VERSION ""

NS_ :

BS_:

BU_: GWM SCMB_PSM HVAC_RCCM GENERIC_GWMWakeup SOBDMD_AHCM_FOH TRM _delete SODL RTM PDM SCMH SCMG RSM SODR DDM RGTM DSM SCME TSTR
VAL_TABLE_ HvacCmprLim_D_Stat 7 "NotUsed_2" 6 "NotUsed_1" 5 "CompressorHeadPressure" 4 "AvailableTorque" 3 "PedalPosition" 2 "RPM" 1 "ECT" 0 "NoLimit" ;
VAL_TABLE_ NoMessage_Msg1_63 31 "Message31" 30 "Message30" 29 "Message29" 28 "Message28" 27 "Message27" 26 "Message26" 25 "Message25" 24 "Message24" 23 "Message23" 22 "Message22" 21 "Message21" 20 "Message20" 19 "Message19" 18 "Message18" 17 "Message17" 16 "Message16" 15 "Message15" 14 "Message14" 13 "Message13" 12 "Message12" 11 "Message11" 10 "Message10" 9 "Message9" 8 "Message8" 7 "Message7" 6 "Message6" 5 "Message5" 4 "Message4" 3 "Message3" 2 "Message2" 1 "Message1" 0 "NoMessage" ;
VAL_TABLE_ TrlrRvrseEnbl_D2_Stat 7 "NotUsed" 6 "TbaActiveExpertActive" 5 "TbaActiveExpertAvail" 4 "TbaOffTrgActive" 3 "TbaOffTrgSetup" 2 "TbaSetup" 1 "TbaActive" 0 "Inactive" ;
VAL_TABLE_ SwitchNotActive_Active 1 "Switch_Active" 0 "Switch_Not_Active" ;
VAL_TABLE_ LcwaLeft_D_Stat 7 "Faulty" 6 "NotUsed_3" 5 "NotUsed_2" 4 "NotUsed_1" 3 "Disabled" 2 "TemporaryUnavailable" 1 "SensorBlocked" 0 "Available" ;
VAL_TABLE_ SeatMasgDrvRr_D_Stat 15 "NotUsed_10" 14 "NotUsed_9" 13 "NotUsed_8" 12 "NotUsed_7" 11 "NotUsed_6" 10 "NotUsed_5" 9 "NotUsed_4" 8 "NotUsed_3" 7 "NotUsed_2" 6 "NotUsed_1" 5 "Pattern5" 4 "Pattern4" 3 "Pattern3" 2 "Pattern2" 1 "Pattern1" 0 "Null" ;
VAL_TABLE_ CamraRearOn_D2_Stat2 7 "Faulty" 6 "NotUsed_3" 5 "NotUsed_2" 4 "NotUsed_1" 3 "Decommission" 2 "Activate" 1 "Deactivate" 0 "Null" ;
VAL_TABLE_ AirCondClu_D_Stat 7 "NotUsed" 6 "FetLifeLimitReached" 5 "FetOpenCircuit" 4 "FetOutputShortToPower" 3 "FetOutputShortToGround" 2 "FetNotControlled" 1 "OnPowerToLoad" 0 "OffNoPowerToLoad" ;
VAL_TABLE_ OffNormalSoft 3 "NotUsed" 2 "Soft" 1 "Normal" 0 "Off" ;
VAL_TABLE_ OffOnDisabledInhibited 3 "Inhibited" 2 "Disabled" 1 "On" 0 "Off" ;
VAL_TABLE_ SldrrMsgTxt_D2_Rq 7 "NotUsed_3" 6 "NotUsed_2" 5 "NotUsed_1" 4 "SlidingDrCalibNeeded2" 3 "SlidingDrOpenCltchReleased" 2 "SlidingDrCalibNeeded" 1 "SlidingDrClutchReleased" 0 "Null" ;
VAL_TABLE_ SeatPsngrMem_D_Cmd 15 "NotUsed_7" 14 "NotUsed_6" 13 "NotUsed_5" 12 "NotUsed_4" 11 "NotUsed_3" 10 "NotUsed_2" 9 "NotUsed_1" 8 "RECALL_4" 7 "RECALL_3" 6 "RECALL_2" 5 "RECALL_1" 4 "STORE_4" 3 "STORE_3" 2 "STORE_2" 1 "STORE_1" 0 "Null" ;
VAL_TABLE_ Null_NoFault_Fault 3 "NotUsed" 2 "Fault" 1 "NoFault" 0 "Null" ;
VAL_TABLE_ PrkAsstSlotId_D_Stat 7 "Faulty" 6 "Slot6" 5 "Slot5" 4 "Slot4" 3 "Slot3" 2 "Slot2" 1 "Slot1" 0 "NoSlotFound" ;
VAL_TABLE_ PwStepLeft_D_Rq 1 "Deploy" 0 "Null" 3 "NotUsed" 2 "Stow" ;
VAL_TABLE_ SldrlUnlckSwtch_D_Stat 3 "InnerHandle" 2 "RearInteriorSwitch" 1 "IpSwitch" 0 "Null" ;
VAL_TABLE_ SldrlChime_D_Rq 7 "NotUsed3" 6 "NotUsed2" 5 "NotUsed1" 4 "Warning" 3 "WarningRepeated" 2 "Programming" 1 "Operation" 0 "Off" ;
VAL_TABLE_ Sldrl_D_Stat 3 "NotCalibrated" 2 "Closing" 1 "Opening" 0 "NotMoving" ;
VAL_TABLE_ BalrInnrLeft_D_Stat 3 "Reporting" 2 "NotReporting" 1 "SystemStandby" 0 "Initialization" ;
VAL_TABLE_ Zero_1_2_4 3 "Four" 2 "Two" 1 "One" 0 "Zero" ;
VAL_TABLE_ NoReq_AutoUp_Stop 3 "NotUsed" 2 "Stop" 1 "AutoUp" 0 "NoRequest" ;
VAL_TABLE_ BalrSnsLeft_D_Falt 3 "Invalid" 2 "SystemFailure" 1 "Blocked" 0 "Clear" ;
VAL_TABLE_ Null_Low_Med_High 3 "High" 2 "Medium" 1 "Low" 0 "Null" ;
VAL_TABLE_ Null_NotPressed_Pressed 3 "NotUsed" 2 "Pressed" 1 "NotPressed" 0 "Null" ;
VAL_TABLE_ Low_Med_High 3 "NotUsed" 2 "High" 1 "Medium" 0 "Low" ;
VAL_TABLE_ TrlrAidMsgTxt_D2_Rq 63 "Message63" 62 "Message62" 61 "Message61" 60 "Message60" 55 "Message55" 50 "Message50" 45 "Message45" 40 "Message40" 35 "Message35" 31 "Message31" 30 "Message30" 29 "Message29" 28 "Message28" 27 "Message27" 26 "Message26" 25 "Message25" 24 "Message24" 23 "Message23" 22 "Message22" 21 "Message21" 20 "Message20" 19 "Message19" 18 "Message18" 17 "Message17" 16 "Message16" 15 "Message15" 14 "Message14" 13 "Message13" 12 "Message12" 11 "Message11" 10 "Message10" 9 "Message9" 8 "Message8" 7 "Message7" 6 "Message6" 5 "Message5" 4 "Message4" 3 "Message3" 2 "Message2" 1 "Message1" 0 "NoMessage" ;
VAL_TABLE_ TrlrAidEnbl_D2_Stat 7 "NotUsed_1" 6 "TbaActiveExpertActive" 5 "TbaActiveExpertAvail" 4 "TbaOffTrgActive" 3 "TbaOffTrgSetup" 2 "TbaSetup" 1 "TbaActive" 0 "Inactive" ;
VAL_TABLE_ RbaCta_D_Stat 7 "Faulty" 6 "NotUsed_2" 5 "NotUsed_1" 4 "Invalid" 3 "Disabled" 2 "On" 1 "Trailer_Tow_Off" 0 "Off" ;
VAL_TABLE_ SeatFnChng2 15 "Faulty" 14 "NotUsed9" 13 "NotUsed8" 12 "NotUsed7" 11 "NotUsed6" 10 "High_2" 9 "Med_2" 8 "Low_2" 7 "Off_2" 6 "High" 5 "Low" 4 "Off" 3 "Decrease" 2 "Increase" 1 "NotUsed1" 0 "Inactive" ;
VAL_TABLE_ OffOnDisabledNotUsed 3 "NotUsed" 2 "Disabled" 1 "On" 0 "Off" ;
VAL_TABLE_ RbaSys_D_Stat 3 "Faulty" 2 "Available" 1 "Suspended" 0 "Disabled" ;
VAL_TABLE_ SeatLmbr_D_Rq 15 "NotUsed_7" 14 "NotUsed_6" 13 "NotUsed_5" 12 "NotUsed_4" 11 "NotUsed_3" 10 "NotUsed_2" 9 "NotUsed_1" 8 "PassengerDown" 7 "PassengerUp" 6 "PassengerAft" 5 "PassengerFore" 4 "DriverDown" 3 "DriverUp" 2 "DriverAft" 1 "DriverFore" 0 "Null" ;
VAL_TABLE_ Inactive_Enable_Disable 0 "Inactive" 2 "Disable" 1 "Enable" ;
VAL_TABLE_ PmSnsCabn_D_Stat 7 "NotUsed_1" 6 "IntermittentInhibit" 5 "NoIssue" 4 "BlankField" 3 "ReplaceSensor" 2 "CleanSensor" 1 "Unsupported" 0 "Initializing" ;
VAL_TABLE_ Null_Off_LowMedHigh 7 "NotUsed_3" 6 "NotUsed_2" 5 "NotUsed_1" 4 "High" 3 "Medium" 2 "Low" 1 "Off" 0 "Null" ;
VAL_TABLE_ SeatMasgDrv_D_Stat 15 "NotUsed_10" 14 "NotUsed_9" 13 "NotUsed_8" 12 "NotUsed_7" 11 "NotUsed_6" 10 "NotUsed_5" 9 "NotUsed_4" 8 "NotUsed_3" 7 "NotUsed_2" 6 "NotUsed_1" 5 "Pattern5" 4 "Pattern4" 3 "Pattern3" 2 "Pattern2" 1 "Pattern1" 0 "Null" ;
VAL_TABLE_ ClimtSeat_D_Rq 128 "H3_High_Heat_MAX" 64 "H2_Medium_Heat" 32 "H1_Low_Heat" 16 "C3_High_Cool_MAX" 8 "C2_Medium_Cool" 4 "C1_Low_Cool" 2 "Off" ;
VAL_TABLE_ ClimtRearView_D_Stat 3 "ThirdRow" 2 "SecondRow" 1 "Both" 0 "NotDisplayed" ;
VAL_TABLE_ PersRecallSrc_D_Actl 7 "NotUsed_3" 6 "NotUsed_2" 5 "NotUsed_1" 4 "MemorySwitch" 3 "RemoteStart" 2 "KeyFob" 1 "CenterStack" 0 "Null" ;
VAL_TABLE_ OKLowUnknownInvalid 3 "Invalid" 2 "Unknown" 1 "Low" 0 "OK" ;
VAL_TABLE_ Dsp_RotAddrBtnEv_St 15 "NotUsed_1" 14 "Pos_7Steps" 13 "Pos_6Steps" 12 "Pos_5Steps" 11 "Pos_4Steps" 10 "Pos_3Steps" 9 "Pos_2Steps" 8 "Pos_1Step" 7 "NotPressed" 6 "Neg_1Steps" 5 "Neg_2Steps" 4 "Neg_3Steps" 3 "Neg_4Steps" 2 "Neg_5Steps" 1 "Neg_6Steps" 0 "Neg_7Steps" ;
VAL_TABLE_ Pers1Phone_D_Stat 7 "SevenPhoneAssociated" 6 "SixPhoneAssociated" 5 "FivePhoneAssociated" 4 "FourPhoneAssociated" 3 "ThreePhoneAssociated" 2 "TwoPhoneAssociated" 1 "OnePhoneAssociated" 0 "NoPhoneAssociated" ;
VAL_TABLE_ GasPrtc_D_RqDsply 7 "NotUsed_5" 6 "NotUsed_4" 5 "NotUsed_3" 4 "NotUsed_2" 3 "NotUsed_1" 2 "GpfOverLimit" 1 "GpfAtLimit" 0 "NormalOperation" ;
VAL_TABLE_ Memory_2_SwPsngr_Stat 1 "Pressed" 0 "Null" ;
VAL_TABLE_ Pers3Key_D_Stat 3 "NotUsed_1" 2 "KeyUnAssociated" 1 "KeyAssociated" 0 "Null" ;
VAL_TABLE_ EmButtn_D_Stat 7 "ButtonAssociationFailed" 6 "ButtonAssociationExited" 5 "ButtonAssociationEntered" 4 "Button4Pressed" 3 "Button3Pressed" 2 "Button2Pressed" 1 "Button1Pressed" 0 "Null" ;
VAL_TABLE_ EmPrflButtnAssoc_D_Rq 3 "NotUsed" 2 "ExitButtonAssociation" 1 "EnterButtonAssociation" 0 "Null" ;
VAL_TABLE_ EmPrflNo_D_Stat 7 "NotUsed_3" 6 "NotUsed_2" 5 "NotUsed_1" 4 "Pers4" 3 "Pers3" 2 "Pers2" 1 "Pers1" 0 "Null" ;
VAL_TABLE_ EmPrflKeyAssoc_D_Stat 7 "WrongDevice" 6 "KeyAssociateFailed" 5 "KeyAssociateSuccess" 4 "KeyAlreadyInUse" 3 "KeyDisassociated" 2 "KeyAssociationExited" 1 "KeyAssociationEntered" 0 "Null" ;
VAL_TABLE_ PersNo_D_Actl 7 "Unused_3" 6 "Unused_2" 5 "NotDetermined" 4 "Vehicle" 3 "PERS_4" 2 "PERS_3" 1 "PERS_2" 0 "PERS_1" ;
VAL_TABLE_ Closed_Open_Active_Denied 3 "Denied" 2 "Active" 1 "Open" 0 "Closed" ;
VAL_TABLE_ KeyOffMde_D_Actl 15 "NotUsed_11" 14 "NotUsed_10" 13 "NotUsed_9" 12 "NotUsed_8" 11 "NotUsed_7" 10 "NotUsed_6" 9 "NotUsed_5" 8 "NotUsed_4" 7 "NotUsed_3" 6 "NotUsed_2" 5 "NotUsed_1" 4 "CriticalBattery" 3 "Hibernate" 2 "Transport" 1 "Factory" 0 "Normal" ;
VAL_TABLE_ SelDrvMdeSwtch 3 "Faulty" 2 "SwitchState2" 1 "SwitchState1" 0 "NotPressed" ;
VAL_TABLE_ SelDrvMdePt_D_Rq 31 "Faulty" 30 "NotUsed15" 29 "NotUsed14" 28 "NotUsed13" 27 "NotUsed12" 26 "NotUsed11" 25 "NotUsed10" 24 "NotUsed9" 23 "NotUsed8" 22 "NotUsed7" 21 "NotUsed6" 20 "NotUsed5" 19 "NotUsed4" 18 "EvLaterChargerMode" 17 "EvNowMode" 16 "DragMode" 15 "HighSpeedDesertMode_Baja" 14 "SportAdaptiveMode" 13 "NotAvailable_13" 12 "NotAvailable_12" 11 "NotAvailable_11" 10 "NotAvailable_10" 9 "RockCrawlMode" 8 "MudRutsMode" 7 "SandMode" 6 "EconomyMode" 5 "GrassGravelSnow" 4 "NotAvailable_04" 3 "TowHaulMode" 2 "NotAvailable_02" 1 "SportMode" 0 "NormalMode" ;
VAL_TABLE_ OffLockUnlockFaulty 3 "Faulty" 2 "Unlock" 1 "Lock" 0 "Off" ;
VAL_TABLE_ PwStep_D_Stat 3 "PositionNotKnown" 2 "StepsNotStowed" 1 "StepsStowed" 0 "Off" ;
VAL_TABLE_ PwStep_D_DrvInhbt 3 "NotUsed" 2 "DriveInhibitMalfunction" 1 "DriveInhibited" 0 "DriveNotInhibited" ;
VAL_TABLE_ PwStepMsgTxt_D_Rq 1 "DriveInhibited" 0 "NoMessage" 3 "NotUsed" 2 "Malfunction" ;
VAL_TABLE_ OffLowMedHigh 3 "High" 2 "Medium" 1 "Low" 0 "Off" ;
VAL_TABLE_ ApaSteScanMde_D_Stat 3 "Steering" 2 "Scanning" 1 "NotScanning" 0 "Null" ;
VAL_TABLE_ Off_On_Unknown_Invalid 3 "Invalid" 2 "Unknown" 1 "On" 0 "Off" ;
VAL_TABLE_ HeadLghtOn_D_Rq 7 "NotUsed2" 6 "NotUsed1" 5 "DrlBoth" 4 "DrlRight" 3 "DrlLeft" 2 "High" 1 "Low" 0 "Off" ;
VAL_TABLE_ SeatPos_D_Stat 7 "NotUsed3" 6 "NotUsed2" 5 "Error" 4 "Drive" 3 "Moving" 2 "Pending" 1 "EasyEntry" 0 "Null" ;
VAL_TABLE_ CtaAlrt2_D_Stat 7 "NotUsed3" 6 "NotUsed2" 5 "NotUsed1" 4 "AlertZone4" 3 "AlertZone3" 2 "AlertZone2" 1 "AlertZone1" 0 "Off" ;
VAL_TABLE_ BttRightLeft_D_Stat 7 "NotUsed" 6 "Disabled" 5 "Off" 4 "OffTemp" 3 "NotConnected" 2 "Pending" 1 "Connected" 0 "NotDetermined" ;
VAL_TABLE_ Null_NoRequest_Request 3 "NotUsed" 2 "Request" 1 "NoRequest" 0 "Null" ;
VAL_TABLE_ LghtAmbIntns_D_Sns 3 "Faulty" 2 "High" 1 "Low" 0 "Null" ;
VAL_TABLE_ ACU_RadioSeekMode2_St 16 "ContAutoDown" 15 "ContAutoUp" 14 "PISeek" 13 "TpSeek" 12 "Autostore" 11 "PtySeekDown" 10 "PtySeekUp" 9 "ScanDown" 8 "ScanUp" 7 "ContManualDown" 6 "ContManualUp" 5 "ManSingleStepDown" 4 "ManSingleStepUp" 3 "AutoDown" 2 "AutoUp" 1 "SeekOff" 0 "Invalid" ;
VAL_TABLE_ ACU_CurrTUBand_St 10 "SAT2" 9 "SAT1" 8 "DAB2" 7 "DAB1" 6 "Fm3" 5 "AmAst" 4 "Am" 3 "FmAst" 2 "Fm2" 1 "Fm1" 0 "Invalid" 13 "reserved1" 15 "reserved_last" 12 "DAB3" 11 "SAT3" ;
VAL_TABLE_ SuspDrvMde_D_Rq 7 "Faulty" 6 "NotUsed2" 5 "NotUsed1" 4 "Drag" 3 "Track" 2 "Snow_Wet" 1 "Sport" 0 "Normal" ;
VAL_TABLE_ NotPressed_PressedNotUsed 3 "NotUsed2" 2 "NotUsed1" 1 "Pressed" 0 "Not_Pressed" ;
VAL_TABLE_ NotInstalled_Installed_Faulty 3 "Faulty" 2 "NotUsed" 1 "Installed" 0 "NotInstalled" ;
VAL_TABLE_ CnvtTopMsgTxt_D_Rq 3 "NotSecure" 2 "NotAvailable" 1 "RemoveCaps" 0 "NoWarning" ;
VAL_TABLE_ NoModeSelOffOnNotUsed 3 "NotUsed" 2 "On" 1 "Off" 0 "NoModeSelected" ;
VAL_TABLE_ LsmcBrkDecel_D_Stat 7 "NotUsed_3" 6 "NotUsed_2" 5 "NotUsed_1" 4 "Denied" 3 "FaultDegraded" 2 "FaultExt" 1 "On" 0 "Off" ;
VAL_TABLE_ OffOn_RampUpDown 3 "Ramp_Down" 2 "Ramp_Up" 1 "On" 0 "Off" ;
VAL_TABLE_ Rr_Btn_Status 31 "NotUsed15" 30 "NotUsed14" 29 "NotUsed13" 28 "NotUsed12" 27 "NotUsed11" 26 "NotUsed10" 25 "NotUsed9" 24 "Third_Synch_Pressed" 23 "Third_Rr_Pwr_Pressed" 22 "Third_Auto_Pressed" 21 "Third_Pnl_Flr_Pressed" 20 "Third_Floor_Pressed" 19 "Third_Panel_Pressed" 18 "Third_Blwr_Dec_Pressed" 17 "Third_Blwr_Inc_Pressed" 16 "Rear_Lock_Pressed" 15 "RHS_Cld_Seat_Pressed" 14 "LHS_Cld_Seat_Pressed" 13 "RHS_Htd_Seat_Pressed" 12 "LHS_Htd_Seat_Pressed" 11 "Rear_Power_Pressed" 10 "AUTO_Pressed" 9 "Blwr_Dec_Pressed" 8 "Blwr_Inc_Pressed" 7 "RHS_Temp_Dec_Pressed" 6 "RHS_Temp_Inc_Pressed" 5 "LHS_Temp_Dec_Pressed" 4 "LHS_Temp_Inc_Pressed" 3 "Floor_Pressed" 2 "Panel_Floor_Pressed" 1 "Panel_Pressed" 0 "None_Pressed" ;
VAL_TABLE_ NoMessage_Msg1_7 7 "Message7" 6 "Message6" 5 "Message5" 4 "Message4" 3 "Message3" 2 "Message2" 1 "Message1" 0 "NoMessage" ;
VAL_TABLE_ LnchCtl 3 "NotUsed2" 2 "NotUsed1" 1 "LC_On" 0 "LC_Off" ;
VAL_TABLE_ LnchCtlSys_D_Stat 7 "NotUsed3" 6 "NotUsed2" 5 "NotUsed1" 4 "On_LC_Unavailable_TC_On" 3 "On_LC_Unavailable" 2 "On_LC_Available" 1 "On_LC_Active" 0 "LC_OFF" ;
VAL_TABLE_ NotPressed_Pressed_Faulty 3 "Faulty" 2 "NotUsed" 1 "Pressed" 0 "Not_Pressed" ;
VAL_TABLE_ IsaOffst_D_Stat 15 "Faulty" 14 "Null" 13 "Thirteen" 12 "Twelve" 11 "Eleven" 10 "Ten" 9 "Nine" 8 "Eight" 7 "Seven" 6 "Six" 5 "Five" 4 "Four" 3 "Three" 2 "Two" 1 "One" 0 "Zero" ;
VAL_TABLE_ SlMde_D_Rq 3 "IsaNotConfigured" 2 "Manual_Mode" 1 "Auto_Mode" 0 "Null" ;
VAL_TABLE_ OffOn_NotUsed_NoData 3 "No_Data_Present" 2 "NotUsed" 1 "On" 0 "Off" ;
VAL_TABLE_ BrkDrvMde_D_Rq 7 "Faulty" 6 "RockCrawl" 5 "Baja" 4 "DragOrMudAndSand" 3 "Track" 2 "Snow_Wet" 1 "Sport" 0 "Normal" ;
VAL_TABLE_ Null_Off_On 3 "NotUsed" 2 "On" 1 "Off" 0 "Null" ;
VAL_TABLE_ Faulty_1FFF 8191 "Faulty" ;
VAL_TABLE_ VehStab_D_Stat 15 "Faulty" 14 "No_Data_Exists" 13 "NotUsed6" 12 "NotUsed5" 11 "NotUsed4" 10 "NotUsed3" 9 "NotUsed2" 8 "NotUsed1" 7 "High_SSRA_no_OS" 6 "Straight" 5 "Post_Oversteer" 4 "Post_Transition" 3 "Countersteer" 2 "Understeer" 1 "Oversteer" 0 "Linear" ;
VAL_TABLE_ CnvtTopTrgt_D_Rq 7 "NotUsed4" 6 "NotUsed3" 5 "NotUsed2" 4 "NotUsed1" 3 "OpenTarget" 2 "OpenPosition" 1 "ClosePosition" 0 "CloseTarget" ;
VAL_TABLE_ CnvtTopPos_D_Stat 15 "Faulty" 14 "NotUsed7" 13 "NotUsed6" 12 "NotUsed5" 11 "NotUsed4" 10 "NotUsed3" 9 "NotUsed2" 8 "NotUsed1" 7 "ShutdownComplete" 6 "NoNormalised" 5 "Moving" 4 "PositionIntermediate" 3 "PositionOpenTarget" 2 "PositionOpenPosition" 1 "PositionClosePosition" 0 "PositionCloseTarget" ;
VAL_TABLE_ CnvtTopPar_D_Rq 7 "NotUsed" 6 "ForceIncrease3" 5 "ForceIncrease2" 4 "ForceIncrease1" 3 "NoAdapt" 2 "Teach" 1 "NoPwmNoAp" 0 "Normal" ;
VAL_TABLE_ CnvtTopComplt_D_Stat 7 "DenormalizingReady" 6 "NormalizingReady" 5 "RunoutComplete" 4 "StopByPositioning" 3 "StopByFault" 2 "StopByPinch" 1 "StopByStall" 0 "StopByRequest" ;
VAL_TABLE_ Inactive_Active_NotUsed_Faulty 3 "Faulty" 2 "NotUsed" 1 "Active" 0 "Inactive" ;
VAL_TABLE_ CnvtTop_D_Rq 7 "NotUsed" 6 "ResetErrorFlags" 5 "DiscardNormalization" 4 "SetNormalization" 3 "DirectDriveClose" 2 "DirectDriveOpen" 1 "DirectPosition" 0 "Stop" ;
VAL_TABLE_ NoData_Faulty_1FF_1FE 511 "Faulty" 510 "NoDataExists" ;
VAL_TABLE_ FohEng_D_Rq 3 "AutoEnable_ParkEnable" 2 "AutoDisable_ParkEnable" 1 "AutoEnable_ParkDisable" 0 "Disable_Stop" ;
VAL_TABLE_ Null_Hi_NotUsed_Low 3 "Low" 2 "Not_Used" 1 "High" 0 "Null" ;
VAL_TABLE_ Current_Color 15 "NotUsed7" 14 "NotUsed6" 13 "NotUsed5" 12 "NotUsed4" 11 "NotUsed3" 10 "NotUsed2" 9 "NotUsed1" 8 "Null" 7 "Color7" 6 "Color6" 5 "Color5" 4 "Color4" 3 "Color3" 2 "Color2" 1 "Color1" 0 "Off" ;
VAL_TABLE_ Blended_Color 15 "NotUsed10" 14 "NotUsed9" 13 "NotUsed8" 12 "NotUsed7" 11 "NotUsed6" 10 "NotUsed5" 9 "NotUsed4" 8 "NotUsed3" 7 "NotUsed2" 6 "NotUsed1" 5 "_5" 4 "_4" 3 "_3" 2 "_2" 1 "_1" 0 "Null" ;
VAL_TABLE_ OffOn_Null_NotUsed 3 "NotUsed" 2 "Null" 1 "On" 0 "Off" ;
VAL_TABLE_ Null_Pers1_4_Vehicle 7 "Unused_2" 6 "Unused_1" 5 "Vehicle" 4 "PERS_4" 3 "PERS_3" 2 "PERS_2" 1 "PERS_1" 0 "Null" ;
VAL_TABLE_ VehKeyActv_D_Stat 15 "NotUsed7" 14 "NotUsed6" 13 "NotUsed5" 12 "NotUsed4" 11 "NotUsed3" 10 "NotUsed2" 9 "NotUsed1" 8 "Key8Active" 7 "Key7Active" 6 "Key6Active" 5 "Key5Active" 4 "Key4Active" 3 "Key3Active" 2 "Key2Active" 1 "Key1Active" 0 "NoKeyActive" ;
VAL_TABLE_ VehLckInd_D_Rq 3 "NotUsed" 2 "On_Day" 1 "On_Night" 0 "Off" ;
VAL_TABLE_ TowBarMsgTxt_D_Rq 7 "NotUsed3" 6 "NotUsed2" 5 "NotUsed1" 4 "TowBar_Ext_No_Trlr" 3 "Error_Dealer_Fix" 2 "Start_Engine_Swivel" 1 "Check_Tow_Bar" 0 "Null" ;
VAL_TABLE_ SeatFnChng 15 "Faulty" 14 "NotUsed9" 13 "NotUsed8" 12 "NotUsed7" 11 "NotUsed6" 10 "NotUsed5" 9 "NotUsed4" 8 "NotUsed3" 7 "NotUsed2" 6 "High" 5 "Low" 4 "Off" 3 "Decrease" 2 "Increase" 1 "NotUsed1" 0 "Inactive" ;
VAL_TABLE_ NoData_Faulty_3E_3F 63 "Faulty" 62 "NoDataExists" ;
VAL_TABLE_ InactiveIncrementDecrement 3 "NotUsed" 2 "Decrement" 1 "Increment" 0 "Inactive" ;
VAL_TABLE_ Faulty_1FF 511 "Faulty" ;
VAL_TABLE_ Null_Off_On_Faulty 3 "Faulty" 2 "On" 1 "Off" 0 "Null" ;
VAL_TABLE_ Faulty_3FF 1023 "Faulty" ;
VAL_TABLE_ DynoMde_B_Cmd 1 "Two_Wheel_Dyno" 0 "Normal_Operation" ;
VAL_TABLE_ HvacPrecondRecirc_D_Rq 3 "Last_User_Setting" 2 "Auto" 1 "Recirc" 0 "Outside" ;
VAL_TABLE_ HvacPrecondAC_D_Rq 3 "Last_User_Setting" 2 "Auto" 1 "On" 0 "Off" ;
VAL_TABLE_ HybMdeStat_D_Dsply 7 "NotUsed2" 6 "EV_Charge" 5 "EV_Override" 4 "Forced_EV_Mode" 3 "Forced_Charge_Sustain_Mode" 2 "Auto_Charge_Sustain_Mode" 1 "Auto_Charge_Deplete_Mode" 0 "Null_State" ;
VAL_TABLE_ NoData_Faulty_FFFE_FFFF 65535 "Faulty" 65534 "NoDataExists" ;
VAL_TABLE_ NoData_Faulty_FFE_FFF 4095 "Faulty" 4094 "NoDataExists" ;
VAL_TABLE_ PepsKeyActv_D_Stat 15 "NotUsed11" 14 "NotUsed10" 13 "NotUsed9" 12 "NotUsed8" 11 "NotUsed7" 10 "NotUsed6" 9 "NotUsed5" 8 "Key4Active" 7 "NotUsed4" 6 "NotUsed3" 5 "NotUsed2" 4 "Key3Active" 3 "NotUsed1" 2 "Key2Active" 1 "Key1Active" 0 "NoKeyActive" ;
VAL_TABLE_ CellLock_D_Rq 7 "NotUsed3" 6 "NotUsed2" 5 "NotUsed1" 4 "TrunkRelPopGlassLgCargo" 3 "LockAllDoorsandTailgate" 2 "UnlockDriversDoor" 1 "UnlockAllDoorsandTailgate" 0 "NoRequest" ;
VAL_TABLE_ DrTgateChime2_D_Rq 7 "NotUsed3" 6 "NotUsed2" 5 "NotUsed1" 4 "Long_Repeated" 3 "Fast" 2 "Short" 1 "Long" 0 "Off" ;
VAL_TABLE_ StopStrtDrvMde_D_Indic 3 "NotUsed" 2 "StartStop_IndirectDeselect" 1 "StopStart_Deselected" 0 "StopStart_Selected" ;
VAL_TABLE_ StopStrtStdby_D_Indic 6 "NotUsed2" 5 "Telltale_Struck_Out" 4 "Telltale_Flashing_Amber" 3 "Telltale_On_Amber" 2 "Telltale_Flashing_Green" 1 "Telltale_On_Green" 0 "Telltale_Off" 7 "NotUsed3" ;
VAL_TABLE_ Quality_Faulty 3 "OK" 2 "Degraded" 1 "No_Data_Exists" 0 "Faulty" ;
VAL_TABLE_ CtaInnr_D_Stat 3 "Reporting" 2 "Not_Reporting" 1 "System_Standby" 0 "Initialization" ;
VAL_TABLE_ FohMsgTxt_D_Rq 4 "BatteryNotFullyCharged" 3 "Exceed7DaysFromLastEngRun" 2 "AmbientTemperatureTooHigh" 1 "LowFuel" 0 "NoMessage" ;
VAL_TABLE_ FohStrtDay_T_Rq 7 "Sunday" 6 "Saturday" 5 "Friday" 4 "Thursday" 3 "Wednesday" 2 "Tuesday" 1 "Monday" 0 "NotUsed" ;
VAL_TABLE_ DisableEnableNotUsedUnknown 3 "Unknown" 2 "NotUsed" 1 "Enable" 0 "Disable" ;
VAL_TABLE_ NoRequest_Request 1 "Request" 0 "NoRequest" ;
VAL_TABLE_ Foh_D_Stat 7 "Unused3" 6 "Unused2" 5 "Unused1" 4 "Stopping" 3 "Running" 2 "Starting" 1 "Prestart" 0 "Off" ;
VAL_TABLE_ ActiveStoragePassenger 7 "Unused3" 6 "Unused2" 5 "Unused1" 4 "StoreDipMemoryButton4" 3 "StoreDipMemoryButton3" 2 "StoreDipMemoryButton2" 1 "StoreDipMemoryButton1" 0 "Off" ;
VAL_TABLE_ DipMirror 1 "Dipped" 0 "Off" ;
VAL_TABLE_ WindowCmd 7 "Unused2" 6 "Unused1" 5 "NotDefined" 4 "Audo_Down" 3 "Manual_Down" 2 "Auto_Up" 1 "Manual_Up" 0 "Idle" ;
VAL_TABLE_ MirrorCmd 7 "Unused" 6 "Unfold" 5 "Fold" 4 "Right" 3 "Left" 2 "Down" 1 "Up" 0 "Idle" ;
VAL_TABLE_ WindowPosition 7 "Unused2" 6 "Unused1" 5 "Fully_Open" 4 "Bet60Percent_FullyOpen" 3 "Bet10Percent_60Percent" 2 "BetFully_10PercentOpen" 1 "Fully_Closed" 0 "Undefined" ;
VAL_TABLE_ OffOnNoDataUnused 3 "Unused" 2 "NoDataExists" 1 "On" 0 "Off" ;
VAL_TABLE_ FohFalt_D_Stat 15 "NotUsed4" 14 "NotUsed3" 13 "NotUsed2" 12 "NotUsed1" 11 "FuelTypeDoesNotMatchFOH" 10 "Lifecycle_ModeNotSet" 9 "AuxElectricCoolantPumpInop" 8 "TimeDelayAvoidExcessCycl" 7 "Fuel_Level_OutofRange" 6 "External_Fault" 5 "Internal_Fault" 4 "Voltage_limitation" 3 "Impact_Event" 2 "CoolantTemp_OutofRange" 1 "AmbientTemp_OutofRange" 0 "No_Disable" ;
VAL_TABLE_ FohRqRun_B_Rq 1 "SubmitRequest_toRun" 0 "DoesNotSubmitRequest_toRun" ;
VAL_TABLE_ SteWhlHeat 15 "NotUsed6" 14 "NotUsed5" 13 "NotUsed4" 12 "NotUsed3" 11 "NotUsed2" 10 "NotUsed1" 9 "Reserved_3" 8 "Reserved_2" 7 "Reserved_1" 6 "Level_3_Heating" 5 "Level_3_Heating_LS" 4 "Level_2_Heating" 3 "Level_2_Heating_LS" 2 "Level_1_Heating" 1 "Level_1_Heating_LS" 0 "Off" ;
VAL_TABLE_ OffOnUnusedFault 3 "Fault" 2 "Unused" 1 "On" 0 "Off" ;
VAL_TABLE_ EngineBrakeOff_Active 1 "Engine_Braking_Activated" 0 "Engine_Braking_Off" ;
VAL_TABLE_ Allowed_Denied 1 "Denied" 0 "Allowed" ;
VAL_TABLE_ PrkAidSns_D_Stat 15 "Zone_15" 14 "Zone_14" 13 "Zone_13" 12 "Zone_12" 11 "Zone_11" 10 "Zone_10" 9 "Zone_9" 8 "Zone_8" 7 "Zone_7" 6 "Zone_6" 5 "Zone_5" 4 "Zone_4" 3 "Zone_3" 2 "Zone_2" 1 "Zone_1" 0 "Off" ;
VAL_TABLE_ PrkAid_D_Falt 7 "NotUsed2" 6 "NotUsed1" 5 "Failure_Front_PSM_Sensors" 4 "No_Data_Exists" 3 "Failure_Rear_Sensors" 2 "Speaker_Fault" 1 "ECU_Fault" 0 "No_Fault" ;
VAL_TABLE_ ApaMde_D_Stat 7 "NotUsed3" 6 "NotUsed2" 5 "NotUsed1" 4 "POA" 3 "PPA" 2 "SAPP" 1 "Off" 0 "Null" ;
VAL_TABLE_ _7F_Null 127 "Null" ;
VAL_TABLE_ SeatFnDrv_D_Rq 7 "CushionMassage" 6 "LumbarMassage" 5 "UpperBolster" 4 "LowerBolster" 3 "UpperLumbar" 2 "MiddleLumbar" 1 "LowerLumbar" 0 "Inactive" ;
VAL_TABLE_ Inactive_IncreaseDecrease 2 "Decrease" 1 "Increase" 0 "Inactive" ;
VAL_TABLE_ MemFeedback 8 "Recall_4" 7 "Recall_3" 6 "Recall_2" 5 "Recall_1" 4 "Store_4" 3 "Store_3" 2 "Store_2" 1 "Store_1" 0 "Inactive" ;
VAL_TABLE_ Null_Off_LowHigh 3 "High" 2 "Low" 1 "Off" 0 "Null" ;
VAL_TABLE_ NotUpdate_Update 1 "Updating" 0 "NotUpdating" ;
VAL_TABLE_ SeatFnDrv_D_Stat 7 "CushionMassage" 6 "LumbarMassage" 5 "UpperBolster" 4 "LowerBolster" 3 "UpperLumbar" 2 "MiddleLumbar" 1 "LowerLumbar" 0 "Null" ;
VAL_TABLE_ GearRvrse_D_Actl 7 "Fault" 6 "NotUsed_3" 5 "NotUsed_2" 4 "NotUsed_1" 3 "Active_confirmed" 2 "Active_not_confirmed" 1 "Inactive_confirmed" 0 "Inactive_not_confirmed" ;
VAL_TABLE_ SideDetect_SnStat_Invalid 3 "Invalid" 2 "System_Failure" 1 "Blocked" 0 "Clear" ;
VAL_TABLE_ SideDetect_OpStat 7 "NotUsed_3" 6 "NotUsed_2" 5 "NotUsed_1" 4 "Invalid" 3 "Disabled" 2 "On" 1 "Trailer_Tow_Off" 0 "Off" ;
VAL_TABLE_ SideDetect_Present 4 "Sensor_Blocked" 3 "Sensor_Fault" 2 "Flash_On" 1 "Alert_On" 0 "AlertOff_FlashOff_SensrClr" ;
VAL_TABLE_ Off_On_Flash_BulbProveout 3 "Bulb_Proveout" 2 "Flash" 1 "On" 0 "Off" ;
VAL_TABLE_ SideDetect_BLIS_Off_On 2 "BLIS_On_Second_Warning_ON" 1 "BLIS_On_Second_Warning_OFF" 0 "Off" ;
VAL_TABLE_ SideDetect_report 3 "Reporting" 2 "Not_Reporting" 1 "System_Standby" 0 "Initialization" ;
VAL_TABLE_ DrTGate_D_Rq 3 "NotUsed" 2 "Closing" 1 "Opening" 0 "Not_Moving" ;
VAL_TABLE_ WndwSide_D_Stat 3 "BothWindow_Operating" 2 "RearWindow_Operating" 1 "FrontWindow_Operating" 0 "NoWindows_Operating" ;
VAL_TABLE_ False_True 1 "True" 0 "False" ;
VAL_TABLE_ Null_Up_Down 3 "Unused" 2 "Down" 1 "Up" 0 "Null" ;
VAL_TABLE_ Null_Fwd_Rwd 3 "Unused" 2 "Rearward" 1 "Forward" 0 "Null" ;
VAL_TABLE_ Null_Ack_Nack_NotUsed 3 "Not_Used" 2 "Nack" 1 "Ack" 0 "Null" ;
VAL_TABLE_ HvacBlwrFront_D_Stat 31 "Not_Used" 20 "Full_On" 19 "95_Percent" 18 "90_Percent" 17 "85_Percent" 16 "80_Percent" 15 "75_Percent" 14 "70_Percent" 13 "65_Percent" 12 "60_Percent" 11 "55_Percent" 10 "50_Percent" 9 "45_Percent" 8 "40_Percent" 7 "35_Percent" 6 "30_Percent" 5 "25_Percent" 4 "20_Percent" 3 "15_Percent" 2 "10_Percent" 1 "5_Percent" 0 "Off" ;
VAL_TABLE_ ACU_ARAudioSource_Rsp 15 "iPod" 14 "USB" 13 "BTAudio" 0 "AmfmRadio" 1 "FrontDisc" 2 "SDARS_DAB" 3 "InDashCdChanger" 4 "VoiceRecogniser" 5 "TelematicUnit" 6 "BluetoothPhone" 7 "RearDisc" 8 "APIM" 9 "FrontAuxInput" 10 "Navigation" 11 "RearAux" 12 "NotReq" ;
VAL_TABLE_ ACU_AROperationType_Rsp 0 "Inactive" 1 "Requestaudioresource" 2 "Releaseaudioresource" 3 "Releaseallaudioresouces" 4 "Getresourceupdate" 5 "Getallresourceupdates" ;
VAL_TABLE_ ACU_ARResponse_Rsp 0 "Inactive" 1 "RequestAccepted" 2 "RequestAcceptedWoCtrl" 3 "RequestDenied" 4 "RessourceUpdateStatus" ;
VAL_TABLE_ ACU_ARReqstrPriority_Rp 0 "EmergencyServ" 1 "TelService" 2 "AutoAnswer" 3 "Ta" 4 "PttMutevoice" 5 "NavUserVoiceCmd" 6 "NavSysVoiceCmd" 7 "Radio" 8 "Disc" 9 "Alarm" 10 "Ptynews" 11 "Aux_ExtSource" 12 "MobileNavAndTelMute" 13 "ManualAudioMute" 14 "NotReq" ;
VAL_TABLE_ ACU_RUAudioSource_St 15 "iPod" 14 "USB" 13 "BTAudio" 0 "AmfmRadio" 1 "FrontDisc" 2 "SDARS_DAB" 3 "InDashCdChanger" 4 "VoiceRecogniser" 5 "TelematicUnit" 6 "BluetoothPhone" 7 "RearDisc" 8 "APIM" 9 "FrontAuxInput" 10 "Navigation" 11 "RearAux" 12 "NotReq" ;
VAL_TABLE_ FrontRequest_RearRequest 0 "FrontRequester" 1 "RearRequester" ;
VAL_TABLE_ ACU_RUResReqstStatus_St 0 "NoResourceupdate" 1 "Deallocated" 2 "Allocated" 3 "Stacked" 4 "Granted" 5 "GrantedNoControlOfAudioSrc" ;
VAL_TABLE_ ACU_RUReqstrPriority_St 0 "EmergencyServ" 1 "TelService" 2 "AutoAnswer" 3 "Ta" 4 "PttMutevoice" 5 "NavUserVoiceCmd" 6 "NavSysVoiceCmd" 7 "Radio" 8 "Disc" 9 "Alarm" 10 "Ptynews" 11 "Aux_ExtSource" 12 "MobileNavAndTelMute" 13 "ManualAudioMute" 14 "NotReq" ;
VAL_TABLE_ NoData_Faulty_7E_7F 127 "Faulty" 126 "NoDataExists" ;
VAL_TABLE_ Diagnostic_Operation_Rq 7 "SignalStrength" 6 "SDARSESNNumber" 5 "SpeakerWalkAround" 4 "CalibrationPartNumber" 15 "Reserved" 3 "HardwarePartNumber" 2 "SoftwarePartNumber" 1 "GetAllBackgroundDiagRq" 0 "Inactive" ;
VAL_TABLE_ Bezel_Diag_Module_Rq 15 "Reserved" 3 "EFP" 2 "DSP_AMP" 1 "AHU" 0 "Inactive" ;
VAL_TABLE_ HMI_HMIMode_St 7 "NotUsed2" 6 "NotUsed1" 5 "Load_Shed_Active" 0 "Invalid" 1 "OffMode" 2 "On" 3 "Phone" 4 "Climate" ;
VAL_TABLE_ PrmtrAlrmEvnt_D_Stat 15 "Diag_Tamper" 14 "Trailer" 13 "Shock_Sensor" 12 "Post_Crash" 11 "Panic" 10 "Intrusion" 9 "Inclination" 8 "Ign_Tamper" 7 "LG_Door" 6 "Decklid" 5 "Hood" 4 "PR_Door" 3 "PF_Door" 2 "DR_Door" 1 "DF_Door" 0 "Null" ;
VAL_TABLE_ PtcHtr_D_Cmd 3 "TurnOn" 2 "AutoMode" 1 "TurnOff" 0 "NoDecision_Initializing" ;
VAL_TABLE_ NoData_Fault_FFFE_FFFF 65535 "Fault" 65534 "NoDataExists" ;
VAL_TABLE_ TrlrBattChrg_D_Stat 3 "Reverse" 2 "Normal" 1 "Low" 0 "Null" ;
VAL_TABLE_ TrlrLampCtl_D_Stat 3 "NotUsed" 2 "TrlrLampCnnctDrvFailure" 1 "TrlrLampNotCnnctDrvFailure" 0 "Null" ;
VAL_TABLE_ ElPw_D_StatStrtStop 15 "NotUsed6" 14 "NotUsed5" 13 "NotUsed4" 12 "NotUsed3" 11 "NotUsed2" 10 "NotUsed1" 9 "Supported_Level_4" 8 "Supported_Level_3" 7 "Supported_Level_2" 6 "Supported_Level_1" 5 "Limited_Support" 4 "Fault_Limited" 3 "LV_Event_in_Progress" 2 "Not_Supported_Imminent" 1 "Supported_All" 0 "Not_Supported" ;
VAL_TABLE_ ImpactEvntFdbck_D_Stat 3 "NotUsed" 2 "EventComplete" 1 "EventInProgress" 0 "Normal" ;
VAL_TABLE_ NoData_Fault_3E_3F 63 "Fault" 62 "NoDataExists" ;
VAL_TABLE_ Null_Open 1 "Open" 0 "Null" ;
VAL_TABLE_ TempDegreesC_DegreesF 0 "Temperature_deg_c" 1 "Temperature_deg_f" ;
VAL_TABLE_ Temp_Detents 15 "Unused5" 14 "Unused4" 13 "Unused3" 12 "Unused2" 11 "Unused1" 10 "Display_Blank" 9 "_4_Heat_Bars" 8 "_3_Heat_Bars" 7 "_2_Heat_Bars" 6 "_1_Heat_Bar" 5 "Neutral_Bar_Only" 4 "_1_Cool_Bar" 3 "_2_Cool_Bars" 2 "_3_Cool_Bars" 1 "_4_Cool_Bars" 0 "No_Bars" ;
VAL_TABLE_ Set_Temp_Dig3 2 "_5" 1 "_0" 0 "Off" ;
VAL_TABLE_ Set_Temp_Dig 15 "Blank6" 14 "Blank5" 13 "Blank4" 12 "Blank3" 11 "Blank2" 10 "Blank1" 9 "_9" 8 "_8" 7 "_7" 6 "_6" 5 "_5" 4 "_4" 3 "_3" 2 "_2" 1 "_1" 0 "_0" ;
VAL_TABLE_ Btn_Status 31 "NotUsed_7" 30 "NotUsed_6" 29 "NotUsed_5" 28 "NotUsed_4" 27 "NotUsed_3" 26 "NotUsed_2" 25 "NotUsed_1" 24 "Third_Sync_Pressed" 23 "Third_Rr_Pwr_Pressed" 22 "Third_Auto_Pressed" 21 "Third_Pnl_Flr_Pressed" 20 "Third_Floor_Pressed" 19 "Third_Panel_Pressed" 18 "Third_Blwr_Dec_Pressed" 17 "Third_Blwr_Inc_Pressed" 16 "Rear_Lock_Pressed" 15 "RHS_Cld_Seat_Pressed" 14 "LHS_Cld_Seat_Pressed" 13 "RHS_Htd_Seat_Pressed" 12 "LHS_Htd_Seat_Pressed" 11 "Rear_Power_Pressed" 10 "AUTO_Pressed" 9 "Blwr_Dec_Pressed" 8 "Blwr_Inc_Pressed" 7 "RHS_Temp_Dec_Pressed" 6 "RHS_Temp_Inc_Pressed" 5 "LHS_Temp_Dec_Pressed" 4 "LHS_Temp_Inc_Pressed" 3 "Floor_Pressed" 2 "Panel_Floor_Pressed" 1 "Panel_Pressed" 0 "None_Pressed" ;
VAL_TABLE_ Cond_Seat_Status 7 "Unused" 6 "Level_3_Heating" 5 "Level_2_Heating" 4 "Level_1_Heating" 3 "Level_3_Cooling" 2 "Level_2_Cooling" 1 "Level_1_Cooling" 0 "Off" ;
VAL_TABLE_ Htd_Strg_Whl_Status 3 "Level_3_Heating" 2 "Level_2_Heating" 1 "Level_1_Heating" 0 "Off" ;
VAL_TABLE_ Frt_Btn_Status_1st 36 "MdeMnu_Pressed" 35 "AAR_Pressed" 34 "Heat_Pressed" 33 "RearMnu_Pressed" 32 "FrontMnu_Pressed" 31 "Defrost_Pressed" 30 "Htg_Strg_Whl_Pressed" 29 "RHS_Cld_Seat_Pressed" 28 "LHS_Cld_Seat_Pressed" 27 "RHS_Htd_Seat_Pressed" 26 "LHS_Htd_Seat_Pressed" 25 "Max_Defrost_Pressed" 24 "My_Temp_Pressed" 23 "Front_Power_Pressed" 22 "Rear_Defrost_Pressed" 21 "Pnl_Flr_Ws_Pressed" 20 "Pnl_Ws_Pressed" 19 "Windscreen_Pressed" 18 "Htd_Frt_Wsh_Pressed" 17 "Auto_Recirc_Pressed" 16 "Outside_Pressed" 15 "Recirc_Pressed" 14 "Max_AC_Pressed" 13 "AUTO_Pressed" 12 "Blwr_Dec_Pressed" 11 "Blwr_Inc_Pressed" 10 "RHS_Temp_Dec_Pressed" 9 "RHS_Temp_Inc_Pressed" 8 "LHS_Temp_Dec_Pressed" 7 "LHS_Temp_Inc_Pressed" 6 "Dual_Pressed" 5 "AC_Pressed" 4 "Floor_Ws_Pressed" 3 "Floor_Pressed" 2 "Panel_Floor_Pressed" 1 "Panel_Pressed" 0 "None_Pressed" ;
VAL_TABLE_ Frt_Blower_Speed 3 "NotUsed" 2 "Max_Blower" 1 "Min_Blower" 0 "No_Request" ;
VAL_TABLE_ Blower_Indicate 15 "Display_Blank" 14 "14_Indicators_On" 13 "13_Indicators_On" 12 "12_Indicators_On" 11 "11_Indicators_On" 10 "10_Indicators_On" 9 "9_Indicators_On" 8 "8_Indicators_On" 7 "7_Indicators_On" 6 "6_Indicators_On" 5 "5_Indicators_On" 4 "4_Indicators_On" 3 "3_Indicators_On" 2 "2_Indicators_On" 1 "1_Indicator_On" 0 "Indicators_Off" ;
VAL_TABLE_ Front_AUTO_Label 3 "Full" 2 "Mode" 1 "Blower" 0 "Off" ;
VAL_TABLE_ Drv_Set_Temp 31 "HI" 30 "29_5" 29 "29_0" 28 "28_5" 27 "28_0" 26 "27_5" 25 "27_0" 24 "26_5" 23 "26_0" 22 "25_5" 21 "25_0" 20 "24_5" 19 "24_0" 18 "23_5" 17 "23_0" 16 "22_5" 15 "22_0" 14 "21_5" 13 "21_0" 12 "20_5" 11 "20_0" 10 "19_5" 9 "19_0" 8 "18_5" 7 "18_0" 6 "17_5" 5 "17_0" 4 "16_5" 3 "16_0" 2 "15_5" 1 "LO" 0 "No_Request" ;
VAL_TABLE_ CC_Fr_Stat_User_Adj 7 "Unused4" 6 "Unused3" 5 "Unused2" 4 "Unused1" 3 "Fr_Blwr_Spd_Selection" 2 "FRHS_SetPt_Selection" 1 "FLHS_SetPt_Selection" 0 "None" ;
VAL_TABLE_ CC_Rr_Stat_User_Adj 15 "Unused9" 14 "Unused8" 13 "Unused7" 12 "Unused6" 11 "Unused5" 10 "Unused4" 9 "Unused3" 8 "Unused2" 7 "Unused1" 6 "Rr_Auto_Selection" 5 "Rr_Control_Selection" 4 "Rr_Power_Selection" 3 "Rr_Blwr_Spd_Selection" 2 "RRHS_SetPt_Selection" 1 "RLHS_SetPt_Selection" 0 "None" ;
VAL_TABLE_ CC_Fr_Btn_User_Adj 31 "Unused15" 30 "Unused14" 29 "Unused13" 28 "Unused12" 27 "Unused11" 26 "Unused10" 25 "Unused9" 24 "Unused8" 23 "Unused7" 22 "Unused6" 21 "Unused5" 20 "Unused4" 19 "UFC_Interrupted" 18 "UFC_Complete" 17 "UFC_Active" 16 "Htd_WS_Selection" 15 "FLR_Cnd_St_Selection" 14 "FLH_Cnd_St_Selection" 13 "HSW_Selection" 12 "Dual_Selection" 11 "Rear_Defrost_Selection" 10 "Max_Defrost_Selection" 9 "Defrost_Selection" 8 "Fr_Air_Dist_Selection" 7 "Max_AC_Selection" 6 "Fr_Power_Selection" 5 "Recirc_Selection" 4 "AC_Selection" 3 "Fr_Auto_Selection" 2 "Use_MyTemp_Selection" 1 "Save_MyTemp_Selection" 0 "None" ;
VAL_TABLE_ HeadLghtHiFdbck_D_Stat 3 "NotUsed" 2 "Cancel" 1 "Hold" 0 "Allow_Change" ;
VAL_TABLE_ Backlit_LED_Status 15 "Unused3" 14 "Unused2" 13 "Unused1" 12 "Night_12" 11 "Night_11" 10 "Night_10" 9 "Night_9" 8 "Night_8" 7 "Night_7" 6 "Night_6" 5 "Night_5" 4 "Night_4" 3 "Night_3" 2 "Night_2" 1 "Night_1" 0 "Off" ;
VAL_TABLE_ Veh_Lock_Status 3 "UNLOCK_DRV" 2 "UNLOCK_ALL" 1 "LOCK_ALL" 0 "LOCK_DBL" ;
VAL_TABLE_ CrashEvnt_D_Stat 3 "Invalid" 2 "Fuel_Cutoff_Event" 1 "Deploy_Event" 0 "No_Event" ;
VAL_TABLE_ ReducedGuard_D_Stat 3 "NotUsed" 2 "Alarm_On" 1 "Alarm_Off_Previously_On" 0 "Alarm_Off" ;
VAL_TABLE_ HvacPrecondBlwr_D_Rq 15 "NotUsed6" 14 "NotUsed5" 13 "NotUsed4" 12 "NotUsed3" 11 "NotUsed2" 10 "NotUsed1" 9 "Last_User_Setting" 8 "Auto" 7 "Speed7" 6 "Speed6" 5 "Speed5" 4 "Speed4" 3 "Speed3" 2 "Speed2" 1 "Speed1" 0 "Off" ;
VAL_TABLE_ HvacPrecondMode_D_Rq 15 "NotUsed4" 14 "NotUsed3" 13 "NotUsed2" 12 "NotUsed1" 11 "Last_User_Settings" 10 "Auto" 9 "Max_Defrost" 8 "Windshield_Panel_Floor" 7 "Windshield_Panel" 6 "Windshield" 5 "Windshield_Floor" 4 "Floor" 3 "Panel_Floor" 2 "Panel" 1 "MAX_AC" 0 "Off" ;
VAL_TABLE_ Null_Pressed 1 "Pressed" 0 "Null" ;
VAL_TABLE_ FobComm_D_Stat 3 "NotUsed" 2 "RemEngStartOK" 1 "RemEngStartFail" 0 "Null" ;
VAL_TABLE_ PudLamp_D_Rq 3 "RAMP_DOWN" 2 "RAMP_UP" 1 "ON" 0 "OFF" ;
VAL_TABLE_ WndwGlbl_D_Cmd 7 "NotUsed3" 6 "NotUsed2" 5 "NotUsed1" 4 "GLEARN" 3 "GCLOSE" 2 "GOPEN" 1 "GSTOP" 0 "Null" ;
VAL_TABLE_ LockMsg 7 "MSG7" 6 "MSG6" 5 "MSG5" 4 "MSG4" 3 "MSG3" 2 "MSG2" 1 "MSG1" 0 "NO_WARNING" ;
VAL_TABLE_ ChildLockDisplay 3 "NOT_SUPPORTED" 2 "ERROR" 1 "CHILD_UNLOCK" 0 "CHILD_LOCK" ;
VAL_TABLE_ Null_Lock_Unlock 3 "NotUsed" 2 "Unlock" 1 "Lock" 0 "Null" ;
VAL_TABLE_ NotDown_Down 1 "Down" 0 "Not_Down" ;
VAL_TABLE_ NotUp_Up 1 "Up" 0 "Not_Up" ;
VAL_TABLE_ Wiper 15 "NO_DATA_EXISTS" 14 "STALLED" 13 "RESERVED" 12 "AUTO_ADJUST" 11 "COURTESYWIPE" 10 "AUTO_HIGH" 9 "AUTO_LOW" 8 "WASH" 7 "MIST_FLICK" 6 "MAN_HIGH" 5 "MAN_LOW" 4 "MAN_INT_ON" 3 "MAN_INT_OFF" 2 "OFF_MOVING" 1 "AUTO_OFF" 0 "OFF" ;
VAL_TABLE_ Turn_switch 3 "Unused_Treat_As_Off" 2 "Right" 1 "Left" 0 "Off" ;
VAL_TABLE_ PrkLght_D_Stat 3 "Park_Both" 2 "Park_Right" 1 "Park_Left" 0 "Off" ;
VAL_TABLE_ HeadLghtSwtch_D_Stat 3 "Autolamp" 2 "Headlamp" 1 "Parklamp" 0 "Off" ;
VAL_TABLE_ LifeCycMde_D_Actl 3 "Transport" 2 "NotUsed" 1 "Factory" 0 "Normal" ;
VAL_TABLE_ ClimtHeat_D_Rq 7 "NotUsed4" 6 "NotUsed3" 5 "NotUsed2" 4 "PtcHtrTestMde" 3 "Defrost_Defog" 2 "FastTempPullDownHeatingReq" 1 "OpportunisticHeatingReq" 0 "NoHeatingRequest" ;
VAL_TABLE_ NoData_Fault_3FE_3FF 1023 "Fault" 1022 "NoDataExists" ;
VAL_TABLE_ ClimtCool_D_Rq 7 "NotUsed4" 6 "NotUsed3" 5 "NotUsed2" 4 "ElACTestMde" 3 "Defrost_Defog" 2 "FastTempPullDownCoolReq" 1 "OpportunisticCoolingReq" 0 "NoCoolingRequest" ;
VAL_TABLE_ HvacRec_D_RqMxBatt 15 "NotUsed5" 14 "NotUsed4" 13 "NotUsed3" 12 "NotUsed2" 11 "NotUsed1" 10 "No_Override" 9 "90Percent_RecircMax" 8 "80Percent_RecircMax" 7 "70Percent_RecircMax" 6 "60Percent_RecircMax" 5 "50Percent_RecircMax" 4 "40Percent_RecircMax" 3 "30Percent_RecircMax" 2 "20Percent_RecircMax" 1 "10Percent_RecircMax" 0 "0Percent_RecircFullOpen" ;
VAL_TABLE_ PrkBrkStatus 7 "GeneralFault_MaintenceMode" 6 "ECD_by_Brake_ECU_Active" 5 "EPB_Limphome_Active" 4 "Rear_Caliper_Open" 3 "RWU_By_EPB_Active" 2 "Rear_Caliper_Transition" 1 "Rear_Caliper_Closed" 0 "Not_Supported" ;
VAL_TABLE_ Quality_Data 3 "OK" 2 "Not_Within_Specifications" 1 "Eval_In_Progress" 0 "Fault" ;
VAL_TABLE_ PwSrcULoFalt_D_Stat 3 "Fault_No_Output" 2 "Fault_Reduced_Output" 1 "Fault_NonSpecific" 0 "No_Fault" ;
VAL_TABLE_ Eng_D_Stat 3 "NotUsed" 2 "EngAutoStopped" 1 "EngOn" 0 "EngOff" ;
VAL_TABLE_ ElPw_D_Stat 7 "NotUsed_3" 6 "NotUsed_2" 5 "NotUsed_1" 4 "Fault_Limited" 3 "LV_Event_In_Progress" 2 "Not_Supported_Imminent" 1 "Supported" 0 "Not_Supported" ;
VAL_TABLE_ PwPckTq_D_Stat 3 "PwPckOn_TqAvailable" 2 "StartInPrgrss_TqNotAvail" 1 "PwPckOn_TqNotAvailable" 0 "PwPckOff_TqNotAvailable" ;
VAL_TABLE_ Fault_FF 255 "Fault" ;
VAL_TABLE_ ElCmprOverTe_D_Stat 3 "OverTempStop" 2 "OverTempWarning" 1 "Normal" 0 "Undefined" ;
VAL_TABLE_ Southern_Northern 3 "Fault" 2 "Northern" 1 "Southern" 0 "Invalid" ;
VAL_TABLE_ PsngrFrntDetct_D_Actl 3 "Unknown" 2 "Empty" 0 "Faulty" 1 "Occupied" ;
VAL_TABLE_ Fault_3FF 1023 "Fault" ;
VAL_TABLE_ Fault_F 15 "Fault" ;
VAL_TABLE_ Fault_1F 31 "Fault" ;
VAL_TABLE_ LockInhibit 1 "Inhibit" 0 "No_Inhibit" ;
VAL_TABLE_ FCIM_Target_ID 15 "ALL" 9 "GIM" 8 "DSP" 7 "SAT3" 6 "SAT2" 5 "SAT1" 4 "RSC" 3 "FES" 2 "ACM" 1 "CPM" 0 "NOP" ;
VAL_TABLE_ FCIM_Button_Type 54 "_6" 53 "_5" 52 "_4" 51 "_3" 50 "_2" 49 "_1" 48 "_0" 47 "Phone_Mute" 46 "Pause" 45 "Play_Pause" 44 "Volume_Down" 43 "Volume_Up" 42 "Tune_Down" 41 "Tune_Up" 40 "Treble_Down" 39 "Treble_Up" 38 "Tape" 37 "Seek_Down" 36 "Seek_Up" 35 "Shuffle" 34 "Repeat" 33 "Scan" 32 "Navigation" 31 "Fast_Forward" 30 "Reverse" 29 "Preset_6" 28 "Preset_5" 27 "Preset_4" 26 "Preset_3" 25 "Preset_2" 24 "Preset_1" 23 "Memory_Recall" 22 "Clear" 21 "End" 20 "Send" 19 "Fade_Down" 18 "Fade_Up" 17 "Dolby" 16 "Compression" 15 "Clock" 14 "Bass_Down" 13 "Bass_Up" 12 "Balance_Down" 11 "Balance_Up" 10 "Folder_Previous" 9 "Folder_Next" 8 "Category_Folder" 7 "File" 6 "Autoset" 5 "Menu_Previous" 4 "Menu_Next" 3 "Menu" 2 "OK_Select" 1 "Power_On_Off" 0 "NOP_No_Button" 255 "Last" 153 "RPT_Repeat" 152 "NAV" 151 "Dest_Destination" 150 "Map" 149 "SWC_End" 148 "SWC_Send" 147 "Special_2" 146 "Special_1" 145 "Phone_Data" 144 "Rear_Zone_Control" 141 "DISP_Display" 140 "INFO" 139 "Climate" 138 "Radio" 137 "Playmode" 136 "Bezel_Diagnostics" 135 "CursorDown" 134 "CursorUp" 133 "Mute" 132 "Phone" 131 "Eject" 130 "Load" 129 "CD" 128 "AM_FM" 124 "Pound_Clock" 123 "Reserved" 122 "Compass_Cal" 121 "SAT" 120 "Aux" 119 "Sound" 118 "Star_Direct_Direct" 117 "List_Item_5" 116 "List_Item_4" 115 "List_Item_3" 114 "List_Item_2" 113 "List_Item_1" 112 "Reserved_Feature_C" 111 "Reserved_Feature_B" 110 "Reserved_Feature_A" 109 "Active_Path" 108 "Distance_Markers" 107 "Return" 106 "Off" 105 "On" 104 "SWC_Seek_Down" 103 "SWC_Seek_Up" 102 "Media" 101 "Stop_Eject" 100 "B_Button" 99 "A_Button" 98 "TestTone" 97 "Lock_List_Item_5" 96 "Lock_List_Item_4" 95 "Lock_List_Item_3" 94 "Lock_List_Item_2" 93 "Lock_List_Item_1" 92 "Skip_List_Item_5" 91 "Skip_List_Item_4" 90 "Skip_List_Item_3" 89 "Skip_List_Item_2" 88 "Skip_List_Item_1" 87 "Enter" 86 "Back" 85 "Keypad" 84 "Channel_List_5" 83 "Channel_List_4" 82 "Channel_List_3" 81 "Channel_List_2" 80 "Channel_List_1" 79 "Category_List_Item_5" 78 "Category_List_Item_4" 77 "Category_List_Item_3" 76 "Category_List_Item_2" 75 "Category_List_Item_1" 74 "Channel_Guide" 73 "Scan_Presets" 72 "Category_Previous" 71 "Category_Next" 70 "Album" 69 "Song_Title" 68 "Artist" 67 "Text" 66 "BER_Display_Button" 65 "PSN_Display_Button" 64 "ESN_Display_Button" 63 "Category" 62 "Display_Previous" 61 "Display_Next" 60 "Voice_PTT" 59 "POUND" 58 "ASTERISK" 57 "_9" 56 "_8" 55 "_7" ;
VAL_TABLE_ FCIM_Button_State 2 "Button_Pressed" 1 "Button_Released" 0 "NOP" ;
VAL_TABLE_ Temp_Units 2 "Fahrenheit" 1 "Celsius" 0 "Off" ;
VAL_TABLE_ Shed_Feature_Group_ID 16 "PtcHeater" 14 "HtdMirr" 13 "HvacRearBlwr_Third" 12 "HvacRearBlwr_Second" 11 "HvacRearBlwr_First" 31 "All LSHED1 Features" 10 "Htd_Windscrn" 9 "SpltHtdBcklight_HtdMirr" 8 "HtdBcklight_HtdMirr" 7 "HtdCoolSeat_FrtDriver" 6 "HtdCoolSeat_FrtPass" 5 "HtdCoolSeat_RearPass" 4 "HtdCoolSeat_RearDriver" 3 "SmartTrlrTowBattCharge" 2 "Htd_StrWhl" 1 "Htd_Washer_Fluid" 0 "No_LSHED1_Features" 15 "Engine_Coolant_Fan" ;
VAL_TABLE_ CoolantFanStepAct 31 "Unused7" 30 "Unused6" 29 "Unused5" 28 "Unused4" 27 "Unused3" 26 "Unused2" 25 "Unused1" 23 "Step23" 22 "Step22" 21 "Step21" 20 "Step20" 19 "Step19" 18 "Step18" 17 "Step17" 16 "Step16" 15 "Step15" 14 "Step14" 13 "Step13" 12 "Step12" 11 "Step11" 10 "Step10" 9 "Step9" 8 "Step8" 7 "Step7" 6 "Step6" 5 "Step5" 4 "Step4" 3 "Step3" 2 "Step2" 1 "Step1" 24 "Max_Fan_Speed_Req" 0 "Fan_Cmd_Off" ;
VAL_TABLE_ Null_Cancel 1 "Cancel" 0 "Null" ;
VAL_TABLE_ Null_Drive_EasyEntry 2 "Easy_Entry" 1 "Drive" 0 "Null" ;
VAL_TABLE_ Veh_Lock_Requestor 31 "Unused8" 30 "Unused7" 29 "Unused6" 28 "Rgtm_Shutlock_Switch" 27 "Boundary_Alert" 26 "Transit_Vehicle_Relock" 25 "Transit_Cargo_Relock" 24 "Transit_Ajar_Lock" 23 "Diagnostics" 22 "Console_Lock" 21 "Child_Lock" 20 "Double_Lock" 19 "Passive_Pasenger" 18 "Passive_Driver" 17 "Slam_Lock_Protect" 16 "SYNC" 15 "Passport" 14 "Passive_Smart_Unlock" 13 "Autorelock" 12 "RemoteStart" 0 "Null" 1 "Autolock" 11 "Smart_Unlock" 10 "Sliding_Door" 9 "Passive" 8 "Remote" 7 "Programming" 6 "Powerslide" 5 "Keypad" 4 "Key_Cylinder" 3 "Interior" 2 "Auto_Unlock" ;
VAL_TABLE_ Perimeter_Alarm_Mode 3 "Activated" 2 "Armed" 1 "Prearmed" 0 "Disarmed" ;
VAL_TABLE_ Invalid_FFFF 65535 "Invalid" ;
VAL_TABLE_ Shed_Level_Req 7 "Unused_2" 6 "Loads_On" 5 "SHED_ENG_OFF" 4 "SOON_ENG_OFF" 3 "SHED2_CONTIN" 2 "SHED2_TRANS" 1 "SHED1" 0 "NO_SHED" ;
VAL_TABLE_ Eastern_Western 0 "Invalid" 1 "Eastern" 2 "Western" 3 "Fault" ;
VAL_TABLE_ EATC_Temp_Digit3 2 "_5" 1 "_0" 0 "OFF" ;
VAL_TABLE_ EATC_Units 2 "Fahrenheit" 1 "Celsius" 0 "Off" ;
VAL_TABLE_ RKE_Filter_Ctrl 3 "Streaming" 2 "Filter" 1 "Not_Used" 0 "Null" ;
VAL_TABLE_ RstrnImpactEvntStatus 7 "Invalid" 6 "Not_Used_4" 5 "Threshold_2_Exceeded" 4 "Not_Used_3" 3 "Threshold_1_Exceeded" 2 "Not_Used_2" 1 "Not_Used_1" 0 "Normal" ;
VAL_TABLE_ Closed_Ajar 1 "Ajar" 0 "Closed" ;
VAL_TABLE_ Quality_Factor 3 "OK" 2 "Not_Within_Specifications" 1 "No_Data_Exists" 0 "Faulty" ;
VAL_TABLE_ Null_Day_Night 3 "NotUsed" 2 "Night" 1 "Day" 0 "Null" ;
VAL_TABLE_ WhlDir 3 "Failed" 2 "Unknown" 1 "Backward" 0 "Forward" ;
VAL_TABLE_ Unknown_Fault_1FE_1FF 511 "Fault" 510 "Unknown" ;
VAL_TABLE_ Fault_NoFault 1 "Fault" 0 "No_Fault" ;
VAL_TABLE_ Unknown_Fault_FFFE_FFFF 65535 "Fault" 65534 "Unknown" ;
VAL_TABLE_ Invalid_FFFFFF 16777215 "Invalid" ;
VAL_TABLE_ GearLvrPos_D_Actl 15 "Fault" 14 "Unknown_Position" 13 "Undefined_Treat_as__Fault" 12 "Undefined_Treat_as_Fault" 11 "sixth" 10 "fifth" 9 "fourth" 8 "third" 7 "second" 6 "first" 5 "Low" 4 "Sport_DriveSport" 3 "Drive" 2 "Neutral" 1 "Reverse" 0 "Park" ;
VAL_TABLE_ CcStat_D_Actl 7 "Undefined_2" 6 "Undefined_1" 5 "Active" 4 "Active_Que_Assist" 3 "Standby" 2 "Standby_Denied" 1 "Denied" 0 "Off" ;
VAL_TABLE_ AslIconDsply_D_Rq 3 "Not_Used" 2 "On_Active" 1 "On_Passive" 0 "Off" ;
VAL_TABLE_ Unknown_Fault_3E_3F 63 "Fault" 62 "Unknown" ;
VAL_TABLE_ NotPressed_Pressed 1 "Pressed" 0 "Not_Pressed" ;
VAL_TABLE_ NotQuiet_Quiet 1 "Quiet" 0 "Not_Quiet" ;
VAL_TABLE_ Remote_Device_Feedback 7 "Unused3" 6 "Unused2" 5 "Unused1" 4 "Shutdown" 3 "Running" 2 "Starting" 1 "Acknowledge" 0 "Null" ;
VAL_TABLE_ Remote_Start_Req 3 "Not_Used" 2 "Remote_Cancel" 1 "Remote_Start" 0 "No_Request" ;
VAL_TABLE_ Modulation_Ctrl 3 "Unused" 2 "FSK" 1 "ASK_FSK" 0 "ASK" ;
VAL_TABLE_ Unlock_Lock 1 "Locked" 0 "Unlock" ;
VAL_TABLE_ Unknown_Fault_FFE_FFF 4095 "Fault" 4094 "Unknown" ;
VAL_TABLE_ InhibitNoinhibit 1 "Inhibit" 0 "No_Inibit" ;
VAL_TABLE_ DisableEnable 1 "Enable" 0 "Disable" ;
VAL_TABLE_ Side_Detect_Sn_State 3 "Second_Warning_Audio" 2 "System_Failure" 1 "Blocked" 0 "Clear" ;
VAL_TABLE_ Litval_values 255 "Invalid" 254 "Unknown" 5 "Day" 4 "Twilight_4" 3 "Twilight_3" 2 "Twilight_2" 1 "Twilight_1" 0 "Night" ;
VAL_TABLE_ Dimming_Lvl 255 "Invalid" 254 "Unknown" 18 "Day_6" 17 "Day_5" 16 "Day_4" 15 "Day_3" 14 "Day_2" 13 "Day_1" 12 "Night_12" 11 "Night_11" 10 "Night_10" 9 "Night_9" 8 "Night_8" 7 "Night_7" 6 "Night_6" 5 "Night_5" 4 "Night_4" 3 "Night_3" 2 "Night_2" 1 "Night_1" 0 "Off" ;
VAL_TABLE_ Remote_Start_Status 3 "Invalid" 2 "Unknown" 1 "Remote" 0 "Null" ;
VAL_TABLE_ Enabled_Active_Disabled 3 "Unused" 2 "Disabled" 1 "Active" 0 "Enabled_Inactive" ;
VAL_TABLE_ Lock_Subld 15 "Unused7" 14 "Unused6" 13 "Unused5" 12 "Unused4" 11 "Unused3" 10 "Unused2" 9 "Unused1" 8 "Customer_8" 7 "Customer_7" 6 "Customer_6" 5 "Customer_5" 4 "Customer_4" 3 "Customer_3" 2 "Customer_2" 1 "Customer_1" 0 "Null" ;
VAL_TABLE_ Brake_Fluid 3 "Invalid" 2 "Unknown" 1 "Low" 0 "OK" ;
VAL_TABLE_ Unknown_Invalid_FE_FF 255 "Invalid" 254 "Unknown" ;
VAL_TABLE_ Invalid_FF 255 "Invalid" ;
VAL_TABLE_ NotLow_Low 1 "Low" 0 "Not_Low" ;
VAL_TABLE_ Key_In_Ignition_Status 1 "In" 0 "Out" ;
VAL_TABLE_ Ignition_Status 0 "Unknown" 1 "Off" 15 "Invalid" 8 "Start" 4 "Run" 2 "Accessory" ;
VAL_TABLE_ Disabled_Enabled_NoSupport 2 "Unused" 3 "Not_Supported" 1 "Enabled" 0 "Disabled" ;
VAL_TABLE_ Unknown_Fault_FE_FF 255 "Fault" 254 "Unknown" ;
VAL_TABLE_ Null_Unlock 1 "Unlock" 0 "Null" ;
VAL_TABLE_ Null_Active 1 "Active" 0 "Null" ;
VAL_TABLE_ MemoryCmd 7 "Recall_3" 4 "Store_4" 3 "Store_3" 6 "Recall_2" 5 "Recall_1" 2 "Store_2" 1 "Store_1" 0 "Null" 8 "Recall_4" ;
VAL_TABLE_ PassRstrnInd_Req 3 "ABOnNotIllum_OffNotIllum" 2 "AirbagOnNot_Illum_OffIllum" 1 "AirbagOn_Illum_OffNotIllum" 0 "AirbagOn_Illum_Off_Illum" ;
VAL_TABLE_ GPS_dimension 2 "_3D" 1 "_2D" 0 "No_Fix" ;
VAL_TABLE_ GPS_Compass_dirctn 7 "NorthWest" 6 "West" 5 "SouthWest" 4 "South" 3 "SouthEast" 2 "East" 1 "NorthEast" 0 "North" ;
VAL_TABLE_ GPS_Actual_Infer 1 "Inferred_Position" 0 "Actual_Postition" ;
VAL_TABLE_ Off_On 1 "On" 0 "Off" ;
VAL_TABLE_ InactiveActive 1 "Active" 0 "Inactive" ;
VAL_TABLE_ Fault_7F 127 "Fault" ;
VAL_TABLE_ Unknown_Invalid_1E_1F 31 "Invalid" 30 "Unknown" ;
VAL_TABLE_ Unknown_Invalid_3FFE_3FFF 16383 "Invalid" 16382 "Unknown" ;
VAL_TABLE_ NoYes 1 "Yes" 0 "No" ;
VAL_TABLE_ Unknown_Fault_3FE_3FF 1023 "Fault" 1022 "Unknown" ;
VAL_TABLE_ LockSwStat 3 "Invalid" 2 "Unlock" 1 "Lock" 0 "Null" ;
VAL_TABLE_ Null_Override 1 "Override" 0 "Null" ;
VAL_TABLE_ Off_On_Flash 3 "Not_Used" 2 "Flash" 1 "On" 0 "Off" ;
VAL_TABLE_ Update_Bit 1 "Fresh_data" 0 "Unchanged_data" ;
VAL_TABLE_ Tire_Pressure_Stat 4 "Alert" 15 "Not_Supported" 3 "Fault" 2 "Low" 1 "Normal" 0 "Unknown" ;
VAL_TABLE_ Tire_Pressure_System2 13 "Training_Complete" 12 "Train_InsideLeftRear_tire" 11 "Train_OutsideLeftRear_tire" 10 "Train_LeftRear_tire" 9 "Train_InsideRtRear_tire" 8 "Train_OutsideRtRear_tire" 7 "Train_RightRear_tire" 14 "Tires_not_trained" 6 "Train_RightFront_tire" 5 "Train_LeftFront_tire" 4 "Systm_Activ_Composite_Stat" 3 "Low_Composite_Stat" 2 "Sensr_Fault_Composite_Stat" 1 "Systm_Fault_Composite_Stat" 0 "Unknown_Composite_Stat" ;
VAL_TABLE_ Running_Board 3 "Unused" 2 "Manually_Deployed" 1 "All_Enabled" 0 "All_Disabled" ;
VAL_TABLE_ Clmt_Ctrl_Seat_Setting 128 "H3_High_Heat__MAX" 64 "H2_Medium_Heat" 32 "H1_Low_Heat" 16 "C3_High_Cool__MAX" 8 "C2_Medium_Cool" 4 "C1_Low_Cool" 2 "Off" ;
VAL_TABLE_ Turn_Seq 3 "Seq" 2 "On" 1 "Off" 0 "Null" ;
VAL_TABLE_ NotPark 1 "Park" 0 "Not_Park" ;
VAL_TABLE_ PersOptIn 1 "OPTED_IN" 0 "NOT_OPTED_IN" ;
VAL_TABLE_ PersonalSetUp 3 "Non_Moveable_Person" 2 "Moveable_Person" 1 "Vehicle" 0 "Factory" ;
VAL_TABLE_ Full_Limited 1 "Limited" 0 "Full" ;
VAL_TABLE_ NoConflict_Conflict 1 "Conflict" 0 "No_Conflict" ;
VAL_TABLE_ Assoc_Confirm 0 "None" 7 "Associate" 6 "Keycode_Rejected" 5 "Keycode_Accepted" 4 "In_Progress" 3 "Erase" 2 "Duplicate" 1 "Disassociate" ;
VAL_TABLE_ Complete_Inprogress 3 "Unused" 2 "Null" 1 "InProgress" 0 "Complete" ;
VAL_TABLE_ Null_Pers1_4 7 "Unused_3" 6 "Unused_2" 5 "Unused_1" 4 "PERS_4" 3 "PERS_3" 2 "PERS_2" 1 "PERS_1" 0 "Null" ;
VAL_TABLE_ Pers1_4 7 "Unused_3" 6 "Unused_2" 5 "Unused_1" 4 "Vehicle" 3 "PERS_4" 2 "PERS_3" 1 "PERS_2" 0 "PERS_1" ;
VAL_TABLE_ Null_Query 7 "Unused_2" 6 "Unused_1" 5 "Copy" 4 "Restore" 3 "Upload" 2 "Set" 1 "Query" 0 "Null" ;
VAL_TABLE_ Ign_Key_Device_Type 15 "Invalid" 14 "Unknown" 3 "Key_Not_Prgrm_Read_Failure" 2 "Key_In_Ign_My_Key" 1 "Key_In_Ign_Standard_Key" 0 "Key_Read_In_Progress" ;
VAL_TABLE_ Off_No_Eff_Unknown_Invalid 3 "Invalid" 2 "Unknown" 1 "No_Effect" 0 "Off" ;
VAL_TABLE_ Null_Out 1 "Out" 0 "Null" ;

BO_ 877 Clmt_Button_Stat7: 8 HVAC_RCCM
 SG_ AAR_Btn_Stt : 7|2@0+ (1,0) [0|3] "SED"  GWM

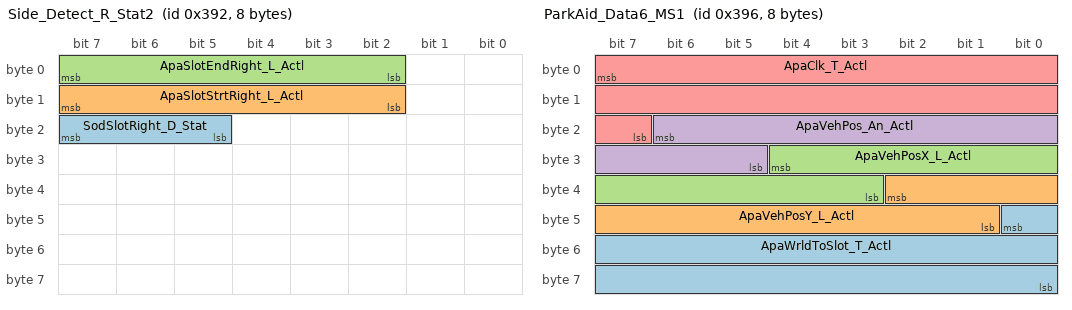
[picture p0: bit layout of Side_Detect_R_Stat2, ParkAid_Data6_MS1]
BO_ 914 Side_Detect_R_Stat2: 8 SODR
 SG_ SodSlotRight_D_Stat : 23|3@0+ (1,0) [0|7] "SED"  GWM
 SG_ ApaSlotStrtRight_L_Actl : 15|6@0+ (0.064,0) [0|4.032] "meter"  GWM
 SG_ ApaSlotEndRight_L_Actl : 7|6@0+ (0.064,0) [0|4.032] "meter"  GWM

BO_ 918 ParkAid_Data6_MS1: 8 GWM
 SG_ ApaWrldToSlot_T_Actl : 40|17@0+ (0.000512,0) [0|67.108352] "second"  SODL,SODR
 SG_ ApaVehPosY_L_Actl : 34|10@0+ (64,-32768) [-32768|32704] "millimeter"  SODL,SODR
 SG_ ApaVehPosX_L_Actl : 28|10@0+ (64,-32768) [-32768|32704] "millimeter"  SODL,SODR
 SG_ ApaVehPos_An_Actl : 22|10@0+ (0.3515625,-180) [-180|179.6484375] "degrees"  SODL,SODR
 SG_ ApaClk_T_Actl : 7|17@0+ (0.000512,0) [0|67.108352] "second"  SODL,SODR

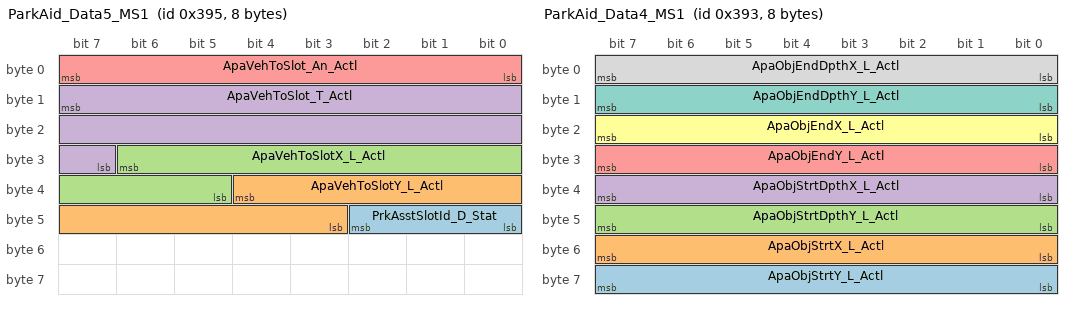
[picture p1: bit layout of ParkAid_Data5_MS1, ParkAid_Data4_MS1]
BO_ 917 ParkAid_Data5_MS1: 8 GWM
 SG_ PrkAsstSlotId_D_Stat : 42|3@0+ (1,0) [0|7] "SED"  SODL,SODR
 SG_ ApaVehToSlotY_L_Actl : 36|10@0+ (64,-32768) [-32768|32704] "millimeter"  SODL,SODR
 SG_ ApaVehToSlotX_L_Actl : 30|10@0+ (64,-32768) [-32768|32704] "millimeter"  SODL,SODR
 SG_ ApaVehToSlot_T_Actl : 15|17@0+ (0.000512,0) [0|67.108352] "second"  SODL,SODR
 SG_ ApaVehToSlot_An_Actl : 7|8@0+ (1.4118,-180) [-180|180.009] "degrees"  SODL,SODR

BO_ 915 ParkAid_Data4_MS1: 8 GWM
 SG_ ApaObjStrtY_L_Actl : 63|8@0+ (0.12807301,-24) [-24|8.65861755] "meter"  SODL,SODR
 SG_ ApaObjStrtX_L_Actl : 55|8@0+ (0.12807301,-24) [-24|8.65861755] "meter"  SODL,SODR
 SG_ ApaObjStrtDpthY_L_Actl : 47|8@0+ (0.12807301,-24) [-24|8.65861755] "meter"  SODL,SODR
 SG_ ApaObjStrtDpthX_L_Actl : 39|8@0+ (0.12807301,-24) [-24|8.65861755] "meter"  SODL,SODR
 SG_ ApaObjEndY_L_Actl : 31|8@0+ (0.12807301,-24) [-24|8.65861755] "meter"  SODL,SODR
 SG_ ApaObjEndX_L_Actl : 23|8@0+ (0.12807301,-24) [-24|8.65861755] "meter"  SODL,SODR
 SG_ ApaObjEndDpthY_L_Actl : 15|8@0+ (0.12807301,-24) [-24|8.65861755] "meter"  SODL,SODR
 SG_ ApaObjEndDpthX_L_Actl : 7|8@0+ (0.12807301,-24) [-24|8.65861755] "meter"  SODR,SODL

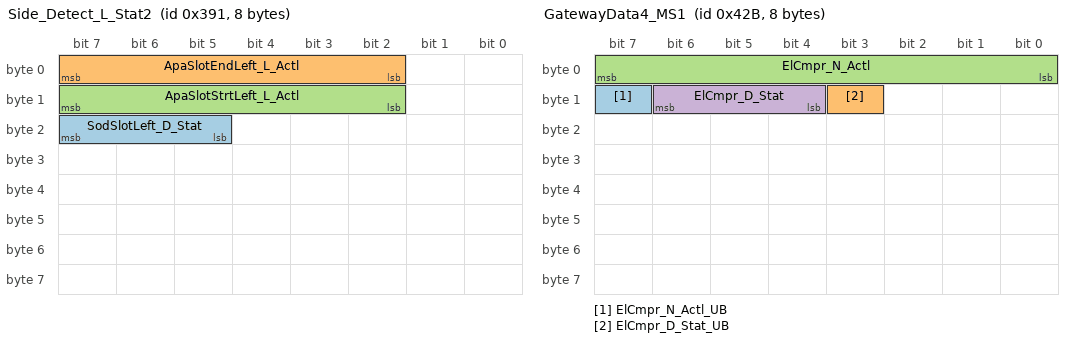
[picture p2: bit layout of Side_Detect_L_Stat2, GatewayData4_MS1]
BO_ 913 Side_Detect_L_Stat2: 8 SODL
 SG_ SodSlotLeft_D_Stat : 23|3@0+ (1,0) [0|7] "SED"  GWM
 SG_ ApaSlotEndLeft_L_Actl : 7|6@0+ (0.064,0) [0|4.032] "meter"  GWM
 SG_ ApaSlotStrtLeft_L_Actl : 15|6@0+ (0.064,0) [0|4.032] "meter"  GWM

BO_ 1067 GatewayData4_MS1: 8 GWM
 SG_ ElCmpr_N_Actl_UB : 15|1@0+ (1,0) [0|1] "SED"  HVAC_RCCM
 SG_ ElCmpr_D_Stat_UB : 11|1@0+ (1,0) [0|1] "SED"  HVAC_RCCM
 SG_ ElCmpr_N_Actl : 7|8@0+ (50,0) [0|12700] "RPM"  HVAC_RCCM
 SG_ ElCmpr_D_Stat : 14|3@0+ (1,0) [0|7] "SED"  HVAC_RCCM

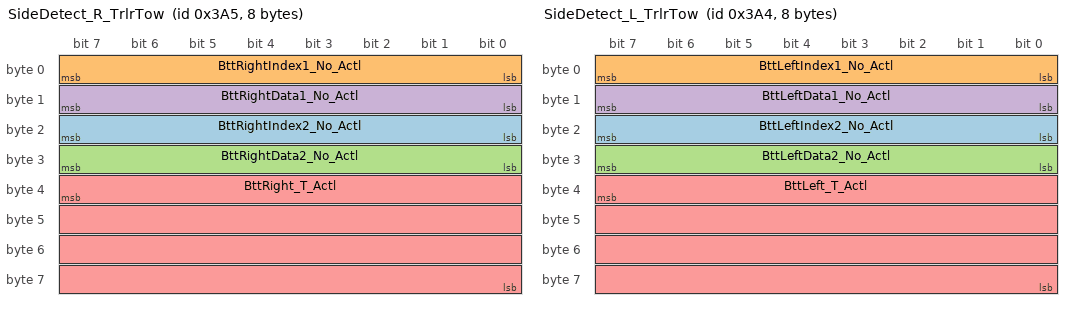
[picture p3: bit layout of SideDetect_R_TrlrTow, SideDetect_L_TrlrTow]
BO_ 933 SideDetect_R_TrlrTow: 8 SODR
 SG_ BttRightIndex2_No_Actl : 23|8@0+ (1,0) [0|255] "unitless"  SODL,GWM
 SG_ BttRightIndex1_No_Actl : 7|8@0+ (1,0) [0|255] "unitless"  SODL,GWM
 SG_ BttRightData2_No_Actl : 31|8@0+ (1,0) [0|255] "unitless"  SODL,GWM
 SG_ BttRightData1_No_Actl : 15|8@0+ (1,0) [0|255] "unitless"  GWM,SODL
 SG_ BttRight_T_Actl : 39|32@0+ (1,0) [0|4294967295] "ms"  GWM,SODL

BO_ 932 SideDetect_L_TrlrTow: 8 SODL
 SG_ BttLeftIndex2_No_Actl : 23|8@0+ (1,0) [0|255] "unitless"  GWM,SODR
 SG_ BttLeftIndex1_No_Actl : 7|8@0+ (1,0) [0|255] "unitless"  GWM,SODR
 SG_ BttLeftData2_No_Actl : 31|8@0+ (1,0) [0|255] "unitless"  GWM,SODR
 SG_ BttLeftData1_No_Actl : 15|8@0+ (1,0) [0|255] "unitless"  GWM,SODR
 SG_ BttLeft_T_Actl : 39|32@0+ (1,0) [0|4294967295] "ms"  GWM,SODR

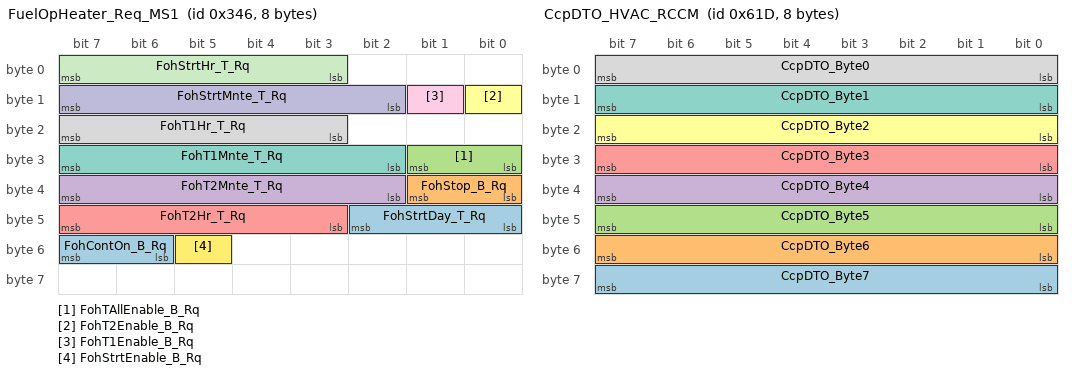
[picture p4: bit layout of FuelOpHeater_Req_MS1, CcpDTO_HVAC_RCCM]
BO_ 838 FuelOpHeater_Req_MS1: 8 GWM
 SG_ FohStrtDay_T_Rq : 42|3@0+ (1,0) [0|7] "SED"  SOBDMD_AHCM_FOH
 SG_ FohStop_B_Rq : 33|2@0+ (1,0) [0|3] "SED"  SOBDMD_AHCM_FOH
 SG_ FohTAllEnable_B_Rq : 25|2@0+ (1,0) [0|3] "SED"  SOBDMD_AHCM_FOH
 SG_ FohT2Mnte_T_Rq : 39|6@0+ (1,0) [0|63] "minute"  SOBDMD_AHCM_FOH
 SG_ FohT2Hr_T_Rq : 47|5@0+ (1,0) [0|31] "hour"  SOBDMD_AHCM_FOH
 SG_ FohT2Enable_B_Rq : 8|1@0+ (1,0) [0|1] "SED"  SOBDMD_AHCM_FOH
 SG_ FohT1Mnte_T_Rq : 31|6@0+ (1,0) [0|63] "minute"  SOBDMD_AHCM_FOH
 SG_ FohT1Hr_T_Rq : 23|5@0+ (1,0) [0|31] "hour"  SOBDMD_AHCM_FOH
 SG_ FohT1Enable_B_Rq : 9|1@0+ (1,0) [0|1] "SED"  SOBDMD_AHCM_FOH
 SG_ FohStrtMnte_T_Rq : 15|6@0+ (1,0) [0|63] "minute"  SOBDMD_AHCM_FOH
 SG_ FohStrtHr_T_Rq : 7|5@0+ (1,0) [0|31] "hour"  SOBDMD_AHCM_FOH
 SG_ FohStrtEnable_B_Rq : 53|1@0+ (1,0) [0|1] "SED"  SOBDMD_AHCM_FOH
 SG_ FohContOn_B_Rq : 55|2@0+ (1,0) [0|3] "SED"  SOBDMD_AHCM_FOH

BO_ 1565 CcpDTO_HVAC_RCCM: 8 HVAC_RCCM
 SG_ CcpDTO_Byte7 : 56|8@1- (1,0) [0|0] ""  TSTR
 SG_ CcpDTO_Byte6 : 48|8@1- (1,0) [0|0] ""  TSTR
 SG_ CcpDTO_Byte5 : 40|8@1- (1,0) [0|0] ""  TSTR
 SG_ CcpDTO_Byte4 : 32|8@1- (1,0) [0|0] ""  TSTR
 SG_ CcpDTO_Byte3 : 24|8@1- (1,0) [0|0] ""  TSTR
 SG_ CcpDTO_Byte2 : 16|8@1- (1,0) [0|0] ""  TSTR
 SG_ CcpDTO_Byte1 : 8|8@1- (1,0) [0|0] ""  TSTR
 SG_ CcpDTO_Byte0 : 0|8@1- (1,0) [0|0] ""  TSTR

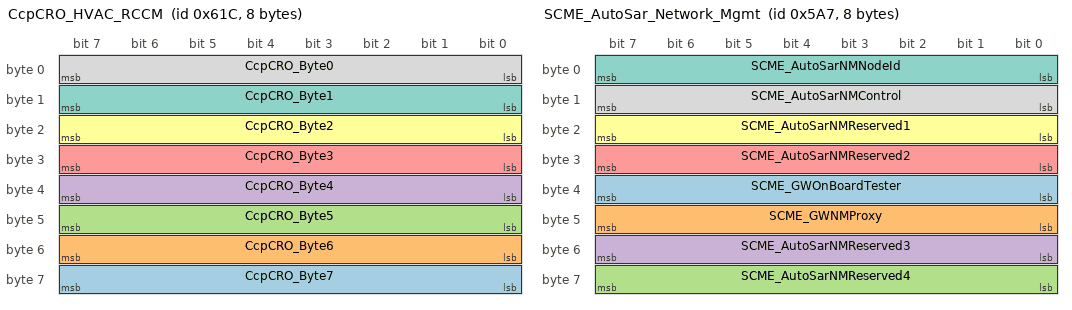
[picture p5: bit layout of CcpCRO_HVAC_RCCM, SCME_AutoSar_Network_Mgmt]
BO_ 1564 CcpCRO_HVAC_RCCM: 8 TSTR
 SG_ CcpCRO_Byte7 : 56|8@1- (1,0) [0|0] ""  HVAC_RCCM
 SG_ CcpCRO_Byte6 : 48|8@1- (1,0) [0|0] ""  HVAC_RCCM
 SG_ CcpCRO_Byte5 : 40|8@1- (1,0) [0|0] ""  HVAC_RCCM
 SG_ CcpCRO_Byte4 : 32|8@1- (1,0) [0|0] ""  HVAC_RCCM
 SG_ CcpCRO_Byte3 : 24|8@1- (1,0) [0|0] ""  HVAC_RCCM
 SG_ CcpCRO_Byte2 : 16|8@1- (1,0) [0|0] ""  HVAC_RCCM
 SG_ CcpCRO_Byte1 : 8|8@1- (1,0) [0|0] ""  HVAC_RCCM
 SG_ CcpCRO_Byte0 : 0|8@1- (1,0) [0|0] ""  HVAC_RCCM

BO_ 773 PassengerSeat_Data: 8 SCMB_PSM
 SG_ SeatScrnPsngrOn_B_Rq : 6|1@0+ (1,0) [0|1] "SED"  GWM

BO_ 1447 SCME_AutoSar_Network_Mgmt: 8 SCME
 SG_ SCME_GWOnBoardTester : 39|8@0+ (1,0) [0|255] "unitless"  GWM
 SG_ SCME_GWNMProxy : 47|8@0+ (1,0) [0|255] "unitless"  GWM
 SG_ SCME_AutoSarNMReserved4 : 63|8@0+ (1,0) [0|255] "unitless"  GWM
 SG_ SCME_AutoSarNMReserved3 : 55|8@0+ (1,0) [0|255] "unitless"  GWM
 SG_ SCME_AutoSarNMReserved2 : 31|8@0+ (1,0) [0|255] "unitless"  GWM
 SG_ SCME_AutoSarNMReserved1 : 23|8@0+ (1,0) [0|255] "unitless"  GWM
 SG_ SCME_AutoSarNMNodeId : 7|8@0+ (1,0) [0|255] "unitless"  GWM
 SG_ SCME_AutoSarNMControl : 15|8@0+ (1,0) [0|255] "unitless"  GWM

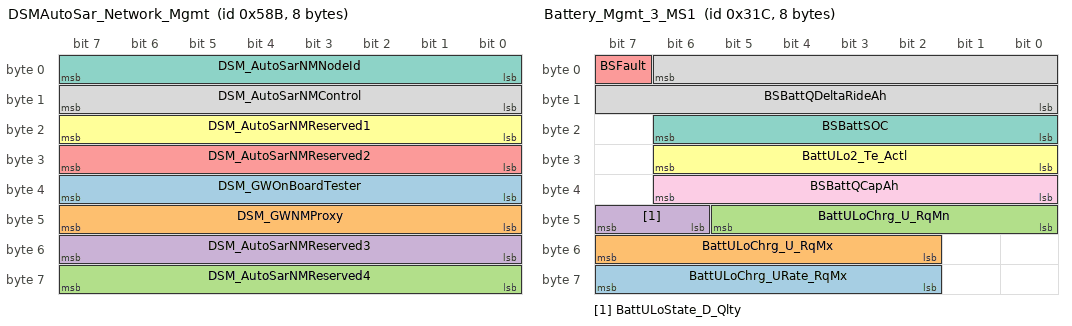
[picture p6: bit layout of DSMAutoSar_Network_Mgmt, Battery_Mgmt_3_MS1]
BO_ 1419 DSMAutoSar_Network_Mgmt: 8 DSM
 SG_ DSM_GWOnBoardTester : 39|8@0+ (1,0) [0|255] "unitless"  GWM
 SG_ DSM_GWNMProxy : 47|8@0+ (1,0) [0|255] "unitless"  GWM
 SG_ DSM_AutoSarNMReserved4 : 63|8@0+ (1,0) [0|255] "unitless"  GWM
 SG_ DSM_AutoSarNMReserved3 : 55|8@0+ (1,0) [0|255] "unitless"  GWM
 SG_ DSM_AutoSarNMReserved2 : 31|8@0+ (1,0) [0|255] "unitless"  GWM
 SG_ DSM_AutoSarNMReserved1 : 23|8@0+ (1,0) [0|255] "unitless"  GWM
 SG_ DSM_AutoSarNMNodeId : 7|8@0+ (1,0) [0|255] "unitless"  GWM
 SG_ DSM_AutoSarNMControl : 15|8@0+ (1,0) [0|255] "unitless"  GWM

BO_ 796 Battery_Mgmt_3_MS1: 8 GWM
 SG_ BattULoChrg_URate_RqMx : 63|6@0+ (0.1,0) [0|6.3] "volts/second"  GWM
 SG_ BattULoChrg_U_RqMx : 55|6@0+ (0.1,10.6) [10.6|16.9] "volt"  GWM
 SG_ BattULoChrg_U_RqMn : 45|6@0+ (0.1,10.6) [10.6|16.9] "volt"  GWM
 SG_ BattULoState_D_Qlty : 47|2@0+ (1,0) [0|3] "SED"  HVAC_RCCM
 SG_ BSFault : 7|1@0+ (1,0) [0|1] "SED"  HVAC_RCCM
 SG_ BattULo2_Te_Actl : 30|7@0+ (1,-40) [-40|86] "degC"  HVAC_RCCM
 SG_ BSBattSOC : 22|7@0+ (1,0) [0|127] "%"  HVAC_RCCM
 SG_ BSBattQDeltaRideAh : 6|15@0+ (0.0078125,-100) [-100|155.9921875] "ampere*hour"  GWM
 SG_ BSBattQCapAh : 38|7@0+ (1,0) [0|127] "ampere*hour"  GWM

BO_ 1364 TRM_Network_MgmtM: 8 TRM
 SG_ TRM_Network_Mgmt : 7|64@0+ (1,0) [0|1.844674407371E+019] "unitless"  PDM,DDM

BO_ 1383 RSM_Network_MgmtM: 8 RSM
 SG_ RSM_Network_Mgmt : 7|64@0+ (1,0) [0|1.844674407371E+019] "unitless"  GWM

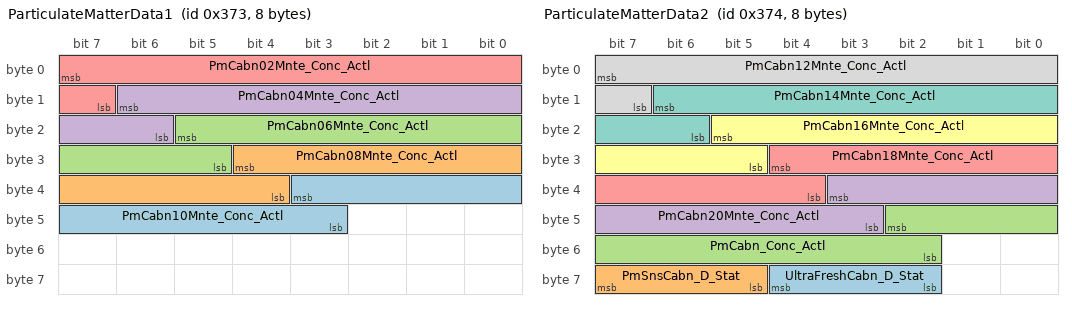
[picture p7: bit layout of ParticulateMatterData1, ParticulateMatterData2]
BO_ 883 ParticulateMatterData1: 8 HVAC_RCCM
 SG_ PmCabn10Mnte_Conc_Actl : 35|9@0+ (1,0) [0|509] "parts/million"  GWM
 SG_ PmCabn08Mnte_Conc_Actl : 28|9@0+ (1,0) [0|509] "parts/million"  GWM
 SG_ PmCabn06Mnte_Conc_Actl : 21|9@0+ (1,0) [0|509] "parts/million"  GWM
 SG_ PmCabn04Mnte_Conc_Actl : 14|9@0+ (1,0) [0|509] "parts/million"  GWM
 SG_ PmCabn02Mnte_Conc_Actl : 7|9@0+ (1,0) [0|509] "parts/million"  GWM

BO_ 884 ParticulateMatterData2: 8 HVAC_RCCM
 SG_ UltraFreshCabn_D_Stat : 60|3@0+ (1,0) [0|7] "SED"  GWM
 SG_ PmSnsCabn_D_Stat : 63|3@0+ (1,0) [0|7] "SED"  GWM
 SG_ PmCabn_Conc_Actl : 42|9@0+ (1,0) [0|509] "parts/million"  GWM
 SG_ PmCabn20Mnte_Conc_Actl : 35|9@0+ (1,0) [0|509] "parts/million"  GWM
 SG_ PmCabn18Mnte_Conc_Actl : 28|9@0+ (1,0) [0|509] "parts/million"  GWM
 SG_ PmCabn16Mnte_Conc_Actl : 21|9@0+ (1,0) [0|509] "parts/million"  GWM
 SG_ PmCabn14Mnte_Conc_Actl : 14|9@0+ (1,0) [0|509] "parts/million"  GWM
 SG_ PmCabn12Mnte_Conc_Actl : 7|9@0+ (1,0) [0|509] "parts/million"  GWM

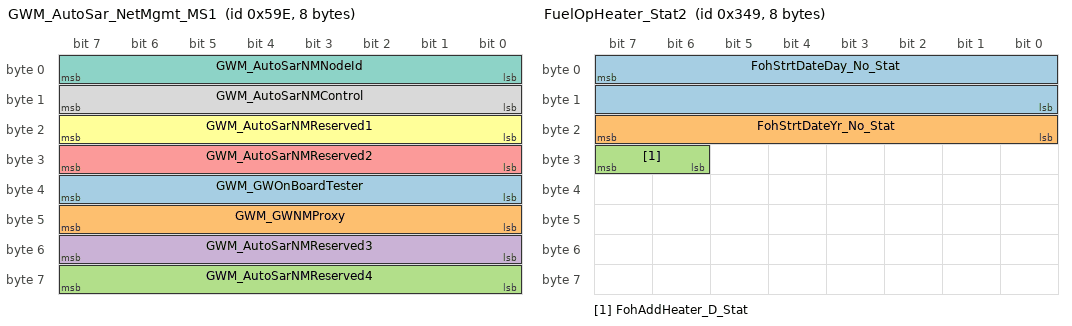
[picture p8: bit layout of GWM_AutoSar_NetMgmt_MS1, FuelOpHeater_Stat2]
BO_ 1438 GWM_AutoSar_NetMgmt_MS1: 8 GWM
 SG_ GWM_GWOnBoardTester : 39|8@0+ (1,0) [0|255] "unitless"  HVAC_RCCM,DDM,PDM,RGTM
 SG_ GWM_GWNMProxy : 47|8@0+ (1,0) [0|255] "unitless"  HVAC_RCCM,DDM,PDM,RGTM
 SG_ GWM_AutoSarNMReserved4 : 63|8@0+ (1,0) [0|255] "unitless"  HVAC_RCCM,DDM,PDM,RGTM
 SG_ GWM_AutoSarNMReserved3 : 55|8@0+ (1,0) [0|255] "unitless"  HVAC_RCCM,DDM,PDM,RGTM
 SG_ GWM_AutoSarNMReserved2 : 31|8@0+ (1,0) [0|255] "unitless"  HVAC_RCCM,DDM,PDM,RGTM
 SG_ GWM_AutoSarNMReserved1 : 23|8@0+ (1,0) [0|255] "unitless"  HVAC_RCCM,DDM,PDM,RGTM
 SG_ GWM_AutoSarNMNodeId : 7|8@0+ (1,0) [0|255] "unitless"  HVAC_RCCM,DDM,PDM,RGTM
 SG_ GWM_AutoSarNMControl : 15|8@0+ (1,0) [0|255] "unitless"  HVAC_RCCM,DDM,PDM,RGTM

BO_ 841 FuelOpHeater_Stat2: 8 SOBDMD_AHCM_FOH
 SG_ FohStrtDateDay_No_Stat : 7|16@0+ (1,0) [0|65535] "julian day"  GWM
 SG_ FohStrtDateYr_No_Stat : 23|8@0+ (1,2000) [2000|2255] "year"  GWM
 SG_ FohAddHeater_D_Stat : 31|2@0+ (1,0) [0|3] "SED"  GWM

BO_ 1075 BodyGatewayData_3_MS1: 8 GWM
 SG_ ACU_RadioSeekMode2_St : 60|5@0+ (1,0) [0|31] "SED"  DDM,PDM,RGTM
 SG_ ACU_CurrTUBand_St : 45|4@0+ (1,0) [0|15] "SED"  DDM,PDM,RGTM
 SG_ ACU_CurrentFreq_St : 55|11@0+ (1,0) [0|1557] "unitless"  DDM,PDM,RGTM
 SG_ ACU_RadioSeekMode2_St_UB : 41|1@0+ (1,0) [0|1] "SED"  DDM,PDM,RGTM
 SG_ ACU_CurrTUBand_St_UB : 32|1@0+ (1,0) [0|1] "SED"  DDM,PDM,RGTM
 SG_ ACU_CurrentFreq_St_UB : 33|1@0+ (1,0) [0|1] "SED"  DDM,PDM,RGTM
 SG_ CtaBrk_D_Stat_UB : 40|1@0+ (1,0) [0|1] "SED"  SODR,SODL
 SG_ CtaBrk_D_Stat : 47|2@0+ (1,0) [0|3] "SED"  SODR,SODL
 SG_ SelDrvMdePt_D_Rq_UB : 34|1@0+ (1,0) [0|1] "SED"  HVAC_RCCM
 SG_ SelDrvMdePt_D_Rq : 39|5@0+ (1,0) [0|31] "SED"  HVAC_RCCM
 SG_ PrkAidSnsRrCrnr_D_Stat : 19|4@0+ (1,0) [0|15] "SED" Vector__XXX
 SG_ PrkAidSnsRrCntr_D_Stat : 31|4@0+ (1,0) [0|15] "SED" Vector__XXX
 SG_ PrkAidSnsRlCrnr_D_Stat : 13|4@0+ (1,0) [0|15] "SED" Vector__XXX
 SG_ PrkAidSnsRlCntr_D_Stat : 23|4@0+ (1,0) [0|15] "SED" Vector__XXX
 SG_ PrkAidSnsRrCrnr_D_Stat_UB : 27|1@0+ (1,0) [0|1] "SED" Vector__XXX
 SG_ PrkAidSnsRrCntr_D_Stat_UB : 26|1@0+ (1,0) [0|1] "SED" Vector__XXX
 SG_ PrkAidSnsRlCntr_D_Stat_UB : 8|1@0+ (1,0) [0|1] "SED" Vector__XXX
 SG_ PrkAidSnsRlCrnr_D_Stat_UB : 9|1@0+ (1,0) [0|1] "SED" Vector__XXX
 SG_ BttOn_B_Rq_UB : 14|1@0+ (1,0) [0|1] "SED" Vector__XXX
 SG_ Btt_L_Actl_UB : 0|1@0+ (1,0) [0|1] "SED"  SODR,SODL
 SG_ BttOn_B_Rq : 15|1@0+ (1,0) [0|1] "SED" Vector__XXX
 SG_ Btt_L_Actl : 7|7@0+ (0.1,0) [0|12.5] "meter"  SODR,SODL
 SG_ ArmrestStwdRear_B_Stat_UB : 24|1@0+ (1,0) [0|1] "SED" Vector__XXX
 SG_ ArmrestStwdRear_B_Stat : 25|1@0+ (1,0) [0|1] "SED" Vector__XXX

BO_ 1963 TesterPhysicalResSCMB_PSM: 8 SCMB_PSM
 SG_ TesterPhysicalResSCMB_PSM : 7|64@0+ (1,0) [0|1.84467E+019] "unitless"  TSTR

BO_ 1955 TesterPhysicalReqSCMB_PSM: 8 TSTR
 SG_ TesterPhysicalReqSCMB_PSM : 7|64@0+ (1,0) [0|1.84467E+019] "unitless"  SCMB_PSM

BO_ 1285 PDM_Network_MgmtM: 8 PDM
 SG_ PDM_Network_Mgmt : 7|64@0+ (1,0) [0|1.844674407371E+019] "unitless"  DDM

BO_ 977 ConvertibleTop_Master: 8 GENERIC_GWMWakeup
 SG_ CnvtTopMsgTxt_D_Rq : 39|2@0+ (1,0) [0|3] "SED"  GWM

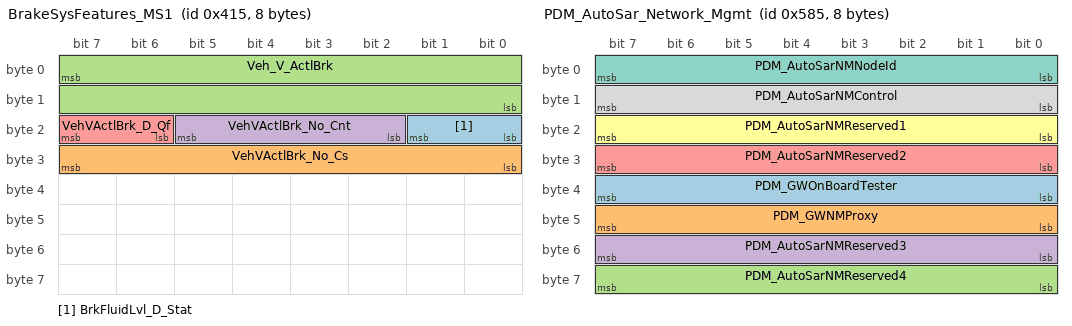
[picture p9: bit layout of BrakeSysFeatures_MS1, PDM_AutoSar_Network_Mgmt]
BO_ 1045 BrakeSysFeatures_MS1: 8 GWM
 SG_ BrkFluidLvl_D_Stat : 17|2@0+ (1,0) [0|3] "SED" Vector__XXX
 SG_ VehVActlBrk_No_Cs : 31|8@0+ (1,0) [0|255] "Unitless"  TRM
 SG_ Veh_V_ActlBrk : 7|16@0+ (0.01,0) [0|655.35] "kph"  TRM
 SG_ VehVActlBrk_No_Cnt : 21|4@0+ (1,0) [0|15] "Unitless"  TRM
 SG_ VehVActlBrk_D_Qf : 23|2@0+ (1,0) [0|3] "SED"  TRM

BO_ 1413 PDM_AutoSar_Network_Mgmt: 8 PDM
 SG_ PDM_GWOnBoardTester : 39|8@0+ (1,0) [0|255] "unitless"  GWM
 SG_ PDM_GWNMProxy : 47|8@0+ (1,0) [0|255] "unitless"  GWM
 SG_ PDM_AutoSarNMReserved4 : 63|8@0+ (1,0) [0|255] "unitless"  GWM
 SG_ PDM_AutoSarNMReserved3 : 55|8@0+ (1,0) [0|255] "unitless"  GWM
 SG_ PDM_AutoSarNMReserved2 : 31|8@0+ (1,0) [0|255] "unitless"  GWM
 SG_ PDM_AutoSarNMReserved1 : 23|8@0+ (1,0) [0|255] "unitless"  GWM
 SG_ PDM_AutoSarNMNodeId : 7|8@0+ (1,0) [0|255] "unitless"  GWM
 SG_ PDM_AutoSarNMControl : 15|8@0+ (1,0) [0|255] "unitless"  GWM

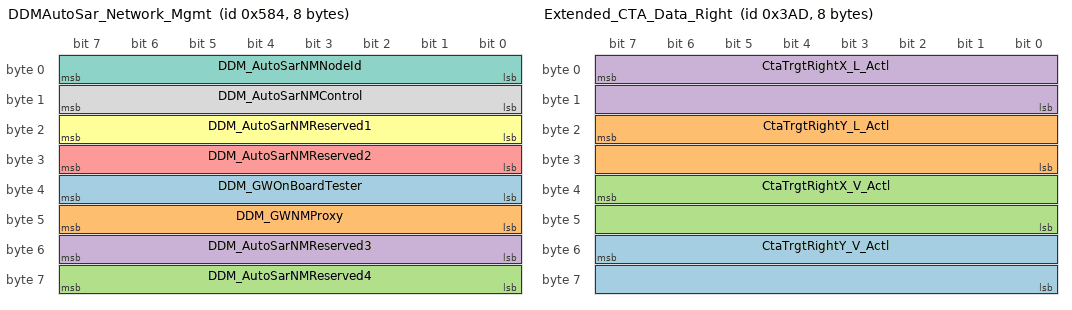
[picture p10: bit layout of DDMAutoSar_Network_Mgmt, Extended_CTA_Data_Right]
BO_ 1412 DDMAutoSar_Network_Mgmt: 8 DDM
 SG_ DDM_GWOnBoardTester : 39|8@0+ (1,0) [0|255] "unitless"  GWM
 SG_ DDM_GWNMProxy : 47|8@0+ (1,0) [0|255] "unitless"  GWM
 SG_ DDM_AutoSarNMReserved4 : 63|8@0+ (1,0) [0|255] "unitless"  GWM
 SG_ DDM_AutoSarNMReserved3 : 55|8@0+ (1,0) [0|255] "unitless"  GWM
 SG_ DDM_AutoSarNMReserved2 : 31|8@0+ (1,0) [0|255] "unitless"  GWM
 SG_ DDM_AutoSarNMReserved1 : 23|8@0+ (1,0) [0|255] "unitless"  GWM
 SG_ DDM_AutoSarNMNodeId : 7|8@0+ (1,0) [0|255] "unitless"  GWM
 SG_ DDM_AutoSarNMControl : 15|8@0+ (1,0) [0|255] "unitless"  GWM

BO_ 1079 GatewayData2_MS1: 8 GWM
 SG_ ApaMde_D_Stat_UB : 25|1@0+ (1,0) [0|1] "SED"  SODL,SODR
 SG_ ApaMde_D_Stat : 39|3@0+ (1,0) [0|7] "SED"  SODL,SODR
 SG_ TrlrAidEnbl_D2_Stat_UB : 58|1@0+ (1,0) [0|1] "SED" Vector__XXX
 SG_ TrlrAidEnbl_D2_Stat : 61|3@0+ (1,0) [0|7] "SED" Vector__XXX
 SG_ GenericSwtch3_No_Actl_UB : 41|1@0+ (1,0) [0|1] "SED" Vector__XXX
 SG_ GenericSwtch3_No_Actl : 55|3@0+ (1,0) [0|7] "unitless" Vector__XXX
 SG_ GenericSwtch2_No_Actl_UB : 32|1@0+ (1,0) [0|1] "SED" Vector__XXX
 SG_ GenericSwtch2_No_Actl : 44|3@0+ (1,0) [0|7] "unitless" Vector__XXX
 SG_ GenericSwtch1_No_Actl_UB : 33|1@0+ (1,0) [0|1] "SED" Vector__XXX
 SG_ GenericSwtch1_No_Actl : 47|3@0+ (1,0) [0|7] "unitless" Vector__XXX
 SG_ RbaSys_D_Stat_UB : 8|1@0+ (1,0) [0|1] "SED"  SODR,SODL
 SG_ RbaSys_D_Stat : 4|2@0+ (1,0) [0|3] "SED"  SODR,SODL
 SG_ HybMdeStat_D_Dsply_UB : 9|1@0+ (1,0) [0|1] "SED"  HVAC_RCCM
 SG_ Rba_D_Stat : 12|2@0+ (1,0) [0|3] "SED"  SODR,SODL
 SG_ Rba_D_Stat_UB : 10|1@0+ (1,0) [0|1] "SED"  SODR,SODL
 SG_ BalrSwtch_D_Stat : 19|2@0+ (1,0) [0|3] "SED" Vector__XXX
 SG_ BalrMde_D_Rq_UB : 20|1@0+ (1,0) [0|1] "SED" Vector__XXX
 SG_ BalrSwtch_D_Stat_UB : 17|1@0+ (1,0) [0|1] "SED" Vector__XXX
 SG_ BalrMde_D_Rq : 22|2@0+ (1,0) [0|3] "SED" Vector__XXX
 SG_ ChrgGoTTouchEnbl_B_Rq : 1|1@0+ (1,0) [0|1] "SED"  HVAC_RCCM
 SG_ ChrgGoTExtHtrEnbl_B_Rq : 2|1@0+ (1,0) [0|1] "SED"  HVAC_RCCM
 SG_ ChrgGoTTouchEnbl_B_Rq_UB : 23|1@0+ (1,0) [0|1] "SED"  HVAC_RCCM
 SG_ ChrgGoTExtHtrEnbl_B_Rq_UB : 0|1@0+ (1,0) [0|1] "SED"  HVAC_RCCM
 SG_ LcwaAlrtRight_B_Rq_UB : 34|1@0+ (1,0) [0|1] "SED"  SODR
 SG_ LcwaAlrtLeft_B_Rq_UB : 36|1@0+ (1,0) [0|1] "SED"  SODL
 SG_ LcwaAlrtRight_B_Rq : 35|1@0+ (1,0) [0|1] "SED"  SODR
 SG_ LcwaAlrtLeft_B_Rq : 24|1@0+ (1,0) [0|1] "SED"  SODL
 SG_ ApaSteScanMde_D_Stat : 15|2@0+ (1,0) [0|3] "SED" Vector__XXX
 SG_ ApaSteScanMde_D_Stat_UB : 13|1@0+ (1,0) [0|1] "SED" Vector__XXX
 SG_ TrlrAidMsgTxt_D2_Rq_UB : 16|1@0+ (1,0) [0|1] "SED" Vector__XXX
 SG_ TrlrAidMsgTxt_D2_Rq : 31|6@0+ (1,0) [0|63] "SED" Vector__XXX
 SG_ HybMdeStat_D_Dsply : 7|3@0+ (1,0) [0|7] "SED"  HVAC_RCCM

BO_ 941 Extended_CTA_Data_Right: 8 SODR
 SG_ CtaTrgtRightY_V_Actl : 55|16@0+ (0.001526,-50) [-50|50.00641] "meters/sec"  GWM,SODL
 SG_ CtaTrgtRightY_L_Actl : 23|16@0+ (0.0030519,-100) [-100|100.0062665] "meter"  GWM,SODL
 SG_ CtaTrgtRightX_V_Actl : 39|16@0+ (0.001526,-50) [-50|50.00641] "meters/sec"  GWM,SODL
 SG_ CtaTrgtRightX_L_Actl : 7|16@0+ (0.0021363,-120) [-120|20.0024205] "meter"  GWM,SODL

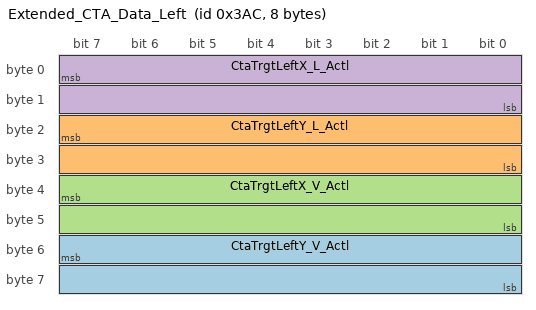
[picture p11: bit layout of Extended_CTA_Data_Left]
BO_ 940 Extended_CTA_Data_Left: 8 SODL
 SG_ CtaTrgtLeftY_V_Actl : 55|16@0+ (0.001526,-50) [-50|50.00641] "meters/sec"  GWM,SODR
 SG_ CtaTrgtLeftY_L_Actl : 23|16@0+ (0.0030519,-100) [-100|100.0062665] "meter"  GWM,SODR
 SG_ CtaTrgtLeftX_V_Actl : 39|16@0+ (0.001526,-50) [-50|50.00641] "meters/sec"  GWM,SODR
 SG_ CtaTrgtLeftX_L_Actl : 7|16@0+ (0.0021363,-120) [-120|20.0024205] "meter"  GWM,SODR

CM_ BU_ GWM "Gateway Module CGEA1.3(Star Architecture)";
CM_ BU_ SCMB_PSM "Passenger Seat Module (16U502)";
CM_ BU_ HVAC_RCCM "Front Controls Interface Module (EFP: Electronic Finish Panel, Integrated HVAC)";
CM_ BU_ SOBDMD_AHCM_FOH "MSCAN module Fuel Operated Heater";
CM_ BU_ TRM "Trailer Module";
CM_ BU_ SODL "Side Obstacle Detection Control Module - Left (Primary)";
CM_ BU_ RTM "Radio Transceiver Module(RFA,TPM)";
CM_ BU_ PDM "Passenger Front Door Module ";
CM_ BU_ SCMH "Passenger Multi-Contour Seat (Massage)";
CM_ BU_ SCMG "Driver Multi-Contour Seat (Massage)";
CM_ BU_ RSM "Remote Start Module";
CM_ BU_ SODR "Side Obstacle Detection Control Module - Right

";
CM_ BU_ DDM "Driver Front Door Module, 2006 CD378 new module design";
CM_ BU_ RGTM "Rear Gate/Trunk Module, LTM (Lift-gate Trunk Module)";
CM_ BU_ DSM "SCMA (Driver Front Seat Module)";
CM_ BU_ SCME "Driver Climate Control Seat Module (DCSM)";
CM_ BU_ TSTR "Diagnostic Tester";
CM_ SG_ 1075 ACU_RadioSeekMode2_St "Object Tuner.RadioSeekMode2";
CM_ SG_ 1075 ACU_CurrTUBand_St "Object.Tuner.CurrentTUBand";
CM_ SG_ 1075 ACU_CurrentFreq_St "Object Tuner.CurrentFreq

AM: Freq = 153+ Offset kHz.
Offset 0..1557 

FM: Freq = 76+ Offset*0.05 MHz. Offset 0..640
Selected tuned band determine frequency (kHz or MHz).";
CM_ SG_ 1079 GenericSwtch2_No_Actl "U625 Police Wig Wag feature";
BA_DEF_  "BusType" STRING ;
BA_DEF_ BO_  "FrameGatewayNetwork" STRING ;
BA_DEF_ BO_  "FrameGatewayMS1" HEX 0 1407;
BA_DEF_ BO_  "NetworkInitialization" ENUM  "No","Yes";
BA_DEF_ BO_  "FrameGatewayId" HEX 0 1407;
BA_DEF_ BO_  "EventRateOfChange" INT 10 10000;
BA_DEF_ BO_  "GenMsgStartDelayTime" INT 0 10000;
BA_DEF_ BO_  "GenMsgNrOfRepetition" INT 0 100;
BA_DEF_ BO_  "GenMsgDelayTime" INT 0 1000;
BA_DEF_ BO_  "GenMsgCycleTime" INT 0 100000;
BA_DEF_ BO_  "GenMsgSendType" ENUM  "FixedPeriodic","Event","EnabledPeriodic","NotUsed","NotUsed","EventPeriodic","NotUsed","NotUsed","NoMsgSendType";
BA_DEF_ SG_  "U_P702_MY2021_Tx" ENUM  "No","Yes";
BA_DEF_ SG_  "U_CX727_MY2021_Tx" ENUM  "No","Yes";
BA_DEF_ SG_  "U_VN127_MY20_Tx" ENUM  "No","Yes";
BA_DEF_ SG_  "U_H567_MY20_Tx" ENUM  "No","Yes";
BA_DEF_ SG_  "U_CX430_MY2021_Tx" ENUM  "No","Yes";
BA_DEF_ SG_  "U_U611_U625_MY20_Phev_Tx" ENUM  "No","Yes";
BA_DEF_ SG_  "U_B562_MY18_Diesel_Tx" ENUM  "No","Yes";
BA_DEF_ SG_  "U_CX482_CX483_MY20_Tx" ENUM  "No","Yes";
BA_DEF_ SG_  "U_U611_U625_MY20_Hev_Tx" ENUM  "No","Yes";
BA_DEF_ SG_  "U_U611_U625_MY20_Gas_Tx" ENUM  "No","Yes";
BA_DEF_ SG_  "U_B500_MY18_Diesel_Tx" ENUM  "No","Yes";
BA_DEF_ SG_  "U_B500_MY18_Gas_Tx" ENUM  "No","Yes";
BA_DEF_ SG_  "U_C490_MY18_Tx" ENUM  "No","Yes";
BA_DEF_ SG_  "U_B562_MY18_Gas_Tx" ENUM  "No","Yes";
BA_DEF_ SG_  "U_C519_MY18_5_Gas_Tx" ENUM  "No","Yes";
BA_DEF_ SG_  "U_C519_MY18_5_Diesel_Tx" ENUM  "No","Yes";
BA_DEF_ SG_  "U_B515_MCA_MY17_Gas_Tx" ENUM  "No","Yes";
BA_DEF_ SG_  "U_B515_MCA_MY17_Diesel_Tx" ENUM  "No","Yes";
BA_DEF_ SG_  "U_B479_MY17_Diesel_Tx" ENUM  "No","Yes";
BA_DEF_ SG_  "U_B479_MY17_Gas_Tx" ENUM  "No","Yes";
BA_DEF_ SG_  "U_P702_MY2021_Rx" ENUM  "No","Yes";
BA_DEF_ SG_  "U_CX727_MY2021_Rx" ENUM  "No","Yes";
BA_DEF_ SG_  "U_VN127_MY20_Rx" ENUM  "No","Yes";
BA_DEF_ SG_  "U_H567_MY20_Rx" ENUM  "No","Yes";
BA_DEF_ SG_  "U_CX430_MY2021_Rx" ENUM  "No","Yes";
BA_DEF_ SG_  "U_U611_U625_MY20_Phev_Rx" ENUM  "No","Yes";
BA_DEF_ SG_  "U_B562_MY18_Diesel_Rx" ENUM  "No","Yes";
BA_DEF_ SG_  "U_CX482_CX483_MY20_Rx" ENUM  "No","Yes";
BA_DEF_ SG_  "U_U611_U625_MY20_Hev_Rx" ENUM  "No","Yes";
BA_DEF_ SG_  "U_U611_U625_MY20_Gas_Rx" ENUM  "No","Yes";
BA_DEF_ SG_  "U_B500_MY18_Diesel_Rx" ENUM  "No","Yes";
BA_DEF_ SG_  "U_B500_MY18_Gas_Rx" ENUM  "No","Yes";
BA_DEF_ SG_  "U_C490_MY18_Rx" ENUM  "No","Yes";
BA_DEF_ SG_  "U_B562_MY18_Gas_Rx" ENUM  "No","Yes";
BA_DEF_ SG_  "U_LC1_B515_MY17_Gas_Rx" ENUM  "No","Yes";
BA_DEF_ SG_  "U_LC1_B515_MY17_Diesel_Rx" ENUM  "No","Yes";
BA_DEF_ SG_  "U_C519_MY18_5_Gas_Rx" ENUM  "No","Yes";
BA_DEF_ SG_  "U_C519_MY18_5_Diesel_Rx" ENUM  "No","Yes";
BA_DEF_ SG_  "U_B515_MCA_MY17_Gas_Rx" ENUM  "No","Yes";
BA_DEF_ SG_  "U_B515_MCA_MY17_Diesel_Rx" ENUM  "No","Yes";
BA_DEF_ SG_  "U_B479_MY17_Diesel_Rx" ENUM  "No","Yes";
BA_DEF_ SG_  "U_B479_MY17_Gas_Rx" ENUM  "No","Yes";
BA_DEF_ SG_  "U_B562LC_MY15_Gas_Rx" ENUM  "No","Yes";
BA_DEF_ SG_  "U_B562LC_MY15_Diesel_Rx" ENUM  "No","Yes";
BA_DEF_ SG_  "GenSigStartValue" HEX 0 268435455;
BA_DEF_ SG_  "MetaData" ENUM  "No","Yes";
BA_DEF_ SG_  "ContentDependant" ENUM  "No","Yes";
BA_DEF_ SG_  "GenSigStartValueInteger" INT 0 1000000000;
BA_DEF_ SG_  "UsedOnPgmDBC" ENUM  "No","Yes";
BA_DEF_ SG_  "CrossOver_InfoCAN" ENUM  "No","Yes";
BA_DEF_ SG_  "WakeupSignal" ENUM  "No","Yes";
BA_DEF_ SG_  "GenSigInactiveValue" INT 0 100000;
BA_DEF_ SG_  "GenSigSendType" ENUM  "Cyclic","OnWrite","vector_leerstring","OnChange","vector_leerstring","IfActive","vector_leerstring","NoSigSendType";
BA_DEF_ BO_  "AuthFreshnessCounterSyncAttempt" INT 0 2;
BA_DEF_ BO_  "GenMsgRoutingTimeoutTime" INT 0 5000;
BA_DEF_ BO_  "MessageGateway" ENUM  "No","Yes";
BA_DEF_ BO_  "NmAsrMessage" ENUM  "No","Yes";
BA_DEF_ BO_  "DiagState" ENUM  "No","Yes";
BA_DEF_ BO_  "DiagRequest" ENUM  "No","Yes";
BA_DEF_ BO_  "DiagResponse" ENUM  "No","Yes";
BA_DEF_ BO_  "NmMessage" ENUM  "No","Yes";
BA_DEF_ BO_  "GenMsgILSupport" ENUM  "No","Yes";
BA_DEF_ BU_  "Terminator" ENUM  "No","Yes";
BA_DEF_ BU_  "NodeWakeUpTime" INT 0 10000;
BA_DEF_ BU_  "NodeStartUpTime" INT 0 10000;
BA_DEF_ BU_  "NmAsrNodeIdentifier" HEX 128 255;
BA_DEF_ BU_  "NmAsrNode" ENUM  "No","Yes";
BA_DEF_ BU_  "PowerType" ENUM  "Switched","Latched","Sleep","vector_leerstring","vector_leerstring";
BA_DEF_ BU_  "DiagNode" ENUM  "GGDS","GDS","NONE";
BA_DEF_ BU_  "EOL_SB_Flash" ENUM  "GGDS","GDS","NONE","vector_leerstring";
BA_DEF_ BU_  "NmNode" ENUM  "No","Yes";
BA_DEF_ BU_  "NmStationAddress" INT 0 255;
BA_DEF_ BU_  "ILUsed" ENUM  "No","Yes";
BA_DEF_ BU_  "NosPackage" ENUM  "None","I3_1","I3_2","1.0.1","RP","EuCD","Volcano","I3_3","FNOS_Autosar";
BA_DEF_ BU_  "PackageID" STRING ;
BA_DEF_ BU_  "GatewayECU" ENUM  "No","Yes";
BA_DEF_  "VersionNumber" INT 0 10000;
BA_DEF_  "StarNetworkGwType" ENUM  "0=NotDefined","1=HS1","2=HS2","3=HS3","4=HS4","5=HS5","6=MS1","7=HS6","8=HS7","9=MS2","10=FD1";
BA_DEF_  "CMDB_Version" STRING ;
BA_DEF_  "NmType" STRING ;
BA_DEF_  "NetworkSpeed" ENUM  "500kBits/s","125kBit/s";
BA_DEF_  "NmAsrMessageCount" INT 128 128;
BA_DEF_  "NmAsrBaseAddress" HEX 1408 1408;
BA_DEF_  "DBName" STRING ;
BA_DEF_  "VersionDay" INT 1 31;
BA_DEF_  "Manufacturer" STRING ;
BA_DEF_  "VersionMonth" INT 1 12;
BA_DEF_  "VersionYear" INT 2000 3000;
BA_DEF_  "NmBaseAddress" HEX 1280 1280;
BA_DEF_  "NmMessageCount" INT 0 128;
BA_DEF_DEF_  "BusType" "";
BA_DEF_DEF_  "FrameGatewayNetwork" "NONE";
BA_DEF_DEF_  "FrameGatewayMS1" 0;
BA_DEF_DEF_  "NetworkInitialization" "Yes";
BA_DEF_DEF_  "FrameGatewayId" 0;
BA_DEF_DEF_  "EventRateOfChange" 10000;
BA_DEF_DEF_  "GenMsgStartDelayTime" 0;
BA_DEF_DEF_  "GenMsgNrOfRepetition" 1;
BA_DEF_DEF_  "GenMsgDelayTime" 20;
BA_DEF_DEF_  "GenMsgCycleTime" 0;
BA_DEF_DEF_  "GenMsgSendType" "NoMsgSendType";
BA_DEF_DEF_  "U_P702_MY2021_Tx" "No";
BA_DEF_DEF_  "U_CX727_MY2021_Tx" "No";
BA_DEF_DEF_  "U_VN127_MY20_Tx" "No";
BA_DEF_DEF_  "U_H567_MY20_Tx" "No";
BA_DEF_DEF_  "U_CX430_MY2021_Tx" "No";
BA_DEF_DEF_  "U_U611_U625_MY20_Phev_Tx" "No";
BA_DEF_DEF_  "U_B562_MY18_Diesel_Tx" "No";
BA_DEF_DEF_  "U_CX482_CX483_MY20_Tx" "No";
BA_DEF_DEF_  "U_U611_U625_MY20_Hev_Tx" "No";
BA_DEF_DEF_  "U_U611_U625_MY20_Gas_Tx" "No";
BA_DEF_DEF_  "U_B500_MY18_Diesel_Tx" "No";
BA_DEF_DEF_  "U_B500_MY18_Gas_Tx" "No";
BA_DEF_DEF_  "U_C490_MY18_Tx" "No";
BA_DEF_DEF_  "U_B562_MY18_Gas_Tx" "No";
BA_DEF_DEF_  "U_C519_MY18_5_Gas_Tx" "No";
BA_DEF_DEF_  "U_C519_MY18_5_Diesel_Tx" "No";
BA_DEF_DEF_  "U_B515_MCA_MY17_Gas_Tx" "No";
BA_DEF_DEF_  "U_B515_MCA_MY17_Diesel_Tx" "No";
BA_DEF_DEF_  "U_B479_MY17_Diesel_Tx" "No";
BA_DEF_DEF_  "U_B479_MY17_Gas_Tx" "No";
BA_DEF_DEF_  "U_P702_MY2021_Rx" "No";
BA_DEF_DEF_  "U_CX727_MY2021_Rx" "No";
BA_DEF_DEF_  "U_VN127_MY20_Rx" "No";
BA_DEF_DEF_  "U_H567_MY20_Rx" "No";
BA_DEF_DEF_  "U_CX430_MY2021_Rx" "No";
BA_DEF_DEF_  "U_U611_U625_MY20_Phev_Rx" "No";
BA_DEF_DEF_  "U_B562_MY18_Diesel_Rx" "No";
BA_DEF_DEF_  "U_CX482_CX483_MY20_Rx" "No";
BA_DEF_DEF_  "U_U611_U625_MY20_Hev_Rx" "No";
BA_DEF_DEF_  "U_U611_U625_MY20_Gas_Rx" "No";
BA_DEF_DEF_  "U_B500_MY18_Diesel_Rx" "No";
BA_DEF_DEF_  "U_B500_MY18_Gas_Rx" "No";
BA_DEF_DEF_  "U_C490_MY18_Rx" "No";
BA_DEF_DEF_  "U_B562_MY18_Gas_Rx" "No";
BA_DEF_DEF_  "U_LC1_B515_MY17_Gas_Rx" "No";
BA_DEF_DEF_  "U_LC1_B515_MY17_Diesel_Rx" "No";
BA_DEF_DEF_  "U_C519_MY18_5_Gas_Rx" "No";
BA_DEF_DEF_  "U_C519_MY18_5_Diesel_Rx" "No";
BA_DEF_DEF_  "U_B515_MCA_MY17_Gas_Rx" "No";
BA_DEF_DEF_  "U_B515_MCA_MY17_Diesel_Rx" "No";
BA_DEF_DEF_  "U_B479_MY17_Diesel_Rx" "No";
BA_DEF_DEF_  "U_B479_MY17_Gas_Rx" "No";
BA_DEF_DEF_  "U_B562LC_MY15_Gas_Rx" "No";
BA_DEF_DEF_  "U_B562LC_MY15_Diesel_Rx" "No";
BA_DEF_DEF_  "GenSigStartValue" 0;
BA_DEF_DEF_  "MetaData" "No";
BA_DEF_DEF_  "ContentDependant" "No";
BA_DEF_DEF_  "GenSigStartValueInteger" 0;
BA_DEF_DEF_  "UsedOnPgmDBC" "Yes";
BA_DEF_DEF_  "CrossOver_InfoCAN" "No";
BA_DEF_DEF_  "WakeupSignal" "No";
BA_DEF_DEF_  "GenSigInactiveValue" 0;
BA_DEF_DEF_  "GenSigSendType" "NoSigSendType";
BA_DEF_DEF_  "AuthFreshnessCounterSyncAttempt" 2;
BA_DEF_DEF_  "GenMsgRoutingTimeoutTime" 0;
BA_DEF_DEF_  "MessageGateway" "No";
BA_DEF_DEF_  "NmAsrMessage" "No";
BA_DEF_DEF_  "DiagState" "No";
BA_DEF_DEF_  "DiagRequest" "No";
BA_DEF_DEF_  "DiagResponse" "No";
BA_DEF_DEF_  "NmMessage" "No";
BA_DEF_DEF_  "GenMsgILSupport" "Yes";
BA_DEF_DEF_  "Terminator" "No";
BA_DEF_DEF_  "NodeWakeUpTime" 10;
BA_DEF_DEF_  "NodeStartUpTime" 250;
BA_DEF_DEF_  "NmAsrNodeIdentifier" 128;
BA_DEF_DEF_  "NmAsrNode" "No";
BA_DEF_DEF_  "PowerType" "Switched";
BA_DEF_DEF_  "DiagNode" "GGDS";
BA_DEF_DEF_  "EOL_SB_Flash" "GGDS";
BA_DEF_DEF_  "NmNode" "No";
BA_DEF_DEF_  "NmStationAddress" 0;
BA_DEF_DEF_  "ILUsed" "Yes";
BA_DEF_DEF_  "NosPackage" "I3_3";
BA_DEF_DEF_  "PackageID" "08.05.00.00.71.xx.xx.rr.00.00";
BA_DEF_DEF_  "GatewayECU" "No";
BA_DEF_DEF_  "VersionNumber" 1;
BA_DEF_DEF_  "StarNetworkGwType" "0=NotDefined";
BA_DEF_DEF_  "CMDB_Version" "v11.01";
BA_DEF_DEF_  "NmType" "Ford-OSEK";
BA_DEF_DEF_  "NetworkSpeed" "500kBits/s";
BA_DEF_DEF_  "NmAsrMessageCount" 128;
BA_DEF_DEF_  "NmAsrBaseAddress" 1408;
BA_DEF_DEF_  "DBName" "";
BA_DEF_DEF_  "VersionDay" 1;
BA_DEF_DEF_  "Manufacturer" "Ford";
BA_DEF_DEF_  "VersionMonth" 1;
BA_DEF_DEF_  "VersionYear" 2011;
BA_DEF_DEF_  "NmBaseAddress" 1280;
BA_DEF_DEF_  "NmMessageCount" 128;
BA_ "VersionDay" 8;
BA_ "VersionNumber" 14;
BA_ "StarNetworkGwType" 6;
BA_ "CMDB_Version" "B_v18.01";
BA_ "NetworkSpeed" 1;
BA_ "VersionMonth" 10;
BA_ "VersionYear" 2018;
BA_ "BusType" "CAN";
BA_ "DBName" "MS1_CAN";
BA_ "NosPackage" BU_ GWM 4;
BA_ "GatewayECU" BU_ GWM 1;
BA_ "Terminator" BU_ GWM 1;
BA_ "NodeStartUpTime" BU_ GWM 100;
BA_ "NmAsrNodeIdentifier" BU_ GWM 158;
BA_ "NmAsrNode" BU_ GWM 1;
BA_ "PowerType" BU_ GWM 2;
BA_ "NmNode" BU_ GWM 1;
BA_ "NmStationAddress" BU_ GWM 30;
BA_ "NmAsrNode" BU_ SCMB_PSM 1;
BA_ "NmAsrNodeIdentifier" BU_ SCMB_PSM 216;
BA_ "NodeWakeUpTime" BU_ SCMB_PSM 200;
BA_ "NodeStartUpTime" BU_ SCMB_PSM 200;
BA_ "PowerType" BU_ SCMB_PSM 2;
BA_ "NmStationAddress" BU_ SCMB_PSM 88;
BA_ "Terminator" BU_ HVAC_RCCM 1;
BA_ "NmAsrNodeIdentifier" BU_ HVAC_RCCM 131;
BA_ "NmAsrNode" BU_ HVAC_RCCM 1;
BA_ "PowerType" BU_ HVAC_RCCM 2;
BA_ "NmStationAddress" BU_ HVAC_RCCM 3;
BA_ "NodeWakeUpTime" BU_ HVAC_RCCM 100;
BA_ "PackageID" BU_ HVAC_RCCM "08.08.00.01.40.07.05.00.00.00";
BA_ "NodeWakeUpTime" BU_ SOBDMD_AHCM_FOH 150;
BA_ "NodeStartUpTime" BU_ SOBDMD_AHCM_FOH 1000;
BA_ "PowerType" BU_ SOBDMD_AHCM_FOH 2;
BA_ "NmNode" BU_ SOBDMD_AHCM_FOH 1;
BA_ "NmStationAddress" BU_ SOBDMD_AHCM_FOH 9;
BA_ "NodeWakeUpTime" BU_ TRM 35;
BA_ "NodeStartUpTime" BU_ TRM 1000;
BA_ "PowerType" BU_ TRM 2;
BA_ "NmNode" BU_ TRM 1;
BA_ "NmStationAddress" BU_ TRM 84;
BA_ "NodeStartUpTime" BU_ SODL 620;
BA_ "NmStationAddress" BU_ SODL 106;
BA_ "NodeWakeUpTime" BU_ RTM 25;
BA_ "NodeStartUpTime" BU_ RTM 1000;
BA_ "PowerType" BU_ RTM 2;
BA_ "NmNode" BU_ RTM 1;
BA_ "NmStationAddress" BU_ RTM 59;
BA_ "NodeWakeUpTime" BU_ PDM 200;
BA_ "NodeStartUpTime" BU_ PDM 1000;
BA_ "NmAsrNodeIdentifier" BU_ PDM 133;
BA_ "NmAsrNode" BU_ PDM 1;
BA_ "PowerType" BU_ PDM 2;
BA_ "NmStationAddress" BU_ PDM 5;
BA_ "NodeStartUpTime" BU_ SCMH 1000;
BA_ "NmStationAddress" BU_ SCMH 44;
BA_ "NodeStartUpTime" BU_ SCMG 1000;
BA_ "NmStationAddress" BU_ SCMG 43;
BA_ "NodeWakeUpTime" BU_ RSM 20;
BA_ "NodeStartUpTime" BU_ RSM 4500;
BA_ "PowerType" BU_ RSM 2;
BA_ "NmNode" BU_ RSM 1;
BA_ "NmStationAddress" BU_ RSM 103;
BA_ "NodeStartUpTime" BU_ SODR 620;
BA_ "NmStationAddress" BU_ SODR 107;
BA_ "NodeWakeUpTime" BU_ DDM 200;
BA_ "NodeStartUpTime" BU_ DDM 1000;
BA_ "NmAsrNodeIdentifier" BU_ DDM 132;
BA_ "NmAsrNode" BU_ DDM 1;
BA_ "PowerType" BU_ DDM 2;
BA_ "NmStationAddress" BU_ DDM 4;
BA_ "NodeWakeUpTime" BU_ RGTM 100;
BA_ "NodeStartUpTime" BU_ RGTM 500;
BA_ "NmAsrNodeIdentifier" BU_ RGTM 166;
BA_ "NmAsrNode" BU_ RGTM 1;
BA_ "PowerType" BU_ RGTM 2;
BA_ "NmStationAddress" BU_ RGTM 38;
BA_ "NodeWakeUpTime" BU_ DSM 200;
BA_ "NodeStartUpTime" BU_ DSM 200;
BA_ "NmAsrNodeIdentifier" BU_ DSM 139;
BA_ "NmAsrNode" BU_ DSM 1;
BA_ "PowerType" BU_ DSM 2;
BA_ "NmStationAddress" BU_ DSM 11;
BA_ "NodeWakeUpTime" BU_ SCME 200;
BA_ "NodeStartUpTime" BU_ SCME 200;
BA_ "NmAsrNodeIdentifier" BU_ SCME 167;
BA_ "NmAsrNode" BU_ SCME 1;
BA_ "PowerType" BU_ SCME 2;
BA_ "NmStationAddress" BU_ SCME 39;
BA_ "NodeStartUpTime" BU_ TSTR 1000;
BA_ "PowerType" BU_ TSTR 2;
BA_ "GenMsgCycleTime" BO_ 877 1000;
BA_ "GenMsgSendType" BO_ 877 5;
BA_ "GenMsgCycleTime" BO_ 914 160;
BA_ "GenMsgSendType" BO_ 914 0;
BA_ "FrameGatewayNetwork" BO_ 918 "HS2_CAN";
BA_ "FrameGatewayId" BO_ 918 918;
BA_ "FrameGatewayNetwork" BO_ 917 "HS2_CAN";
BA_ "FrameGatewayId" BO_ 917 917;
BA_ "FrameGatewayNetwork" BO_ 915 "HS2_CAN";
BA_ "FrameGatewayId" BO_ 915 915;
BA_ "GenMsgCycleTime" BO_ 913 160;
BA_ "GenMsgSendType" BO_ 913 0;
BA_ "GenMsgSendType" BO_ 1067 5;
BA_ "GenMsgCycleTime" BO_ 1067 250;
BA_ "GenMsgSendType" BO_ 933 0;
BA_ "GenMsgCycleTime" BO_ 933 50;
BA_ "GenMsgSendType" BO_ 932 0;
BA_ "GenMsgCycleTime" BO_ 932 50;
BA_ "FrameGatewayId" BO_ 838 838;
BA_ "FrameGatewayNetwork" BO_ 838 "HS3_CAN";
BA_ "GenMsgSendType" BO_ 1565 1;
BA_ "GenMsgILSupport" BO_ 1565 0;
BA_ "NetworkInitialization" BO_ 1565 0;
BA_ "GenMsgILSupport" BO_ 1564 0;
BA_ "GenMsgSendType" BO_ 1564 1;
BA_ "NetworkInitialization" BO_ 1564 0;
BA_ "GenMsgCycleTime" BO_ 773 1000;
BA_ "GenMsgSendType" BO_ 773 5;
BA_ "NetworkInitialization" BO_ 1447 0;
BA_ "GenMsgCycleTime" BO_ 1447 1000;
BA_ "GenMsgSendType" BO_ 1447 0;
BA_ "NmAsrMessage" BO_ 1447 1;
BA_ "GenMsgILSupport" BO_ 1447 0;
BA_ "NetworkInitialization" BO_ 1419 0;
BA_ "GenMsgCycleTime" BO_ 1419 1000;
BA_ "GenMsgSendType" BO_ 1419 0;
BA_ "NmAsrMessage" BO_ 1419 1;
BA_ "GenMsgILSupport" BO_ 1419 0;
BA_ "GenMsgSendType" BO_ 796 5;
BA_ "GenMsgCycleTime" BO_ 796 1000;
BA_ "FrameGatewayNetwork" BO_ 796 "HS1_CAN";
BA_ "FrameGatewayId" BO_ 796 1084;
BA_ "GenMsgSendType" BO_ 1364 1;
BA_ "NmMessage" BO_ 1364 1;
BA_ "GenMsgILSupport" BO_ 1364 0;
BA_ "GenMsgSendType" BO_ 1383 1;
BA_ "NmMessage" BO_ 1383 1;
BA_ "GenMsgILSupport" BO_ 1383 0;
BA_ "GenMsgCycleTime" BO_ 883 1000;
BA_ "GenMsgSendType" BO_ 883 0;
BA_ "GenMsgCycleTime" BO_ 884 1000;
BA_ "GenMsgSendType" BO_ 884 0;
BA_ "NetworkInitialization" BO_ 1438 0;
BA_ "GenMsgCycleTime" BO_ 1438 1000;
BA_ "GenMsgSendType" BO_ 1438 5;
BA_ "NmAsrMessage" BO_ 1438 1;
BA_ "GenMsgILSupport" BO_ 1438 0;
BA_ "GenMsgCycleTime" BO_ 841 1000;
BA_ "GenMsgSendType" BO_ 841 5;
BA_ "GenMsgCycleTime" BO_ 1075 1000;
BA_ "GenMsgSendType" BO_ 1075 5;
BA_ "NetworkInitialization" BO_ 1963 0;
BA_ "GenMsgDelayTime" BO_ 1963 0;
BA_ "GenMsgSendType" BO_ 1963 1;
BA_ "DiagResponse" BO_ 1963 1;
BA_ "GenMsgILSupport" BO_ 1963 0;
BA_ "NetworkInitialization" BO_ 1955 0;
BA_ "GenMsgDelayTime" BO_ 1955 0;
BA_ "GenMsgSendType" BO_ 1955 1;
BA_ "DiagRequest" BO_ 1955 1;
BA_ "GenMsgILSupport" BO_ 1955 0;
BA_ "GenMsgSendType" BO_ 1285 1;
BA_ "NmMessage" BO_ 1285 1;
BA_ "GenMsgILSupport" BO_ 1285 0;
BA_ "GenMsgCycleTime" BO_ 1045 100;
BA_ "GenMsgSendType" BO_ 1045 0;
BA_ "GenMsgRoutingTimeoutTime" BO_ 1045 60;
BA_ "MessageGateway" BO_ 1045 1;
BA_ "NetworkInitialization" BO_ 1413 0;
BA_ "GenMsgCycleTime" BO_ 1413 1000;
BA_ "GenMsgSendType" BO_ 1413 0;
BA_ "NmAsrMessage" BO_ 1413 1;
BA_ "GenMsgILSupport" BO_ 1413 0;
BA_ "NetworkInitialization" BO_ 1412 0;
BA_ "GenMsgCycleTime" BO_ 1412 1000;
BA_ "GenMsgSendType" BO_ 1412 0;
BA_ "NmAsrMessage" BO_ 1412 1;
BA_ "GenMsgILSupport" BO_ 1412 0;
BA_ "GenMsgCycleTime" BO_ 1079 1000;
BA_ "GenMsgSendType" BO_ 1079 5;
BA_ "GenMsgCycleTime" BO_ 941 50;
BA_ "GenMsgSendType" BO_ 941 0;
BA_ "GenMsgCycleTime" BO_ 940 50;
BA_ "GenMsgSendType" BO_ 940 0;
BA_ "U_P702_MY2021_Tx" SG_ 877 AAR_Btn_Stt 1;
BA_ "U_CX727_MY2021_Tx" SG_ 877 AAR_Btn_Stt 1;
BA_ "U_U611_U625_MY20_Phev_Tx" SG_ 877 AAR_Btn_Stt 1;
BA_ "U_U611_U625_MY20_Hev_Tx" SG_ 877 AAR_Btn_Stt 1;
BA_ "U_U611_U625_MY20_Gas_Tx" SG_ 877 AAR_Btn_Stt 1;
BA_ "GenSigStartValue" SG_ 877 AAR_Btn_Stt 2;
BA_ "GenSigStartValueInteger" SG_ 877 AAR_Btn_Stt 2;
BA_ "GenSigSendType" SG_ 877 AAR_Btn_Stt 3;
BA_ "U_CX430_MY2021_Tx" SG_ 914 SodSlotRight_D_Stat 1;
BA_ "U_U611_U625_MY20_Phev_Tx" SG_ 914 SodSlotRight_D_Stat 1;
BA_ "U_U611_U625_MY20_Hev_Tx" SG_ 914 SodSlotRight_D_Stat 1;
BA_ "U_U611_U625_MY20_Gas_Tx" SG_ 914 SodSlotRight_D_Stat 1;
BA_ "U_CX430_MY2021_Tx" SG_ 914 ApaSlotStrtRight_L_Actl 1;
BA_ "U_U611_U625_MY20_Phev_Tx" SG_ 914 ApaSlotStrtRight_L_Actl 1;
BA_ "U_U611_U625_MY20_Hev_Tx" SG_ 914 ApaSlotStrtRight_L_Actl 1;
BA_ "U_U611_U625_MY20_Gas_Tx" SG_ 914 ApaSlotStrtRight_L_Actl 1;
BA_ "U_CX430_MY2021_Tx" SG_ 914 ApaSlotEndRight_L_Actl 1;
BA_ "U_U611_U625_MY20_Phev_Tx" SG_ 914 ApaSlotEndRight_L_Actl 1;
BA_ "U_U611_U625_MY20_Hev_Tx" SG_ 914 ApaSlotEndRight_L_Actl 1;
BA_ "U_U611_U625_MY20_Gas_Tx" SG_ 914 ApaSlotEndRight_L_Actl 1;
BA_ "U_CX430_MY2021_Rx" SG_ 918 ApaWrldToSlot_T_Actl 1;
BA_ "U_U611_U625_MY20_Phev_Rx" SG_ 918 ApaWrldToSlot_T_Actl 1;
BA_ "U_U611_U625_MY20_Hev_Rx" SG_ 918 ApaWrldToSlot_T_Actl 1;
BA_ "U_U611_U625_MY20_Gas_Rx" SG_ 918 ApaWrldToSlot_T_Actl 1;
BA_ "U_CX430_MY2021_Rx" SG_ 918 ApaVehPosY_L_Actl 1;
BA_ "U_U611_U625_MY20_Phev_Rx" SG_ 918 ApaVehPosY_L_Actl 1;
BA_ "U_U611_U625_MY20_Hev_Rx" SG_ 918 ApaVehPosY_L_Actl 1;
BA_ "U_U611_U625_MY20_Gas_Rx" SG_ 918 ApaVehPosY_L_Actl 1;
BA_ "GenSigStartValueInteger" SG_ 918 ApaVehPosY_L_Actl 512;
BA_ "U_CX430_MY2021_Rx" SG_ 918 ApaVehPosX_L_Actl 1;
BA_ "U_U611_U625_MY20_Phev_Rx" SG_ 918 ApaVehPosX_L_Actl 1;
BA_ "U_U611_U625_MY20_Hev_Rx" SG_ 918 ApaVehPosX_L_Actl 1;
BA_ "U_U611_U625_MY20_Gas_Rx" SG_ 918 ApaVehPosX_L_Actl 1;
BA_ "GenSigStartValueInteger" SG_ 918 ApaVehPosX_L_Actl 512;
BA_ "U_CX430_MY2021_Rx" SG_ 918 ApaVehPos_An_Actl 1;
BA_ "U_U611_U625_MY20_Phev_Rx" SG_ 918 ApaVehPos_An_Actl 1;
BA_ "U_U611_U625_MY20_Hev_Rx" SG_ 918 ApaVehPos_An_Actl 1;
BA_ "U_U611_U625_MY20_Gas_Rx" SG_ 918 ApaVehPos_An_Actl 1;
BA_ "GenSigStartValueInteger" SG_ 918 ApaVehPos_An_Actl 512;
BA_ "U_CX430_MY2021_Rx" SG_ 918 ApaClk_T_Actl 1;
BA_ "U_U611_U625_MY20_Phev_Rx" SG_ 918 ApaClk_T_Actl 1;
BA_ "U_U611_U625_MY20_Hev_Rx" SG_ 918 ApaClk_T_Actl 1;
BA_ "U_U611_U625_MY20_Gas_Rx" SG_ 918 ApaClk_T_Actl 1;
BA_ "U_CX430_MY2021_Rx" SG_ 917 PrkAsstSlotId_D_Stat 1;
BA_ "U_U611_U625_MY20_Phev_Rx" SG_ 917 PrkAsstSlotId_D_Stat 1;
BA_ "U_U611_U625_MY20_Hev_Rx" SG_ 917 PrkAsstSlotId_D_Stat 1;
BA_ "U_U611_U625_MY20_Gas_Rx" SG_ 917 PrkAsstSlotId_D_Stat 1;
BA_ "U_CX430_MY2021_Rx" SG_ 917 ApaVehToSlotY_L_Actl 1;
BA_ "U_U611_U625_MY20_Phev_Rx" SG_ 917 ApaVehToSlotY_L_Actl 1;
BA_ "U_U611_U625_MY20_Hev_Rx" SG_ 917 ApaVehToSlotY_L_Actl 1;
BA_ "U_U611_U625_MY20_Gas_Rx" SG_ 917 ApaVehToSlotY_L_Actl 1;
BA_ "GenSigStartValueInteger" SG_ 917 ApaVehToSlotY_L_Actl 512;
BA_ "U_CX430_MY2021_Rx" SG_ 917 ApaVehToSlotX_L_Actl 1;
BA_ "U_U611_U625_MY20_Phev_Rx" SG_ 917 ApaVehToSlotX_L_Actl 1;
BA_ "U_U611_U625_MY20_Hev_Rx" SG_ 917 ApaVehToSlotX_L_Actl 1;
BA_ "U_U611_U625_MY20_Gas_Rx" SG_ 917 ApaVehToSlotX_L_Actl 1;
BA_ "GenSigStartValueInteger" SG_ 917 ApaVehToSlotX_L_Actl 512;
BA_ "U_CX430_MY2021_Rx" SG_ 917 ApaVehToSlot_T_Actl 1;
BA_ "U_U611_U625_MY20_Phev_Rx" SG_ 917 ApaVehToSlot_T_Actl 1;
BA_ "U_U611_U625_MY20_Hev_Rx" SG_ 917 ApaVehToSlot_T_Actl 1;
BA_ "U_U611_U625_MY20_Gas_Rx" SG_ 917 ApaVehToSlot_T_Actl 1;
BA_ "U_CX430_MY2021_Rx" SG_ 917 ApaVehToSlot_An_Actl 1;
BA_ "U_U611_U625_MY20_Phev_Rx" SG_ 917 ApaVehToSlot_An_Actl 1;
BA_ "U_U611_U625_MY20_Hev_Rx" SG_ 917 ApaVehToSlot_An_Actl 1;
BA_ "U_U611_U625_MY20_Gas_Rx" SG_ 917 ApaVehToSlot_An_Actl 1;
BA_ "GenSigStartValueInteger" SG_ 917 ApaVehToSlot_An_Actl 127.44713132172;
BA_ "U_CX430_MY2021_Rx" SG_ 915 ApaObjStrtY_L_Actl 1;
BA_ "U_U611_U625_MY20_Phev_Rx" SG_ 915 ApaObjStrtY_L_Actl 1;
BA_ "U_U611_U625_MY20_Hev_Rx" SG_ 915 ApaObjStrtY_L_Actl 1;
BA_ "U_U611_U625_MY20_Gas_Rx" SG_ 915 ApaObjStrtY_L_Actl 1;
BA_ "GenSigStartValueInteger" SG_ 915 ApaObjStrtY_L_Actl 187;
BA_ "U_CX430_MY2021_Rx" SG_ 915 ApaObjStrtX_L_Actl 1;
BA_ "U_U611_U625_MY20_Phev_Rx" SG_ 915 ApaObjStrtX_L_Actl 1;
BA_ "U_U611_U625_MY20_Hev_Rx" SG_ 915 ApaObjStrtX_L_Actl 1;
BA_ "U_U611_U625_MY20_Gas_Rx" SG_ 915 ApaObjStrtX_L_Actl 1;
BA_ "GenSigStartValueInteger" SG_ 915 ApaObjStrtX_L_Actl 187;
BA_ "U_CX430_MY2021_Rx" SG_ 915 ApaObjStrtDpthY_L_Actl 1;
BA_ "U_U611_U625_MY20_Phev_Rx" SG_ 915 ApaObjStrtDpthY_L_Actl 1;
BA_ "U_U611_U625_MY20_Hev_Rx" SG_ 915 ApaObjStrtDpthY_L_Actl 1;
BA_ "U_U611_U625_MY20_Gas_Rx" SG_ 915 ApaObjStrtDpthY_L_Actl 1;
BA_ "GenSigStartValueInteger" SG_ 915 ApaObjStrtDpthY_L_Actl 187;
BA_ "U_CX430_MY2021_Rx" SG_ 915 ApaObjStrtDpthX_L_Actl 1;
BA_ "U_U611_U625_MY20_Phev_Rx" SG_ 915 ApaObjStrtDpthX_L_Actl 1;
BA_ "U_U611_U625_MY20_Hev_Rx" SG_ 915 ApaObjStrtDpthX_L_Actl 1;
BA_ "U_U611_U625_MY20_Gas_Rx" SG_ 915 ApaObjStrtDpthX_L_Actl 1;
BA_ "GenSigStartValueInteger" SG_ 915 ApaObjStrtDpthX_L_Actl 187;
BA_ "U_CX430_MY2021_Rx" SG_ 915 ApaObjEndY_L_Actl 1;
BA_ "U_U611_U625_MY20_Phev_Rx" SG_ 915 ApaObjEndY_L_Actl 1;
BA_ "U_U611_U625_MY20_Hev_Rx" SG_ 915 ApaObjEndY_L_Actl 1;
BA_ "U_U611_U625_MY20_Gas_Rx" SG_ 915 ApaObjEndY_L_Actl 1;
BA_ "GenSigStartValueInteger" SG_ 915 ApaObjEndY_L_Actl 187;
BA_ "U_CX430_MY2021_Rx" SG_ 915 ApaObjEndX_L_Actl 1;
BA_ "U_U611_U625_MY20_Phev_Rx" SG_ 915 ApaObjEndX_L_Actl 1;
BA_ "U_U611_U625_MY20_Hev_Rx" SG_ 915 ApaObjEndX_L_Actl 1;
BA_ "U_U611_U625_MY20_Gas_Rx" SG_ 915 ApaObjEndX_L_Actl 1;
BA_ "GenSigStartValueInteger" SG_ 915 ApaObjEndX_L_Actl 187;
BA_ "U_CX430_MY2021_Rx" SG_ 915 ApaObjEndDpthY_L_Actl 1;
BA_ "U_U611_U625_MY20_Phev_Rx" SG_ 915 ApaObjEndDpthY_L_Actl 1;
BA_ "U_U611_U625_MY20_Hev_Rx" SG_ 915 ApaObjEndDpthY_L_Actl 1;
BA_ "U_U611_U625_MY20_Gas_Rx" SG_ 915 ApaObjEndDpthY_L_Actl 1;
BA_ "GenSigStartValueInteger" SG_ 915 ApaObjEndDpthY_L_Actl 187;
BA_ "U_CX430_MY2021_Rx" SG_ 915 ApaObjEndDpthX_L_Actl 1;
BA_ "U_U611_U625_MY20_Phev_Rx" SG_ 915 ApaObjEndDpthX_L_Actl 1;
BA_ "U_U611_U625_MY20_Hev_Rx" SG_ 915 ApaObjEndDpthX_L_Actl 1;
BA_ "U_U611_U625_MY20_Gas_Rx" SG_ 915 ApaObjEndDpthX_L_Actl 1;
BA_ "GenSigStartValueInteger" SG_ 915 ApaObjEndDpthX_L_Actl 187;
BA_ "U_CX430_MY2021_Tx" SG_ 913 SodSlotLeft_D_Stat 1;
BA_ "U_U611_U625_MY20_Phev_Tx" SG_ 913 SodSlotLeft_D_Stat 1;
BA_ "U_U611_U625_MY20_Hev_Tx" SG_ 913 SodSlotLeft_D_Stat 1;
BA_ "U_U611_U625_MY20_Gas_Tx" SG_ 913 SodSlotLeft_D_Stat 1;
BA_ "U_CX430_MY2021_Tx" SG_ 913 ApaSlotEndLeft_L_Actl 1;
BA_ "U_U611_U625_MY20_Phev_Tx" SG_ 913 ApaSlotEndLeft_L_Actl 1;
BA_ "U_U611_U625_MY20_Hev_Tx" SG_ 913 ApaSlotEndLeft_L_Actl 1;
BA_ "U_U611_U625_MY20_Gas_Tx" SG_ 913 ApaSlotEndLeft_L_Actl 1;
BA_ "U_CX430_MY2021_Tx" SG_ 913 ApaSlotStrtLeft_L_Actl 1;
BA_ "U_U611_U625_MY20_Phev_Tx" SG_ 913 ApaSlotStrtLeft_L_Actl 1;
BA_ "U_U611_U625_MY20_Hev_Tx" SG_ 913 ApaSlotStrtLeft_L_Actl 1;
BA_ "U_U611_U625_MY20_Gas_Tx" SG_ 913 ApaSlotStrtLeft_L_Actl 1;
BA_ "GenSigSendType" SG_ 1067 ElCmpr_N_Actl_UB 3;
BA_ "GenSigSendType" SG_ 1067 ElCmpr_D_Stat_UB 3;
BA_ "GenSigSendType" SG_ 1067 ElCmpr_N_Actl 3;
BA_ "GenSigSendType" SG_ 1067 ElCmpr_D_Stat 3;
BA_ "U_C519_MY18_5_Diesel_Rx" SG_ 933 BttRightIndex2_No_Actl 1;
BA_ "U_C519_MY18_5_Gas_Rx" SG_ 933 BttRightIndex2_No_Actl 1;
BA_ "U_U611_U625_MY20_Gas_Rx" SG_ 933 BttRightIndex2_No_Actl 1;
BA_ "U_U611_U625_MY20_Hev_Rx" SG_ 933 BttRightIndex2_No_Actl 1;
BA_ "U_U611_U625_MY20_Phev_Rx" SG_ 933 BttRightIndex2_No_Actl 1;
BA_ "U_CX430_MY2021_Rx" SG_ 933 BttRightIndex2_No_Actl 1;
BA_ "U_B479_MY17_Gas_Tx" SG_ 933 BttRightIndex2_No_Actl 1;
BA_ "U_B479_MY17_Diesel_Tx" SG_ 933 BttRightIndex2_No_Actl 1;
BA_ "U_B515_MCA_MY17_Diesel_Tx" SG_ 933 BttRightIndex2_No_Actl 1;
BA_ "U_B515_MCA_MY17_Gas_Tx" SG_ 933 BttRightIndex2_No_Actl 1;
BA_ "U_C519_MY18_5_Diesel_Tx" SG_ 933 BttRightIndex2_No_Actl 1;
BA_ "U_C519_MY18_5_Gas_Tx" SG_ 933 BttRightIndex2_No_Actl 1;
BA_ "U_U611_U625_MY20_Gas_Tx" SG_ 933 BttRightIndex2_No_Actl 1;
BA_ "U_U611_U625_MY20_Hev_Tx" SG_ 933 BttRightIndex2_No_Actl 1;
BA_ "U_U611_U625_MY20_Phev_Tx" SG_ 933 BttRightIndex2_No_Actl 1;
BA_ "U_CX430_MY2021_Tx" SG_ 933 BttRightIndex2_No_Actl 1;
BA_ "U_C519_MY18_5_Diesel_Rx" SG_ 933 BttRightIndex1_No_Actl 1;
BA_ "U_C519_MY18_5_Gas_Rx" SG_ 933 BttRightIndex1_No_Actl 1;
BA_ "U_U611_U625_MY20_Gas_Rx" SG_ 933 BttRightIndex1_No_Actl 1;
BA_ "U_U611_U625_MY20_Hev_Rx" SG_ 933 BttRightIndex1_No_Actl 1;
BA_ "U_U611_U625_MY20_Phev_Rx" SG_ 933 BttRightIndex1_No_Actl 1;
BA_ "U_CX430_MY2021_Rx" SG_ 933 BttRightIndex1_No_Actl 1;
BA_ "U_B479_MY17_Gas_Tx" SG_ 933 BttRightIndex1_No_Actl 1;
BA_ "U_B479_MY17_Diesel_Tx" SG_ 933 BttRightIndex1_No_Actl 1;
BA_ "U_B515_MCA_MY17_Diesel_Tx" SG_ 933 BttRightIndex1_No_Actl 1;
BA_ "U_B515_MCA_MY17_Gas_Tx" SG_ 933 BttRightIndex1_No_Actl 1;
BA_ "U_C519_MY18_5_Diesel_Tx" SG_ 933 BttRightIndex1_No_Actl 1;
BA_ "U_C519_MY18_5_Gas_Tx" SG_ 933 BttRightIndex1_No_Actl 1;
BA_ "U_U611_U625_MY20_Gas_Tx" SG_ 933 BttRightIndex1_No_Actl 1;
BA_ "U_U611_U625_MY20_Hev_Tx" SG_ 933 BttRightIndex1_No_Actl 1;
BA_ "U_U611_U625_MY20_Phev_Tx" SG_ 933 BttRightIndex1_No_Actl 1;
BA_ "U_CX430_MY2021_Tx" SG_ 933 BttRightIndex1_No_Actl 1;
BA_ "U_C519_MY18_5_Diesel_Rx" SG_ 933 BttRightData2_No_Actl 1;
BA_ "U_C519_MY18_5_Gas_Rx" SG_ 933 BttRightData2_No_Actl 1;
BA_ "U_U611_U625_MY20_Gas_Rx" SG_ 933 BttRightData2_No_Actl 1;
BA_ "U_U611_U625_MY20_Hev_Rx" SG_ 933 BttRightData2_No_Actl 1;
BA_ "U_U611_U625_MY20_Phev_Rx" SG_ 933 BttRightData2_No_Actl 1;
BA_ "U_CX430_MY2021_Rx" SG_ 933 BttRightData2_No_Actl 1;
BA_ "U_B479_MY17_Gas_Tx" SG_ 933 BttRightData2_No_Actl 1;
BA_ "U_B479_MY17_Diesel_Tx" SG_ 933 BttRightData2_No_Actl 1;
BA_ "U_B515_MCA_MY17_Diesel_Tx" SG_ 933 BttRightData2_No_Actl 1;
BA_ "U_B515_MCA_MY17_Gas_Tx" SG_ 933 BttRightData2_No_Actl 1;
BA_ "U_C519_MY18_5_Diesel_Tx" SG_ 933 BttRightData2_No_Actl 1;
BA_ "U_C519_MY18_5_Gas_Tx" SG_ 933 BttRightData2_No_Actl 1;
BA_ "U_U611_U625_MY20_Gas_Tx" SG_ 933 BttRightData2_No_Actl 1;
BA_ "U_U611_U625_MY20_Hev_Tx" SG_ 933 BttRightData2_No_Actl 1;
BA_ "U_U611_U625_MY20_Phev_Tx" SG_ 933 BttRightData2_No_Actl 1;
BA_ "U_CX430_MY2021_Tx" SG_ 933 BttRightData2_No_Actl 1;
BA_ "U_C519_MY18_5_Diesel_Rx" SG_ 933 BttRightData1_No_Actl 1;
BA_ "U_C519_MY18_5_Gas_Rx" SG_ 933 BttRightData1_No_Actl 1;
BA_ "U_U611_U625_MY20_Gas_Rx" SG_ 933 BttRightData1_No_Actl 1;
BA_ "U_U611_U625_MY20_Hev_Rx" SG_ 933 BttRightData1_No_Actl 1;
BA_ "U_U611_U625_MY20_Phev_Rx" SG_ 933 BttRightData1_No_Actl 1;
BA_ "U_CX430_MY2021_Rx" SG_ 933 BttRightData1_No_Actl 1;
BA_ "U_B479_MY17_Gas_Tx" SG_ 933 BttRightData1_No_Actl 1;
BA_ "U_B479_MY17_Diesel_Tx" SG_ 933 BttRightData1_No_Actl 1;
BA_ "U_B515_MCA_MY17_Diesel_Tx" SG_ 933 BttRightData1_No_Actl 1;
BA_ "U_B515_MCA_MY17_Gas_Tx" SG_ 933 BttRightData1_No_Actl 1;
BA_ "U_C519_MY18_5_Diesel_Tx" SG_ 933 BttRightData1_No_Actl 1;
BA_ "U_C519_MY18_5_Gas_Tx" SG_ 933 BttRightData1_No_Actl 1;
BA_ "U_U611_U625_MY20_Gas_Tx" SG_ 933 BttRightData1_No_Actl 1;
BA_ "U_U611_U625_MY20_Hev_Tx" SG_ 933 BttRightData1_No_Actl 1;
BA_ "U_U611_U625_MY20_Phev_Tx" SG_ 933 BttRightData1_No_Actl 1;
BA_ "U_CX430_MY2021_Tx" SG_ 933 BttRightData1_No_Actl 1;
BA_ "U_C519_MY18_5_Diesel_Rx" SG_ 933 BttRight_T_Actl 1;
BA_ "U_C519_MY18_5_Gas_Rx" SG_ 933 BttRight_T_Actl 1;
BA_ "U_U611_U625_MY20_Gas_Rx" SG_ 933 BttRight_T_Actl 1;
BA_ "U_U611_U625_MY20_Hev_Rx" SG_ 933 BttRight_T_Actl 1;
BA_ "U_U611_U625_MY20_Phev_Rx" SG_ 933 BttRight_T_Actl 1;
BA_ "U_CX430_MY2021_Rx" SG_ 933 BttRight_T_Actl 1;
BA_ "U_B479_MY17_Gas_Tx" SG_ 933 BttRight_T_Actl 1;
BA_ "U_B479_MY17_Diesel_Tx" SG_ 933 BttRight_T_Actl 1;
BA_ "U_B515_MCA_MY17_Diesel_Tx" SG_ 933 BttRight_T_Actl 1;
BA_ "U_B515_MCA_MY17_Gas_Tx" SG_ 933 BttRight_T_Actl 1;
BA_ "U_C519_MY18_5_Diesel_Tx" SG_ 933 BttRight_T_Actl 1;
BA_ "U_C519_MY18_5_Gas_Tx" SG_ 933 BttRight_T_Actl 1;
BA_ "U_U611_U625_MY20_Gas_Tx" SG_ 933 BttRight_T_Actl 1;
BA_ "U_U611_U625_MY20_Hev_Tx" SG_ 933 BttRight_T_Actl 1;
BA_ "U_U611_U625_MY20_Phev_Tx" SG_ 933 BttRight_T_Actl 1;
BA_ "U_CX430_MY2021_Tx" SG_ 933 BttRight_T_Actl 1;
BA_ "U_B515_MCA_MY17_Diesel_Rx" SG_ 932 BttLeftIndex2_No_Actl 1;
BA_ "U_B515_MCA_MY17_Gas_Rx" SG_ 932 BttLeftIndex2_No_Actl 1;
BA_ "U_C519_MY18_5_Diesel_Rx" SG_ 932 BttLeftIndex2_No_Actl 1;
BA_ "U_C519_MY18_5_Gas_Rx" SG_ 932 BttLeftIndex2_No_Actl 1;
BA_ "U_U611_U625_MY20_Gas_Rx" SG_ 932 BttLeftIndex2_No_Actl 1;
BA_ "U_U611_U625_MY20_Hev_Rx" SG_ 932 BttLeftIndex2_No_Actl 1;
BA_ "U_U611_U625_MY20_Phev_Rx" SG_ 932 BttLeftIndex2_No_Actl 1;
BA_ "U_CX430_MY2021_Rx" SG_ 932 BttLeftIndex2_No_Actl 1;
BA_ "U_B479_MY17_Gas_Tx" SG_ 932 BttLeftIndex2_No_Actl 1;
BA_ "U_B479_MY17_Diesel_Tx" SG_ 932 BttLeftIndex2_No_Actl 1;
BA_ "U_B515_MCA_MY17_Diesel_Tx" SG_ 932 BttLeftIndex2_No_Actl 1;
BA_ "U_B515_MCA_MY17_Gas_Tx" SG_ 932 BttLeftIndex2_No_Actl 1;
BA_ "U_C519_MY18_5_Diesel_Tx" SG_ 932 BttLeftIndex2_No_Actl 1;
BA_ "U_C519_MY18_5_Gas_Tx" SG_ 932 BttLeftIndex2_No_Actl 1;
BA_ "U_U611_U625_MY20_Gas_Tx" SG_ 932 BttLeftIndex2_No_Actl 1;
BA_ "U_U611_U625_MY20_Hev_Tx" SG_ 932 BttLeftIndex2_No_Actl 1;
BA_ "U_U611_U625_MY20_Phev_Tx" SG_ 932 BttLeftIndex2_No_Actl 1;
BA_ "U_CX430_MY2021_Tx" SG_ 932 BttLeftIndex2_No_Actl 1;
BA_ "U_B515_MCA_MY17_Diesel_Rx" SG_ 932 BttLeftIndex1_No_Actl 1;
BA_ "U_B515_MCA_MY17_Gas_Rx" SG_ 932 BttLeftIndex1_No_Actl 1;
BA_ "U_C519_MY18_5_Diesel_Rx" SG_ 932 BttLeftIndex1_No_Actl 1;
BA_ "U_C519_MY18_5_Gas_Rx" SG_ 932 BttLeftIndex1_No_Actl 1;
BA_ "U_U611_U625_MY20_Gas_Rx" SG_ 932 BttLeftIndex1_No_Actl 1;
BA_ "U_U611_U625_MY20_Hev_Rx" SG_ 932 BttLeftIndex1_No_Actl 1;
BA_ "U_U611_U625_MY20_Phev_Rx" SG_ 932 BttLeftIndex1_No_Actl 1;
BA_ "U_CX430_MY2021_Rx" SG_ 932 BttLeftIndex1_No_Actl 1;
BA_ "U_B479_MY17_Gas_Tx" SG_ 932 BttLeftIndex1_No_Actl 1;
BA_ "U_B479_MY17_Diesel_Tx" SG_ 932 BttLeftIndex1_No_Actl 1;
BA_ "U_B515_MCA_MY17_Diesel_Tx" SG_ 932 BttLeftIndex1_No_Actl 1;
BA_ "U_B515_MCA_MY17_Gas_Tx" SG_ 932 BttLeftIndex1_No_Actl 1;
BA_ "U_C519_MY18_5_Diesel_Tx" SG_ 932 BttLeftIndex1_No_Actl 1;
BA_ "U_C519_MY18_5_Gas_Tx" SG_ 932 BttLeftIndex1_No_Actl 1;
BA_ "U_U611_U625_MY20_Gas_Tx" SG_ 932 BttLeftIndex1_No_Actl 1;
BA_ "U_U611_U625_MY20_Hev_Tx" SG_ 932 BttLeftIndex1_No_Actl 1;
BA_ "U_U611_U625_MY20_Phev_Tx" SG_ 932 BttLeftIndex1_No_Actl 1;
BA_ "U_CX430_MY2021_Tx" SG_ 932 BttLeftIndex1_No_Actl 1;
BA_ "U_B515_MCA_MY17_Diesel_Rx" SG_ 932 BttLeftData2_No_Actl 1;
BA_ "U_B515_MCA_MY17_Gas_Rx" SG_ 932 BttLeftData2_No_Actl 1;
BA_ "U_C519_MY18_5_Diesel_Rx" SG_ 932 BttLeftData2_No_Actl 1;
BA_ "U_C519_MY18_5_Gas_Rx" SG_ 932 BttLeftData2_No_Actl 1;
BA_ "U_U611_U625_MY20_Gas_Rx" SG_ 932 BttLeftData2_No_Actl 1;
BA_ "U_U611_U625_MY20_Hev_Rx" SG_ 932 BttLeftData2_No_Actl 1;
BA_ "U_U611_U625_MY20_Phev_Rx" SG_ 932 BttLeftData2_No_Actl 1;
BA_ "U_CX430_MY2021_Rx" SG_ 932 BttLeftData2_No_Actl 1;
BA_ "U_B479_MY17_Gas_Tx" SG_ 932 BttLeftData2_No_Actl 1;
BA_ "U_B479_MY17_Diesel_Tx" SG_ 932 BttLeftData2_No_Actl 1;
BA_ "U_B515_MCA_MY17_Diesel_Tx" SG_ 932 BttLeftData2_No_Actl 1;
BA_ "U_B515_MCA_MY17_Gas_Tx" SG_ 932 BttLeftData2_No_Actl 1;
BA_ "U_C519_MY18_5_Diesel_Tx" SG_ 932 BttLeftData2_No_Actl 1;
BA_ "U_C519_MY18_5_Gas_Tx" SG_ 932 BttLeftData2_No_Actl 1;
BA_ "U_U611_U625_MY20_Gas_Tx" SG_ 932 BttLeftData2_No_Actl 1;
BA_ "U_U611_U625_MY20_Hev_Tx" SG_ 932 BttLeftData2_No_Actl 1;
BA_ "U_U611_U625_MY20_Phev_Tx" SG_ 932 BttLeftData2_No_Actl 1;
BA_ "U_CX430_MY2021_Tx" SG_ 932 BttLeftData2_No_Actl 1;
BA_ "U_B515_MCA_MY17_Diesel_Rx" SG_ 932 BttLeftData1_No_Actl 1;
BA_ "U_B515_MCA_MY17_Gas_Rx" SG_ 932 BttLeftData1_No_Actl 1;
BA_ "U_C519_MY18_5_Diesel_Rx" SG_ 932 BttLeftData1_No_Actl 1;
BA_ "U_C519_MY18_5_Gas_Rx" SG_ 932 BttLeftData1_No_Actl 1;
BA_ "U_U611_U625_MY20_Gas_Rx" SG_ 932 BttLeftData1_No_Actl 1;
BA_ "U_U611_U625_MY20_Hev_Rx" SG_ 932 BttLeftData1_No_Actl 1;
BA_ "U_U611_U625_MY20_Phev_Rx" SG_ 932 BttLeftData1_No_Actl 1;
BA_ "U_CX430_MY2021_Rx" SG_ 932 BttLeftData1_No_Actl 1;
BA_ "U_B479_MY17_Gas_Tx" SG_ 932 BttLeftData1_No_Actl 1;
BA_ "U_B479_MY17_Diesel_Tx" SG_ 932 BttLeftData1_No_Actl 1;
BA_ "U_B515_MCA_MY17_Diesel_Tx" SG_ 932 BttLeftData1_No_Actl 1;
BA_ "U_B515_MCA_MY17_Gas_Tx" SG_ 932 BttLeftData1_No_Actl 1;
BA_ "U_C519_MY18_5_Diesel_Tx" SG_ 932 BttLeftData1_No_Actl 1;
BA_ "U_C519_MY18_5_Gas_Tx" SG_ 932 BttLeftData1_No_Actl 1;
BA_ "U_U611_U625_MY20_Gas_Tx" SG_ 932 BttLeftData1_No_Actl 1;
BA_ "U_U611_U625_MY20_Hev_Tx" SG_ 932 BttLeftData1_No_Actl 1;
BA_ "U_U611_U625_MY20_Phev_Tx" SG_ 932 BttLeftData1_No_Actl 1;
BA_ "U_CX430_MY2021_Tx" SG_ 932 BttLeftData1_No_Actl 1;
BA_ "U_B515_MCA_MY17_Diesel_Rx" SG_ 932 BttLeft_T_Actl 1;
BA_ "U_B515_MCA_MY17_Gas_Rx" SG_ 932 BttLeft_T_Actl 1;
BA_ "U_C519_MY18_5_Diesel_Rx" SG_ 932 BttLeft_T_Actl 1;
BA_ "U_C519_MY18_5_Gas_Rx" SG_ 932 BttLeft_T_Actl 1;
BA_ "U_U611_U625_MY20_Gas_Rx" SG_ 932 BttLeft_T_Actl 1;
BA_ "U_U611_U625_MY20_Hev_Rx" SG_ 932 BttLeft_T_Actl 1;
BA_ "U_U611_U625_MY20_Phev_Rx" SG_ 932 BttLeft_T_Actl 1;
BA_ "U_CX430_MY2021_Rx" SG_ 932 BttLeft_T_Actl 1;
BA_ "U_B479_MY17_Gas_Tx" SG_ 932 BttLeft_T_Actl 1;
BA_ "U_B479_MY17_Diesel_Tx" SG_ 932 BttLeft_T_Actl 1;
BA_ "U_B515_MCA_MY17_Diesel_Tx" SG_ 932 BttLeft_T_Actl 1;
BA_ "U_B515_MCA_MY17_Gas_Tx" SG_ 932 BttLeft_T_Actl 1;
BA_ "U_C519_MY18_5_Diesel_Tx" SG_ 932 BttLeft_T_Actl 1;
BA_ "U_C519_MY18_5_Gas_Tx" SG_ 932 BttLeft_T_Actl 1;
BA_ "U_U611_U625_MY20_Gas_Tx" SG_ 932 BttLeft_T_Actl 1;
BA_ "U_U611_U625_MY20_Hev_Tx" SG_ 932 BttLeft_T_Actl 1;
BA_ "U_U611_U625_MY20_Phev_Tx" SG_ 932 BttLeft_T_Actl 1;
BA_ "U_CX430_MY2021_Tx" SG_ 932 BttLeft_T_Actl 1;
BA_ "CrossOver_InfoCAN" SG_ 838 FohStrtDay_T_Rq 1;
BA_ "U_C519_MY18_5_Diesel_Rx" SG_ 838 FohStrtDay_T_Rq 1;
BA_ "U_C519_MY18_5_Gas_Rx" SG_ 838 FohStrtDay_T_Rq 1;
BA_ "U_CX482_CX483_MY20_Rx" SG_ 838 FohStrtDay_T_Rq 1;
BA_ "CrossOver_InfoCAN" SG_ 838 FohStop_B_Rq 1;
BA_ "GenSigStartValueInteger" SG_ 838 FohStop_B_Rq 3;
BA_ "GenSigStartValue" SG_ 838 FohStop_B_Rq 3;
BA_ "U_C519_MY18_5_Diesel_Rx" SG_ 838 FohStop_B_Rq 1;
BA_ "U_C519_MY18_5_Gas_Rx" SG_ 838 FohStop_B_Rq 1;
BA_ "U_CX482_CX483_MY20_Rx" SG_ 838 FohStop_B_Rq 1;
BA_ "CrossOver_InfoCAN" SG_ 838 FohTAllEnable_B_Rq 1;
BA_ "GenSigStartValueInteger" SG_ 838 FohTAllEnable_B_Rq 3;
BA_ "GenSigStartValue" SG_ 838 FohTAllEnable_B_Rq 3;
BA_ "U_C519_MY18_5_Diesel_Rx" SG_ 838 FohTAllEnable_B_Rq 1;
BA_ "U_C519_MY18_5_Gas_Rx" SG_ 838 FohTAllEnable_B_Rq 1;
BA_ "U_CX482_CX483_MY20_Rx" SG_ 838 FohTAllEnable_B_Rq 1;
BA_ "CrossOver_InfoCAN" SG_ 838 FohT2Mnte_T_Rq 1;
BA_ "U_C519_MY18_5_Diesel_Rx" SG_ 838 FohT2Mnte_T_Rq 1;
BA_ "U_C519_MY18_5_Gas_Rx" SG_ 838 FohT2Mnte_T_Rq 1;
BA_ "U_CX482_CX483_MY20_Rx" SG_ 838 FohT2Mnte_T_Rq 1;
BA_ "CrossOver_InfoCAN" SG_ 838 FohT2Hr_T_Rq 1;
BA_ "U_C519_MY18_5_Diesel_Rx" SG_ 838 FohT2Hr_T_Rq 1;
BA_ "U_C519_MY18_5_Gas_Rx" SG_ 838 FohT2Hr_T_Rq 1;
BA_ "U_CX482_CX483_MY20_Rx" SG_ 838 FohT2Hr_T_Rq 1;
BA_ "CrossOver_InfoCAN" SG_ 838 FohT2Enable_B_Rq 1;
BA_ "U_C519_MY18_5_Diesel_Rx" SG_ 838 FohT2Enable_B_Rq 1;
BA_ "U_C519_MY18_5_Gas_Rx" SG_ 838 FohT2Enable_B_Rq 1;
BA_ "U_CX482_CX483_MY20_Rx" SG_ 838 FohT2Enable_B_Rq 1;
BA_ "CrossOver_InfoCAN" SG_ 838 FohT1Mnte_T_Rq 1;
BA_ "U_C519_MY18_5_Diesel_Rx" SG_ 838 FohT1Mnte_T_Rq 1;
BA_ "U_C519_MY18_5_Gas_Rx" SG_ 838 FohT1Mnte_T_Rq 1;
BA_ "U_CX482_CX483_MY20_Rx" SG_ 838 FohT1Mnte_T_Rq 1;
BA_ "CrossOver_InfoCAN" SG_ 838 FohT1Hr_T_Rq 1;
BA_ "U_C519_MY18_5_Diesel_Rx" SG_ 838 FohT1Hr_T_Rq 1;
BA_ "U_C519_MY18_5_Gas_Rx" SG_ 838 FohT1Hr_T_Rq 1;
BA_ "U_CX482_CX483_MY20_Rx" SG_ 838 FohT1Hr_T_Rq 1;
BA_ "CrossOver_InfoCAN" SG_ 838 FohT1Enable_B_Rq 1;
BA_ "U_C519_MY18_5_Diesel_Rx" SG_ 838 FohT1Enable_B_Rq 1;
BA_ "U_C519_MY18_5_Gas_Rx" SG_ 838 FohT1Enable_B_Rq 1;
BA_ "U_CX482_CX483_MY20_Rx" SG_ 838 FohT1Enable_B_Rq 1;
BA_ "CrossOver_InfoCAN" SG_ 838 FohStrtMnte_T_Rq 1;
BA_ "U_C519_MY18_5_Diesel_Rx" SG_ 838 FohStrtMnte_T_Rq 1;
BA_ "U_C519_MY18_5_Gas_Rx" SG_ 838 FohStrtMnte_T_Rq 1;
BA_ "U_CX482_CX483_MY20_Rx" SG_ 838 FohStrtMnte_T_Rq 1;
BA_ "CrossOver_InfoCAN" SG_ 838 FohStrtHr_T_Rq 1;
BA_ "U_C519_MY18_5_Diesel_Rx" SG_ 838 FohStrtHr_T_Rq 1;
BA_ "U_C519_MY18_5_Gas_Rx" SG_ 838 FohStrtHr_T_Rq 1;
BA_ "U_CX482_CX483_MY20_Rx" SG_ 838 FohStrtHr_T_Rq 1;
BA_ "CrossOver_InfoCAN" SG_ 838 FohStrtEnable_B_Rq 1;
BA_ "U_C519_MY18_5_Diesel_Rx" SG_ 838 FohStrtEnable_B_Rq 1;
BA_ "U_C519_MY18_5_Gas_Rx" SG_ 838 FohStrtEnable_B_Rq 1;
BA_ "U_CX482_CX483_MY20_Rx" SG_ 838 FohStrtEnable_B_Rq 1;
BA_ "CrossOver_InfoCAN" SG_ 838 FohContOn_B_Rq 1;
BA_ "GenSigStartValueInteger" SG_ 838 FohContOn_B_Rq 3;
BA_ "GenSigStartValue" SG_ 838 FohContOn_B_Rq 3;
BA_ "U_C519_MY18_5_Diesel_Rx" SG_ 838 FohContOn_B_Rq 1;
BA_ "U_C519_MY18_5_Gas_Rx" SG_ 838 FohContOn_B_Rq 1;
BA_ "U_CX482_CX483_MY20_Rx" SG_ 838 FohContOn_B_Rq 1;
BA_ "GenSigSendType" SG_ 1565 CcpDTO_Byte7 3;
BA_ "GenSigSendType" SG_ 1565 CcpDTO_Byte6 3;
BA_ "GenSigSendType" SG_ 1565 CcpDTO_Byte5 3;
BA_ "GenSigSendType" SG_ 1565 CcpDTO_Byte4 3;
BA_ "GenSigSendType" SG_ 1565 CcpDTO_Byte3 3;
BA_ "GenSigSendType" SG_ 1565 CcpDTO_Byte2 3;
BA_ "GenSigSendType" SG_ 1565 CcpDTO_Byte1 3;
BA_ "GenSigSendType" SG_ 1565 CcpDTO_Byte0 3;
BA_ "GenSigSendType" SG_ 1564 CcpCRO_Byte7 3;
BA_ "GenSigSendType" SG_ 1564 CcpCRO_Byte6 3;
BA_ "GenSigSendType" SG_ 1564 CcpCRO_Byte5 3;
BA_ "GenSigSendType" SG_ 1564 CcpCRO_Byte4 3;
BA_ "GenSigSendType" SG_ 1564 CcpCRO_Byte3 3;
BA_ "GenSigSendType" SG_ 1564 CcpCRO_Byte2 3;
BA_ "GenSigSendType" SG_ 1564 CcpCRO_Byte1 3;
BA_ "GenSigSendType" SG_ 1564 CcpCRO_Byte0 3;
BA_ "U_U611_U625_MY20_Phev_Tx" SG_ 773 SeatScrnPsngrOn_B_Rq 1;
BA_ "U_CX482_CX483_MY20_Tx" SG_ 773 SeatScrnPsngrOn_B_Rq 1;
BA_ "U_U611_U625_MY20_Hev_Tx" SG_ 773 SeatScrnPsngrOn_B_Rq 1;
BA_ "U_U611_U625_MY20_Gas_Tx" SG_ 773 SeatScrnPsngrOn_B_Rq 1;
BA_ "GenSigSendType" SG_ 773 SeatScrnPsngrOn_B_Rq 3;
BA_ "U_P702_MY2021_Tx" SG_ 1447 SCME_GWOnBoardTester 1;
BA_ "U_U611_U625_MY20_Phev_Tx" SG_ 1447 SCME_GWOnBoardTester 1;
BA_ "U_CX482_CX483_MY20_Tx" SG_ 1447 SCME_GWOnBoardTester 1;
BA_ "U_U611_U625_MY20_Hev_Tx" SG_ 1447 SCME_GWOnBoardTester 1;
BA_ "U_U611_U625_MY20_Gas_Tx" SG_ 1447 SCME_GWOnBoardTester 1;
BA_ "GenSigStartValue" SG_ 1447 SCME_GWOnBoardTester 255;
BA_ "ContentDependant" SG_ 1447 SCME_GWOnBoardTester 1;
BA_ "GenSigStartValueInteger" SG_ 1447 SCME_GWOnBoardTester 255;
BA_ "U_P702_MY2021_Tx" SG_ 1447 SCME_GWNMProxy 1;
BA_ "U_U611_U625_MY20_Phev_Tx" SG_ 1447 SCME_GWNMProxy 1;
BA_ "U_CX482_CX483_MY20_Tx" SG_ 1447 SCME_GWNMProxy 1;
BA_ "U_U611_U625_MY20_Hev_Tx" SG_ 1447 SCME_GWNMProxy 1;
BA_ "U_U611_U625_MY20_Gas_Tx" SG_ 1447 SCME_GWNMProxy 1;
BA_ "GenSigStartValue" SG_ 1447 SCME_GWNMProxy 255;
BA_ "ContentDependant" SG_ 1447 SCME_GWNMProxy 1;
BA_ "GenSigStartValueInteger" SG_ 1447 SCME_GWNMProxy 255;
BA_ "U_P702_MY2021_Tx" SG_ 1447 SCME_AutoSarNMReserved4 1;
BA_ "U_U611_U625_MY20_Phev_Tx" SG_ 1447 SCME_AutoSarNMReserved4 1;
BA_ "U_CX482_CX483_MY20_Tx" SG_ 1447 SCME_AutoSarNMReserved4 1;
BA_ "U_U611_U625_MY20_Hev_Tx" SG_ 1447 SCME_AutoSarNMReserved4 1;
BA_ "U_U611_U625_MY20_Gas_Tx" SG_ 1447 SCME_AutoSarNMReserved4 1;
BA_ "GenSigStartValue" SG_ 1447 SCME_AutoSarNMReserved4 255;
BA_ "ContentDependant" SG_ 1447 SCME_AutoSarNMReserved4 1;
BA_ "GenSigStartValueInteger" SG_ 1447 SCME_AutoSarNMReserved4 255;
BA_ "U_P702_MY2021_Tx" SG_ 1447 SCME_AutoSarNMReserved3 1;
BA_ "U_U611_U625_MY20_Phev_Tx" SG_ 1447 SCME_AutoSarNMReserved3 1;
BA_ "U_CX482_CX483_MY20_Tx" SG_ 1447 SCME_AutoSarNMReserved3 1;
BA_ "U_U611_U625_MY20_Hev_Tx" SG_ 1447 SCME_AutoSarNMReserved3 1;
BA_ "U_U611_U625_MY20_Gas_Tx" SG_ 1447 SCME_AutoSarNMReserved3 1;
BA_ "GenSigStartValue" SG_ 1447 SCME_AutoSarNMReserved3 255;
BA_ "ContentDependant" SG_ 1447 SCME_AutoSarNMReserved3 1;
BA_ "GenSigStartValueInteger" SG_ 1447 SCME_AutoSarNMReserved3 255;
BA_ "U_P702_MY2021_Tx" SG_ 1447 SCME_AutoSarNMReserved2 1;
BA_ "U_U611_U625_MY20_Phev_Tx" SG_ 1447 SCME_AutoSarNMReserved2 1;
BA_ "U_CX482_CX483_MY20_Tx" SG_ 1447 SCME_AutoSarNMReserved2 1;
BA_ "U_U611_U625_MY20_Hev_Tx" SG_ 1447 SCME_AutoSarNMReserved2 1;
BA_ "U_U611_U625_MY20_Gas_Tx" SG_ 1447 SCME_AutoSarNMReserved2 1;
BA_ "GenSigStartValue" SG_ 1447 SCME_AutoSarNMReserved2 255;
BA_ "ContentDependant" SG_ 1447 SCME_AutoSarNMReserved2 1;
BA_ "GenSigStartValueInteger" SG_ 1447 SCME_AutoSarNMReserved2 255;
BA_ "U_P702_MY2021_Tx" SG_ 1447 SCME_AutoSarNMReserved1 1;
BA_ "U_U611_U625_MY20_Phev_Tx" SG_ 1447 SCME_AutoSarNMReserved1 1;
BA_ "U_CX482_CX483_MY20_Tx" SG_ 1447 SCME_AutoSarNMReserved1 1;
BA_ "U_U611_U625_MY20_Hev_Tx" SG_ 1447 SCME_AutoSarNMReserved1 1;
BA_ "U_U611_U625_MY20_Gas_Tx" SG_ 1447 SCME_AutoSarNMReserved1 1;
BA_ "GenSigStartValue" SG_ 1447 SCME_AutoSarNMReserved1 255;
BA_ "ContentDependant" SG_ 1447 SCME_AutoSarNMReserved1 1;
BA_ "GenSigStartValueInteger" SG_ 1447 SCME_AutoSarNMReserved1 255;
BA_ "U_P702_MY2021_Tx" SG_ 1447 SCME_AutoSarNMNodeId 1;
BA_ "U_U611_U625_MY20_Phev_Tx" SG_ 1447 SCME_AutoSarNMNodeId 1;
BA_ "U_CX482_CX483_MY20_Tx" SG_ 1447 SCME_AutoSarNMNodeId 1;
BA_ "U_U611_U625_MY20_Hev_Tx" SG_ 1447 SCME_AutoSarNMNodeId 1;
BA_ "U_U611_U625_MY20_Gas_Tx" SG_ 1447 SCME_AutoSarNMNodeId 1;
BA_ "GenSigStartValue" SG_ 1447 SCME_AutoSarNMNodeId 167;
BA_ "ContentDependant" SG_ 1447 SCME_AutoSarNMNodeId 1;
BA_ "GenSigStartValueInteger" SG_ 1447 SCME_AutoSarNMNodeId 167;
BA_ "U_P702_MY2021_Tx" SG_ 1447 SCME_AutoSarNMControl 1;
BA_ "U_U611_U625_MY20_Phev_Tx" SG_ 1447 SCME_AutoSarNMControl 1;
BA_ "U_CX482_CX483_MY20_Tx" SG_ 1447 SCME_AutoSarNMControl 1;
BA_ "U_U611_U625_MY20_Hev_Tx" SG_ 1447 SCME_AutoSarNMControl 1;
BA_ "U_U611_U625_MY20_Gas_Tx" SG_ 1447 SCME_AutoSarNMControl 1;
BA_ "ContentDependant" SG_ 1447 SCME_AutoSarNMControl 1;
BA_ "U_U611_U625_MY20_Phev_Tx" SG_ 1419 DSM_GWOnBoardTester 1;
BA_ "U_CX482_CX483_MY20_Tx" SG_ 1419 DSM_GWOnBoardTester 1;
BA_ "U_U611_U625_MY20_Hev_Tx" SG_ 1419 DSM_GWOnBoardTester 1;
BA_ "U_U611_U625_MY20_Gas_Tx" SG_ 1419 DSM_GWOnBoardTester 1;
BA_ "GenSigStartValue" SG_ 1419 DSM_GWOnBoardTester 255;
BA_ "ContentDependant" SG_ 1419 DSM_GWOnBoardTester 1;
BA_ "GenSigStartValueInteger" SG_ 1419 DSM_GWOnBoardTester 255;
BA_ "U_U611_U625_MY20_Phev_Tx" SG_ 1419 DSM_GWNMProxy 1;
BA_ "U_CX482_CX483_MY20_Tx" SG_ 1419 DSM_GWNMProxy 1;
BA_ "U_U611_U625_MY20_Hev_Tx" SG_ 1419 DSM_GWNMProxy 1;
BA_ "U_U611_U625_MY20_Gas_Tx" SG_ 1419 DSM_GWNMProxy 1;
BA_ "GenSigStartValue" SG_ 1419 DSM_GWNMProxy 255;
BA_ "ContentDependant" SG_ 1419 DSM_GWNMProxy 1;
BA_ "GenSigStartValueInteger" SG_ 1419 DSM_GWNMProxy 255;
BA_ "U_U611_U625_MY20_Phev_Tx" SG_ 1419 DSM_AutoSarNMReserved4 1;
BA_ "U_CX482_CX483_MY20_Tx" SG_ 1419 DSM_AutoSarNMReserved4 1;
BA_ "U_U611_U625_MY20_Hev_Tx" SG_ 1419 DSM_AutoSarNMReserved4 1;
BA_ "U_U611_U625_MY20_Gas_Tx" SG_ 1419 DSM_AutoSarNMReserved4 1;
BA_ "GenSigStartValue" SG_ 1419 DSM_AutoSarNMReserved4 255;
BA_ "ContentDependant" SG_ 1419 DSM_AutoSarNMReserved4 1;
BA_ "GenSigStartValueInteger" SG_ 1419 DSM_AutoSarNMReserved4 255;
BA_ "U_U611_U625_MY20_Phev_Tx" SG_ 1419 DSM_AutoSarNMReserved3 1;
BA_ "U_CX482_CX483_MY20_Tx" SG_ 1419 DSM_AutoSarNMReserved3 1;
BA_ "U_U611_U625_MY20_Hev_Tx" SG_ 1419 DSM_AutoSarNMReserved3 1;
BA_ "U_U611_U625_MY20_Gas_Tx" SG_ 1419 DSM_AutoSarNMReserved3 1;
BA_ "GenSigStartValue" SG_ 1419 DSM_AutoSarNMReserved3 255;
BA_ "ContentDependant" SG_ 1419 DSM_AutoSarNMReserved3 1;
BA_ "GenSigStartValueInteger" SG_ 1419 DSM_AutoSarNMReserved3 255;
BA_ "U_U611_U625_MY20_Phev_Tx" SG_ 1419 DSM_AutoSarNMReserved2 1;
BA_ "U_CX482_CX483_MY20_Tx" SG_ 1419 DSM_AutoSarNMReserved2 1;
BA_ "U_U611_U625_MY20_Hev_Tx" SG_ 1419 DSM_AutoSarNMReserved2 1;
BA_ "U_U611_U625_MY20_Gas_Tx" SG_ 1419 DSM_AutoSarNMReserved2 1;
BA_ "GenSigStartValue" SG_ 1419 DSM_AutoSarNMReserved2 255;
BA_ "ContentDependant" SG_ 1419 DSM_AutoSarNMReserved2 1;
BA_ "GenSigStartValueInteger" SG_ 1419 DSM_AutoSarNMReserved2 255;
BA_ "U_U611_U625_MY20_Phev_Tx" SG_ 1419 DSM_AutoSarNMReserved1 1;
BA_ "U_CX482_CX483_MY20_Tx" SG_ 1419 DSM_AutoSarNMReserved1 1;
BA_ "U_U611_U625_MY20_Hev_Tx" SG_ 1419 DSM_AutoSarNMReserved1 1;
BA_ "U_U611_U625_MY20_Gas_Tx" SG_ 1419 DSM_AutoSarNMReserved1 1;
BA_ "GenSigStartValue" SG_ 1419 DSM_AutoSarNMReserved1 255;
BA_ "ContentDependant" SG_ 1419 DSM_AutoSarNMReserved1 1;
BA_ "GenSigStartValueInteger" SG_ 1419 DSM_AutoSarNMReserved1 255;
BA_ "U_U611_U625_MY20_Phev_Tx" SG_ 1419 DSM_AutoSarNMNodeId 1;
BA_ "U_CX482_CX483_MY20_Tx" SG_ 1419 DSM_AutoSarNMNodeId 1;
BA_ "U_U611_U625_MY20_Hev_Tx" SG_ 1419 DSM_AutoSarNMNodeId 1;
BA_ "U_U611_U625_MY20_Gas_Tx" SG_ 1419 DSM_AutoSarNMNodeId 1;
BA_ "GenSigStartValue" SG_ 1419 DSM_AutoSarNMNodeId 139;
BA_ "ContentDependant" SG_ 1419 DSM_AutoSarNMNodeId 1;
BA_ "GenSigStartValueInteger" SG_ 1419 DSM_AutoSarNMNodeId 139;
BA_ "U_U611_U625_MY20_Phev_Tx" SG_ 1419 DSM_AutoSarNMControl 1;
BA_ "U_CX482_CX483_MY20_Tx" SG_ 1419 DSM_AutoSarNMControl 1;
BA_ "U_U611_U625_MY20_Hev_Tx" SG_ 1419 DSM_AutoSarNMControl 1;
BA_ "U_U611_U625_MY20_Gas_Tx" SG_ 1419 DSM_AutoSarNMControl 1;
BA_ "ContentDependant" SG_ 1419 DSM_AutoSarNMControl 1;
BA_ "GenSigStartValue" SG_ 796 BattULoChrg_URate_RqMx 5;
BA_ "GenSigStartValueInteger" SG_ 796 BattULoChrg_URate_RqMx 5;
BA_ "GenSigStartValue" SG_ 796 BattULoChrg_U_RqMx 34;
BA_ "GenSigStartValueInteger" SG_ 796 BattULoChrg_U_RqMx 34;
BA_ "GenSigSendType" SG_ 796 BattULoState_D_Qlty 3;
BA_ "U_P702_MY2021_Rx" SG_ 796 BattULoState_D_Qlty 1;
BA_ "U_CX727_MY2021_Rx" SG_ 796 BattULoState_D_Qlty 1;
BA_ "U_U611_U625_MY20_Phev_Rx" SG_ 796 BattULoState_D_Qlty 1;
BA_ "U_CX482_CX483_MY20_Rx" SG_ 796 BattULoState_D_Qlty 1;
BA_ "U_U611_U625_MY20_Hev_Rx" SG_ 796 BattULoState_D_Qlty 1;
BA_ "U_U611_U625_MY20_Gas_Rx" SG_ 796 BattULoState_D_Qlty 1;
BA_ "U_C490_MY18_Rx" SG_ 796 BattULoState_D_Qlty 1;
BA_ "U_C519_MY18_5_Gas_Rx" SG_ 796 BattULoState_D_Qlty 1;
BA_ "U_C519_MY18_5_Diesel_Rx" SG_ 796 BattULoState_D_Qlty 1;
BA_ "GenSigSendType" SG_ 796 BSFault 3;
BA_ "U_P702_MY2021_Rx" SG_ 796 BSFault 1;
BA_ "U_CX727_MY2021_Rx" SG_ 796 BSFault 1;
BA_ "U_U611_U625_MY20_Phev_Rx" SG_ 796 BSFault 1;
BA_ "U_CX482_CX483_MY20_Rx" SG_ 796 BSFault 1;
BA_ "U_U611_U625_MY20_Hev_Rx" SG_ 796 BSFault 1;
BA_ "U_U611_U625_MY20_Gas_Rx" SG_ 796 BSFault 1;
BA_ "U_C490_MY18_Rx" SG_ 796 BSFault 1;
BA_ "U_C519_MY18_5_Gas_Rx" SG_ 796 BSFault 1;
BA_ "U_C519_MY18_5_Diesel_Rx" SG_ 796 BSFault 1;
BA_ "GenSigSendType" SG_ 796 BattULo2_Te_Actl 3;
BA_ "U_P702_MY2021_Rx" SG_ 796 BattULo2_Te_Actl 1;
BA_ "U_CX727_MY2021_Rx" SG_ 796 BattULo2_Te_Actl 1;
BA_ "U_CX430_MY2021_Rx" SG_ 796 BattULo2_Te_Actl 1;
BA_ "U_U611_U625_MY20_Phev_Rx" SG_ 796 BattULo2_Te_Actl 1;
BA_ "U_CX482_CX483_MY20_Rx" SG_ 796 BattULo2_Te_Actl 1;
BA_ "U_U611_U625_MY20_Hev_Rx" SG_ 796 BattULo2_Te_Actl 1;
BA_ "U_U611_U625_MY20_Gas_Rx" SG_ 796 BattULo2_Te_Actl 1;
BA_ "U_C490_MY18_Rx" SG_ 796 BattULo2_Te_Actl 1;
BA_ "U_C519_MY18_5_Gas_Rx" SG_ 796 BattULo2_Te_Actl 1;
BA_ "U_C519_MY18_5_Diesel_Rx" SG_ 796 BattULo2_Te_Actl 1;
BA_ "U_B479_MY17_Diesel_Rx" SG_ 796 BattULo2_Te_Actl 1;
BA_ "U_B479_MY17_Gas_Rx" SG_ 796 BattULo2_Te_Actl 1;
BA_ "GenSigStartValue" SG_ 796 BattULo2_Te_Actl 127;
BA_ "GenSigStartValueInteger" SG_ 796 BattULo2_Te_Actl 127;
BA_ "GenSigSendType" SG_ 796 BSBattSOC 3;
BA_ "U_P702_MY2021_Rx" SG_ 796 BSBattSOC 1;
BA_ "U_CX727_MY2021_Rx" SG_ 796 BSBattSOC 1;
BA_ "U_CX430_MY2021_Rx" SG_ 796 BSBattSOC 1;
BA_ "U_U611_U625_MY20_Phev_Rx" SG_ 796 BSBattSOC 1;
BA_ "U_B562_MY18_Diesel_Rx" SG_ 796 BSBattSOC 1;
BA_ "U_CX482_CX483_MY20_Rx" SG_ 796 BSBattSOC 1;
BA_ "U_U611_U625_MY20_Hev_Rx" SG_ 796 BSBattSOC 1;
BA_ "U_U611_U625_MY20_Gas_Rx" SG_ 796 BSBattSOC 1;
BA_ "U_B500_MY18_Diesel_Rx" SG_ 796 BSBattSOC 1;
BA_ "U_B500_MY18_Gas_Rx" SG_ 796 BSBattSOC 1;
BA_ "U_C490_MY18_Rx" SG_ 796 BSBattSOC 1;
BA_ "U_B562_MY18_Gas_Rx" SG_ 796 BSBattSOC 1;
BA_ "U_C519_MY18_5_Gas_Rx" SG_ 796 BSBattSOC 1;
BA_ "U_C519_MY18_5_Diesel_Rx" SG_ 796 BSBattSOC 1;
BA_ "U_B515_MCA_MY17_Gas_Rx" SG_ 796 BSBattSOC 1;
BA_ "U_B515_MCA_MY17_Diesel_Rx" SG_ 796 BSBattSOC 1;
BA_ "U_B479_MY17_Diesel_Rx" SG_ 796 BSBattSOC 1;
BA_ "U_B479_MY17_Gas_Rx" SG_ 796 BSBattSOC 1;
BA_ "GenSigStartValueInteger" SG_ 796 BSBattQDeltaRideAh 12800;
BA_ "U_P702_MY2021_Tx" SG_ 1364 TRM_Network_Mgmt 1;
BA_ "U_CX430_MY2021_Tx" SG_ 1364 TRM_Network_Mgmt 1;
BA_ "U_U611_U625_MY20_Phev_Tx" SG_ 1364 TRM_Network_Mgmt 1;
BA_ "U_CX482_CX483_MY20_Tx" SG_ 1364 TRM_Network_Mgmt 1;
BA_ "U_U611_U625_MY20_Gas_Tx" SG_ 1364 TRM_Network_Mgmt 1;
BA_ "U_CX430_MY2021_Rx" SG_ 1364 TRM_Network_Mgmt 1;
BA_ "U_U611_U625_MY20_Phev_Rx" SG_ 1364 TRM_Network_Mgmt 1;
BA_ "U_CX482_CX483_MY20_Rx" SG_ 1364 TRM_Network_Mgmt 1;
BA_ "U_U611_U625_MY20_Hev_Rx" SG_ 1364 TRM_Network_Mgmt 1;
BA_ "U_U611_U625_MY20_Gas_Rx" SG_ 1364 TRM_Network_Mgmt 1;
BA_ "GenSigSendType" SG_ 1364 TRM_Network_Mgmt 3;
BA_ "U_CX727_MY2021_Tx" SG_ 1383 RSM_Network_Mgmt 1;
BA_ "U_CX430_MY2021_Tx" SG_ 1383 RSM_Network_Mgmt 1;
BA_ "U_CX482_CX483_MY20_Tx" SG_ 1383 RSM_Network_Mgmt 1;
BA_ "U_B515_MCA_MY17_Gas_Tx" SG_ 1383 RSM_Network_Mgmt 1;
BA_ "U_B515_MCA_MY17_Diesel_Tx" SG_ 1383 RSM_Network_Mgmt 1;
BA_ "GenSigSendType" SG_ 1383 RSM_Network_Mgmt 3;
BA_ "GenSigSendType" SG_ 883 PmCabn10Mnte_Conc_Actl 3;
BA_ "U_P702_MY2021_Tx" SG_ 883 PmCabn10Mnte_Conc_Actl 1;
BA_ "U_CX727_MY2021_Tx" SG_ 883 PmCabn10Mnte_Conc_Actl 1;
BA_ "U_U611_U625_MY20_Phev_Tx" SG_ 883 PmCabn10Mnte_Conc_Actl 1;
BA_ "U_CX482_CX483_MY20_Tx" SG_ 883 PmCabn10Mnte_Conc_Actl 1;
BA_ "U_U611_U625_MY20_Hev_Tx" SG_ 883 PmCabn10Mnte_Conc_Actl 1;
BA_ "U_U611_U625_MY20_Gas_Tx" SG_ 883 PmCabn10Mnte_Conc_Actl 1;
BA_ "GenSigStartValue" SG_ 883 PmCabn10Mnte_Conc_Actl 510;
BA_ "GenSigStartValueInteger" SG_ 883 PmCabn10Mnte_Conc_Actl 510;
BA_ "GenSigSendType" SG_ 883 PmCabn08Mnte_Conc_Actl 3;
BA_ "U_P702_MY2021_Tx" SG_ 883 PmCabn08Mnte_Conc_Actl 1;
BA_ "U_CX727_MY2021_Tx" SG_ 883 PmCabn08Mnte_Conc_Actl 1;
BA_ "U_U611_U625_MY20_Phev_Tx" SG_ 883 PmCabn08Mnte_Conc_Actl 1;
BA_ "U_CX482_CX483_MY20_Tx" SG_ 883 PmCabn08Mnte_Conc_Actl 1;
BA_ "U_U611_U625_MY20_Hev_Tx" SG_ 883 PmCabn08Mnte_Conc_Actl 1;
BA_ "U_U611_U625_MY20_Gas_Tx" SG_ 883 PmCabn08Mnte_Conc_Actl 1;
BA_ "GenSigStartValue" SG_ 883 PmCabn08Mnte_Conc_Actl 510;
BA_ "GenSigStartValueInteger" SG_ 883 PmCabn08Mnte_Conc_Actl 510;
BA_ "GenSigSendType" SG_ 883 PmCabn06Mnte_Conc_Actl 3;
BA_ "U_P702_MY2021_Tx" SG_ 883 PmCabn06Mnte_Conc_Actl 1;
BA_ "U_CX727_MY2021_Tx" SG_ 883 PmCabn06Mnte_Conc_Actl 1;
BA_ "U_U611_U625_MY20_Phev_Tx" SG_ 883 PmCabn06Mnte_Conc_Actl 1;
BA_ "U_CX482_CX483_MY20_Tx" SG_ 883 PmCabn06Mnte_Conc_Actl 1;
BA_ "U_U611_U625_MY20_Hev_Tx" SG_ 883 PmCabn06Mnte_Conc_Actl 1;
BA_ "U_U611_U625_MY20_Gas_Tx" SG_ 883 PmCabn06Mnte_Conc_Actl 1;
BA_ "GenSigStartValue" SG_ 883 PmCabn06Mnte_Conc_Actl 510;
BA_ "GenSigStartValueInteger" SG_ 883 PmCabn06Mnte_Conc_Actl 510;
BA_ "GenSigSendType" SG_ 883 PmCabn04Mnte_Conc_Actl 3;
BA_ "U_P702_MY2021_Tx" SG_ 883 PmCabn04Mnte_Conc_Actl 1;
BA_ "U_CX727_MY2021_Tx" SG_ 883 PmCabn04Mnte_Conc_Actl 1;
BA_ "U_U611_U625_MY20_Phev_Tx" SG_ 883 PmCabn04Mnte_Conc_Actl 1;
BA_ "U_CX482_CX483_MY20_Tx" SG_ 883 PmCabn04Mnte_Conc_Actl 1;
BA_ "U_U611_U625_MY20_Hev_Tx" SG_ 883 PmCabn04Mnte_Conc_Actl 1;
BA_ "U_U611_U625_MY20_Gas_Tx" SG_ 883 PmCabn04Mnte_Conc_Actl 1;
BA_ "GenSigStartValue" SG_ 883 PmCabn04Mnte_Conc_Actl 510;
BA_ "GenSigStartValueInteger" SG_ 883 PmCabn04Mnte_Conc_Actl 510;
BA_ "GenSigSendType" SG_ 883 PmCabn02Mnte_Conc_Actl 3;
BA_ "U_P702_MY2021_Tx" SG_ 883 PmCabn02Mnte_Conc_Actl 1;
BA_ "U_CX727_MY2021_Tx" SG_ 883 PmCabn02Mnte_Conc_Actl 1;
BA_ "U_U611_U625_MY20_Phev_Tx" SG_ 883 PmCabn02Mnte_Conc_Actl 1;
BA_ "U_CX482_CX483_MY20_Tx" SG_ 883 PmCabn02Mnte_Conc_Actl 1;
BA_ "U_U611_U625_MY20_Hev_Tx" SG_ 883 PmCabn02Mnte_Conc_Actl 1;
BA_ "U_U611_U625_MY20_Gas_Tx" SG_ 883 PmCabn02Mnte_Conc_Actl 1;
BA_ "GenSigStartValue" SG_ 883 PmCabn02Mnte_Conc_Actl 510;
BA_ "GenSigStartValueInteger" SG_ 883 PmCabn02Mnte_Conc_Actl 510;
BA_ "GenSigSendType" SG_ 884 UltraFreshCabn_D_Stat 3;
BA_ "GenSigSendType" SG_ 884 PmSnsCabn_D_Stat 3;
BA_ "U_P702_MY2021_Tx" SG_ 884 PmSnsCabn_D_Stat 1;
BA_ "U_CX727_MY2021_Tx" SG_ 884 PmSnsCabn_D_Stat 1;
BA_ "U_U611_U625_MY20_Phev_Tx" SG_ 884 PmSnsCabn_D_Stat 1;
BA_ "U_CX482_CX483_MY20_Tx" SG_ 884 PmSnsCabn_D_Stat 1;
BA_ "U_U611_U625_MY20_Hev_Tx" SG_ 884 PmSnsCabn_D_Stat 1;
BA_ "U_U611_U625_MY20_Gas_Tx" SG_ 884 PmSnsCabn_D_Stat 1;
BA_ "GenSigStartValue" SG_ 884 PmSnsCabn_D_Stat 5;
BA_ "GenSigStartValueInteger" SG_ 884 PmSnsCabn_D_Stat 5;
BA_ "GenSigSendType" SG_ 884 PmCabn_Conc_Actl 3;
BA_ "U_P702_MY2021_Tx" SG_ 884 PmCabn_Conc_Actl 1;
BA_ "U_CX727_MY2021_Tx" SG_ 884 PmCabn_Conc_Actl 1;
BA_ "U_U611_U625_MY20_Phev_Tx" SG_ 884 PmCabn_Conc_Actl 1;
BA_ "U_CX482_CX483_MY20_Tx" SG_ 884 PmCabn_Conc_Actl 1;
BA_ "U_U611_U625_MY20_Hev_Tx" SG_ 884 PmCabn_Conc_Actl 1;
BA_ "U_U611_U625_MY20_Gas_Tx" SG_ 884 PmCabn_Conc_Actl 1;
BA_ "GenSigStartValue" SG_ 884 PmCabn_Conc_Actl 510;
BA_ "GenSigStartValueInteger" SG_ 884 PmCabn_Conc_Actl 510;
BA_ "GenSigSendType" SG_ 884 PmCabn20Mnte_Conc_Actl 3;
BA_ "U_P702_MY2021_Tx" SG_ 884 PmCabn20Mnte_Conc_Actl 1;
BA_ "U_CX727_MY2021_Tx" SG_ 884 PmCabn20Mnte_Conc_Actl 1;
BA_ "U_U611_U625_MY20_Phev_Tx" SG_ 884 PmCabn20Mnte_Conc_Actl 1;
BA_ "U_CX482_CX483_MY20_Tx" SG_ 884 PmCabn20Mnte_Conc_Actl 1;
BA_ "U_U611_U625_MY20_Hev_Tx" SG_ 884 PmCabn20Mnte_Conc_Actl 1;
BA_ "U_U611_U625_MY20_Gas_Tx" SG_ 884 PmCabn20Mnte_Conc_Actl 1;
BA_ "GenSigStartValue" SG_ 884 PmCabn20Mnte_Conc_Actl 510;
BA_ "GenSigStartValueInteger" SG_ 884 PmCabn20Mnte_Conc_Actl 510;
BA_ "GenSigSendType" SG_ 884 PmCabn18Mnte_Conc_Actl 3;
BA_ "U_P702_MY2021_Tx" SG_ 884 PmCabn18Mnte_Conc_Actl 1;
BA_ "U_CX727_MY2021_Tx" SG_ 884 PmCabn18Mnte_Conc_Actl 1;
BA_ "U_U611_U625_MY20_Phev_Tx" SG_ 884 PmCabn18Mnte_Conc_Actl 1;
BA_ "U_CX482_CX483_MY20_Tx" SG_ 884 PmCabn18Mnte_Conc_Actl 1;
BA_ "U_U611_U625_MY20_Hev_Tx" SG_ 884 PmCabn18Mnte_Conc_Actl 1;
BA_ "U_U611_U625_MY20_Gas_Tx" SG_ 884 PmCabn18Mnte_Conc_Actl 1;
BA_ "GenSigStartValue" SG_ 884 PmCabn18Mnte_Conc_Actl 510;
BA_ "GenSigStartValueInteger" SG_ 884 PmCabn18Mnte_Conc_Actl 510;
BA_ "GenSigSendType" SG_ 884 PmCabn16Mnte_Conc_Actl 3;
BA_ "U_P702_MY2021_Tx" SG_ 884 PmCabn16Mnte_Conc_Actl 1;
BA_ "U_CX727_MY2021_Tx" SG_ 884 PmCabn16Mnte_Conc_Actl 1;
BA_ "U_U611_U625_MY20_Phev_Tx" SG_ 884 PmCabn16Mnte_Conc_Actl 1;
BA_ "U_CX482_CX483_MY20_Tx" SG_ 884 PmCabn16Mnte_Conc_Actl 1;
BA_ "U_U611_U625_MY20_Hev_Tx" SG_ 884 PmCabn16Mnte_Conc_Actl 1;
BA_ "U_U611_U625_MY20_Gas_Tx" SG_ 884 PmCabn16Mnte_Conc_Actl 1;
BA_ "GenSigStartValue" SG_ 884 PmCabn16Mnte_Conc_Actl 510;
BA_ "GenSigStartValueInteger" SG_ 884 PmCabn16Mnte_Conc_Actl 510;
BA_ "GenSigSendType" SG_ 884 PmCabn14Mnte_Conc_Actl 3;
BA_ "U_P702_MY2021_Tx" SG_ 884 PmCabn14Mnte_Conc_Actl 1;
BA_ "U_CX727_MY2021_Tx" SG_ 884 PmCabn14Mnte_Conc_Actl 1;
BA_ "U_U611_U625_MY20_Phev_Tx" SG_ 884 PmCabn14Mnte_Conc_Actl 1;
BA_ "U_CX482_CX483_MY20_Tx" SG_ 884 PmCabn14Mnte_Conc_Actl 1;
BA_ "U_U611_U625_MY20_Hev_Tx" SG_ 884 PmCabn14Mnte_Conc_Actl 1;
BA_ "U_U611_U625_MY20_Gas_Tx" SG_ 884 PmCabn14Mnte_Conc_Actl 1;
BA_ "GenSigStartValue" SG_ 884 PmCabn14Mnte_Conc_Actl 510;
BA_ "GenSigStartValueInteger" SG_ 884 PmCabn14Mnte_Conc_Actl 510;
BA_ "GenSigSendType" SG_ 884 PmCabn12Mnte_Conc_Actl 3;
BA_ "U_P702_MY2021_Tx" SG_ 884 PmCabn12Mnte_Conc_Actl 1;
BA_ "U_CX727_MY2021_Tx" SG_ 884 PmCabn12Mnte_Conc_Actl 1;
BA_ "U_U611_U625_MY20_Phev_Tx" SG_ 884 PmCabn12Mnte_Conc_Actl 1;
BA_ "U_CX482_CX483_MY20_Tx" SG_ 884 PmCabn12Mnte_Conc_Actl 1;
BA_ "U_U611_U625_MY20_Hev_Tx" SG_ 884 PmCabn12Mnte_Conc_Actl 1;
BA_ "U_U611_U625_MY20_Gas_Tx" SG_ 884 PmCabn12Mnte_Conc_Actl 1;
BA_ "GenSigStartValue" SG_ 884 PmCabn12Mnte_Conc_Actl 510;
BA_ "GenSigStartValueInteger" SG_ 884 PmCabn12Mnte_Conc_Actl 510;
BA_ "GenSigSendType" SG_ 1438 GWM_GWOnBoardTester 3;
BA_ "U_P702_MY2021_Rx" SG_ 1438 GWM_GWOnBoardTester 1;
BA_ "U_CX727_MY2021_Rx" SG_ 1438 GWM_GWOnBoardTester 1;
BA_ "U_CX430_MY2021_Rx" SG_ 1438 GWM_GWOnBoardTester 1;
BA_ "U_U611_U625_MY20_Phev_Rx" SG_ 1438 GWM_GWOnBoardTester 1;
BA_ "U_B562_MY18_Diesel_Rx" SG_ 1438 GWM_GWOnBoardTester 1;
BA_ "U_CX482_CX483_MY20_Rx" SG_ 1438 GWM_GWOnBoardTester 1;
BA_ "U_U611_U625_MY20_Hev_Rx" SG_ 1438 GWM_GWOnBoardTester 1;
BA_ "U_U611_U625_MY20_Gas_Rx" SG_ 1438 GWM_GWOnBoardTester 1;
BA_ "U_C490_MY18_Rx" SG_ 1438 GWM_GWOnBoardTester 1;
BA_ "U_B562_MY18_Gas_Rx" SG_ 1438 GWM_GWOnBoardTester 1;
BA_ "U_C519_MY18_5_Gas_Rx" SG_ 1438 GWM_GWOnBoardTester 1;
BA_ "U_C519_MY18_5_Diesel_Rx" SG_ 1438 GWM_GWOnBoardTester 1;
BA_ "GenSigStartValue" SG_ 1438 GWM_GWOnBoardTester 255;
BA_ "ContentDependant" SG_ 1438 GWM_GWOnBoardTester 1;
BA_ "GenSigStartValueInteger" SG_ 1438 GWM_GWOnBoardTester 255;
BA_ "GenSigSendType" SG_ 1438 GWM_GWNMProxy 3;
BA_ "U_P702_MY2021_Rx" SG_ 1438 GWM_GWNMProxy 1;
BA_ "U_CX727_MY2021_Rx" SG_ 1438 GWM_GWNMProxy 1;
BA_ "U_CX430_MY2021_Rx" SG_ 1438 GWM_GWNMProxy 1;
BA_ "U_U611_U625_MY20_Phev_Rx" SG_ 1438 GWM_GWNMProxy 1;
BA_ "U_B562_MY18_Diesel_Rx" SG_ 1438 GWM_GWNMProxy 1;
BA_ "U_CX482_CX483_MY20_Rx" SG_ 1438 GWM_GWNMProxy 1;
BA_ "U_U611_U625_MY20_Hev_Rx" SG_ 1438 GWM_GWNMProxy 1;
BA_ "U_U611_U625_MY20_Gas_Rx" SG_ 1438 GWM_GWNMProxy 1;
BA_ "U_C490_MY18_Rx" SG_ 1438 GWM_GWNMProxy 1;
BA_ "U_B562_MY18_Gas_Rx" SG_ 1438 GWM_GWNMProxy 1;
BA_ "U_C519_MY18_5_Gas_Rx" SG_ 1438 GWM_GWNMProxy 1;
BA_ "U_C519_MY18_5_Diesel_Rx" SG_ 1438 GWM_GWNMProxy 1;
BA_ "GenSigStartValue" SG_ 1438 GWM_GWNMProxy 255;
BA_ "ContentDependant" SG_ 1438 GWM_GWNMProxy 1;
BA_ "GenSigStartValueInteger" SG_ 1438 GWM_GWNMProxy 255;
BA_ "GenSigSendType" SG_ 1438 GWM_AutoSarNMReserved4 3;
BA_ "U_P702_MY2021_Rx" SG_ 1438 GWM_AutoSarNMReserved4 1;
BA_ "U_CX727_MY2021_Rx" SG_ 1438 GWM_AutoSarNMReserved4 1;
BA_ "U_CX430_MY2021_Rx" SG_ 1438 GWM_AutoSarNMReserved4 1;
BA_ "U_U611_U625_MY20_Phev_Rx" SG_ 1438 GWM_AutoSarNMReserved4 1;
BA_ "U_B562_MY18_Diesel_Rx" SG_ 1438 GWM_AutoSarNMReserved4 1;
BA_ "U_CX482_CX483_MY20_Rx" SG_ 1438 GWM_AutoSarNMReserved4 1;
BA_ "U_U611_U625_MY20_Hev_Rx" SG_ 1438 GWM_AutoSarNMReserved4 1;
BA_ "U_U611_U625_MY20_Gas_Rx" SG_ 1438 GWM_AutoSarNMReserved4 1;
BA_ "U_C490_MY18_Rx" SG_ 1438 GWM_AutoSarNMReserved4 1;
BA_ "U_B562_MY18_Gas_Rx" SG_ 1438 GWM_AutoSarNMReserved4 1;
BA_ "U_C519_MY18_5_Gas_Rx" SG_ 1438 GWM_AutoSarNMReserved4 1;
BA_ "U_C519_MY18_5_Diesel_Rx" SG_ 1438 GWM_AutoSarNMReserved4 1;
BA_ "GenSigStartValue" SG_ 1438 GWM_AutoSarNMReserved4 255;
BA_ "ContentDependant" SG_ 1438 GWM_AutoSarNMReserved4 1;
BA_ "GenSigStartValueInteger" SG_ 1438 GWM_AutoSarNMReserved4 255;
BA_ "GenSigSendType" SG_ 1438 GWM_AutoSarNMReserved3 3;
BA_ "U_P702_MY2021_Rx" SG_ 1438 GWM_AutoSarNMReserved3 1;
BA_ "U_CX727_MY2021_Rx" SG_ 1438 GWM_AutoSarNMReserved3 1;
BA_ "U_CX430_MY2021_Rx" SG_ 1438 GWM_AutoSarNMReserved3 1;
BA_ "U_U611_U625_MY20_Phev_Rx" SG_ 1438 GWM_AutoSarNMReserved3 1;
BA_ "U_B562_MY18_Diesel_Rx" SG_ 1438 GWM_AutoSarNMReserved3 1;
BA_ "U_CX482_CX483_MY20_Rx" SG_ 1438 GWM_AutoSarNMReserved3 1;
BA_ "U_U611_U625_MY20_Hev_Rx" SG_ 1438 GWM_AutoSarNMReserved3 1;
BA_ "U_U611_U625_MY20_Gas_Rx" SG_ 1438 GWM_AutoSarNMReserved3 1;
BA_ "U_C490_MY18_Rx" SG_ 1438 GWM_AutoSarNMReserved3 1;
BA_ "U_B562_MY18_Gas_Rx" SG_ 1438 GWM_AutoSarNMReserved3 1;
BA_ "U_C519_MY18_5_Gas_Rx" SG_ 1438 GWM_AutoSarNMReserved3 1;
BA_ "U_C519_MY18_5_Diesel_Rx" SG_ 1438 GWM_AutoSarNMReserved3 1;
BA_ "GenSigStartValue" SG_ 1438 GWM_AutoSarNMReserved3 255;
BA_ "ContentDependant" SG_ 1438 GWM_AutoSarNMReserved3 1;
BA_ "GenSigStartValueInteger" SG_ 1438 GWM_AutoSarNMReserved3 255;
BA_ "GenSigSendType" SG_ 1438 GWM_AutoSarNMReserved2 3;
BA_ "U_P702_MY2021_Rx" SG_ 1438 GWM_AutoSarNMReserved2 1;
BA_ "U_CX727_MY2021_Rx" SG_ 1438 GWM_AutoSarNMReserved2 1;
BA_ "U_CX430_MY2021_Rx" SG_ 1438 GWM_AutoSarNMReserved2 1;
BA_ "U_U611_U625_MY20_Phev_Rx" SG_ 1438 GWM_AutoSarNMReserved2 1;
BA_ "U_B562_MY18_Diesel_Rx" SG_ 1438 GWM_AutoSarNMReserved2 1;
BA_ "U_CX482_CX483_MY20_Rx" SG_ 1438 GWM_AutoSarNMReserved2 1;
BA_ "U_U611_U625_MY20_Hev_Rx" SG_ 1438 GWM_AutoSarNMReserved2 1;
BA_ "U_U611_U625_MY20_Gas_Rx" SG_ 1438 GWM_AutoSarNMReserved2 1;
BA_ "U_C490_MY18_Rx" SG_ 1438 GWM_AutoSarNMReserved2 1;
BA_ "U_B562_MY18_Gas_Rx" SG_ 1438 GWM_AutoSarNMReserved2 1;
BA_ "U_C519_MY18_5_Gas_Rx" SG_ 1438 GWM_AutoSarNMReserved2 1;
BA_ "U_C519_MY18_5_Diesel_Rx" SG_ 1438 GWM_AutoSarNMReserved2 1;
BA_ "GenSigStartValue" SG_ 1438 GWM_AutoSarNMReserved2 255;
BA_ "ContentDependant" SG_ 1438 GWM_AutoSarNMReserved2 1;
BA_ "GenSigStartValueInteger" SG_ 1438 GWM_AutoSarNMReserved2 255;
BA_ "GenSigSendType" SG_ 1438 GWM_AutoSarNMReserved1 3;
BA_ "U_P702_MY2021_Rx" SG_ 1438 GWM_AutoSarNMReserved1 1;
BA_ "U_CX727_MY2021_Rx" SG_ 1438 GWM_AutoSarNMReserved1 1;
BA_ "U_CX430_MY2021_Rx" SG_ 1438 GWM_AutoSarNMReserved1 1;
BA_ "U_U611_U625_MY20_Phev_Rx" SG_ 1438 GWM_AutoSarNMReserved1 1;
BA_ "U_B562_MY18_Diesel_Rx" SG_ 1438 GWM_AutoSarNMReserved1 1;
BA_ "U_CX482_CX483_MY20_Rx" SG_ 1438 GWM_AutoSarNMReserved1 1;
BA_ "U_U611_U625_MY20_Hev_Rx" SG_ 1438 GWM_AutoSarNMReserved1 1;
BA_ "U_U611_U625_MY20_Gas_Rx" SG_ 1438 GWM_AutoSarNMReserved1 1;
BA_ "U_C490_MY18_Rx" SG_ 1438 GWM_AutoSarNMReserved1 1;
BA_ "U_B562_MY18_Gas_Rx" SG_ 1438 GWM_AutoSarNMReserved1 1;
BA_ "U_C519_MY18_5_Gas_Rx" SG_ 1438 GWM_AutoSarNMReserved1 1;
BA_ "U_C519_MY18_5_Diesel_Rx" SG_ 1438 GWM_AutoSarNMReserved1 1;
BA_ "GenSigStartValue" SG_ 1438 GWM_AutoSarNMReserved1 255;
BA_ "ContentDependant" SG_ 1438 GWM_AutoSarNMReserved1 1;
BA_ "GenSigStartValueInteger" SG_ 1438 GWM_AutoSarNMReserved1 255;
BA_ "GenSigSendType" SG_ 1438 GWM_AutoSarNMNodeId 3;
BA_ "U_P702_MY2021_Rx" SG_ 1438 GWM_AutoSarNMNodeId 1;
BA_ "U_CX727_MY2021_Rx" SG_ 1438 GWM_AutoSarNMNodeId 1;
BA_ "U_CX430_MY2021_Rx" SG_ 1438 GWM_AutoSarNMNodeId 1;
BA_ "U_U611_U625_MY20_Phev_Rx" SG_ 1438 GWM_AutoSarNMNodeId 1;
BA_ "U_B562_MY18_Diesel_Rx" SG_ 1438 GWM_AutoSarNMNodeId 1;
BA_ "U_CX482_CX483_MY20_Rx" SG_ 1438 GWM_AutoSarNMNodeId 1;
BA_ "U_U611_U625_MY20_Hev_Rx" SG_ 1438 GWM_AutoSarNMNodeId 1;
BA_ "U_U611_U625_MY20_Gas_Rx" SG_ 1438 GWM_AutoSarNMNodeId 1;
BA_ "U_C490_MY18_Rx" SG_ 1438 GWM_AutoSarNMNodeId 1;
BA_ "U_B562_MY18_Gas_Rx" SG_ 1438 GWM_AutoSarNMNodeId 1;
BA_ "U_C519_MY18_5_Gas_Rx" SG_ 1438 GWM_AutoSarNMNodeId 1;
BA_ "U_C519_MY18_5_Diesel_Rx" SG_ 1438 GWM_AutoSarNMNodeId 1;
BA_ "GenSigStartValue" SG_ 1438 GWM_AutoSarNMNodeId 158;
BA_ "ContentDependant" SG_ 1438 GWM_AutoSarNMNodeId 1;
BA_ "GenSigStartValueInteger" SG_ 1438 GWM_AutoSarNMNodeId 158;
BA_ "GenSigSendType" SG_ 1438 GWM_AutoSarNMControl 3;
BA_ "U_P702_MY2021_Rx" SG_ 1438 GWM_AutoSarNMControl 1;
BA_ "U_CX727_MY2021_Rx" SG_ 1438 GWM_AutoSarNMControl 1;
BA_ "U_CX430_MY2021_Rx" SG_ 1438 GWM_AutoSarNMControl 1;
BA_ "U_U611_U625_MY20_Phev_Rx" SG_ 1438 GWM_AutoSarNMControl 1;
BA_ "U_B562_MY18_Diesel_Rx" SG_ 1438 GWM_AutoSarNMControl 1;
BA_ "U_CX482_CX483_MY20_Rx" SG_ 1438 GWM_AutoSarNMControl 1;
BA_ "U_U611_U625_MY20_Hev_Rx" SG_ 1438 GWM_AutoSarNMControl 1;
BA_ "U_U611_U625_MY20_Gas_Rx" SG_ 1438 GWM_AutoSarNMControl 1;
BA_ "U_C490_MY18_Rx" SG_ 1438 GWM_AutoSarNMControl 1;
BA_ "U_B562_MY18_Gas_Rx" SG_ 1438 GWM_AutoSarNMControl 1;
BA_ "U_C519_MY18_5_Gas_Rx" SG_ 1438 GWM_AutoSarNMControl 1;
BA_ "U_C519_MY18_5_Diesel_Rx" SG_ 1438 GWM_AutoSarNMControl 1;
BA_ "ContentDependant" SG_ 1438 GWM_AutoSarNMControl 1;
BA_ "U_CX482_CX483_MY20_Tx" SG_ 841 FohStrtDateDay_No_Stat 1;
BA_ "U_C519_MY18_5_Gas_Tx" SG_ 841 FohStrtDateDay_No_Stat 1;
BA_ "U_C519_MY18_5_Diesel_Tx" SG_ 841 FohStrtDateDay_No_Stat 1;
BA_ "U_CX482_CX483_MY20_Tx" SG_ 841 FohStrtDateYr_No_Stat 1;
BA_ "U_C519_MY18_5_Gas_Tx" SG_ 841 FohStrtDateYr_No_Stat 1;
BA_ "U_C519_MY18_5_Diesel_Tx" SG_ 841 FohStrtDateYr_No_Stat 1;
BA_ "U_CX482_CX483_MY20_Tx" SG_ 841 FohAddHeater_D_Stat 1;
BA_ "U_C519_MY18_5_Gas_Tx" SG_ 841 FohAddHeater_D_Stat 1;
BA_ "U_C519_MY18_5_Diesel_Tx" SG_ 841 FohAddHeater_D_Stat 1;
BA_ "GenSigSendType" SG_ 841 FohAddHeater_D_Stat 3;
BA_ "U_P702_MY2021_Rx" SG_ 1075 ACU_RadioSeekMode2_St 1;
BA_ "U_CX430_MY2021_Rx" SG_ 1075 ACU_RadioSeekMode2_St 1;
BA_ "U_CX727_MY2021_Rx" SG_ 1075 ACU_RadioSeekMode2_St 1;
BA_ "U_U611_U625_MY20_Phev_Rx" SG_ 1075 ACU_RadioSeekMode2_St 1;
BA_ "U_CX482_CX483_MY20_Rx" SG_ 1075 ACU_RadioSeekMode2_St 1;
BA_ "U_U611_U625_MY20_Hev_Rx" SG_ 1075 ACU_RadioSeekMode2_St 1;
BA_ "U_U611_U625_MY20_Gas_Rx" SG_ 1075 ACU_RadioSeekMode2_St 1;
BA_ "U_C519_MY18_5_Gas_Rx" SG_ 1075 ACU_RadioSeekMode2_St 1;
BA_ "U_C519_MY18_5_Diesel_Rx" SG_ 1075 ACU_RadioSeekMode2_St 1;
BA_ "U_P702_MY2021_Rx" SG_ 1075 ACU_CurrTUBand_St 1;
BA_ "U_CX430_MY2021_Rx" SG_ 1075 ACU_CurrTUBand_St 1;
BA_ "U_CX727_MY2021_Rx" SG_ 1075 ACU_CurrTUBand_St 1;
BA_ "U_U611_U625_MY20_Phev_Rx" SG_ 1075 ACU_CurrTUBand_St 1;
BA_ "U_CX482_CX483_MY20_Rx" SG_ 1075 ACU_CurrTUBand_St 1;
BA_ "U_U611_U625_MY20_Hev_Rx" SG_ 1075 ACU_CurrTUBand_St 1;
BA_ "U_U611_U625_MY20_Gas_Rx" SG_ 1075 ACU_CurrTUBand_St 1;
BA_ "U_C519_MY18_5_Gas_Rx" SG_ 1075 ACU_CurrTUBand_St 1;
BA_ "U_C519_MY18_5_Diesel_Rx" SG_ 1075 ACU_CurrTUBand_St 1;
BA_ "U_P702_MY2021_Rx" SG_ 1075 ACU_CurrentFreq_St 1;
BA_ "U_CX430_MY2021_Rx" SG_ 1075 ACU_CurrentFreq_St 1;
BA_ "U_CX727_MY2021_Rx" SG_ 1075 ACU_CurrentFreq_St 1;
BA_ "U_U611_U625_MY20_Phev_Rx" SG_ 1075 ACU_CurrentFreq_St 1;
BA_ "U_CX482_CX483_MY20_Rx" SG_ 1075 ACU_CurrentFreq_St 1;
BA_ "U_U611_U625_MY20_Hev_Rx" SG_ 1075 ACU_CurrentFreq_St 1;
BA_ "U_U611_U625_MY20_Gas_Rx" SG_ 1075 ACU_CurrentFreq_St 1;
BA_ "U_C519_MY18_5_Gas_Rx" SG_ 1075 ACU_CurrentFreq_St 1;
BA_ "U_C519_MY18_5_Diesel_Rx" SG_ 1075 ACU_CurrentFreq_St 1;
BA_ "U_P702_MY2021_Rx" SG_ 1075 ACU_RadioSeekMode2_St_UB 1;
BA_ "U_CX430_MY2021_Rx" SG_ 1075 ACU_RadioSeekMode2_St_UB 1;
BA_ "U_C519_MY18_5_Gas_Rx" SG_ 1075 ACU_RadioSeekMode2_St_UB 1;
BA_ "U_C519_MY18_5_Diesel_Rx" SG_ 1075 ACU_RadioSeekMode2_St_UB 1;
BA_ "U_CX727_MY2021_Rx" SG_ 1075 ACU_RadioSeekMode2_St_UB 1;
BA_ "U_U611_U625_MY20_Phev_Rx" SG_ 1075 ACU_RadioSeekMode2_St_UB 1;
BA_ "U_CX482_CX483_MY20_Rx" SG_ 1075 ACU_RadioSeekMode2_St_UB 1;
BA_ "U_U611_U625_MY20_Hev_Rx" SG_ 1075 ACU_RadioSeekMode2_St_UB 1;
BA_ "U_U611_U625_MY20_Gas_Rx" SG_ 1075 ACU_RadioSeekMode2_St_UB 1;
BA_ "U_P702_MY2021_Rx" SG_ 1075 ACU_CurrTUBand_St_UB 1;
BA_ "U_CX430_MY2021_Rx" SG_ 1075 ACU_CurrTUBand_St_UB 1;
BA_ "U_C519_MY18_5_Gas_Rx" SG_ 1075 ACU_CurrTUBand_St_UB 1;
BA_ "U_C519_MY18_5_Diesel_Rx" SG_ 1075 ACU_CurrTUBand_St_UB 1;
BA_ "U_CX727_MY2021_Rx" SG_ 1075 ACU_CurrTUBand_St_UB 1;
BA_ "U_U611_U625_MY20_Phev_Rx" SG_ 1075 ACU_CurrTUBand_St_UB 1;
BA_ "U_CX482_CX483_MY20_Rx" SG_ 1075 ACU_CurrTUBand_St_UB 1;
BA_ "U_U611_U625_MY20_Hev_Rx" SG_ 1075 ACU_CurrTUBand_St_UB 1;
BA_ "U_U611_U625_MY20_Gas_Rx" SG_ 1075 ACU_CurrTUBand_St_UB 1;
BA_ "U_P702_MY2021_Rx" SG_ 1075 ACU_CurrentFreq_St_UB 1;
BA_ "U_CX430_MY2021_Rx" SG_ 1075 ACU_CurrentFreq_St_UB 1;
BA_ "U_C519_MY18_5_Gas_Rx" SG_ 1075 ACU_CurrentFreq_St_UB 1;
BA_ "U_C519_MY18_5_Diesel_Rx" SG_ 1075 ACU_CurrentFreq_St_UB 1;
BA_ "U_CX727_MY2021_Rx" SG_ 1075 ACU_CurrentFreq_St_UB 1;
BA_ "U_U611_U625_MY20_Phev_Rx" SG_ 1075 ACU_CurrentFreq_St_UB 1;
BA_ "U_CX482_CX483_MY20_Rx" SG_ 1075 ACU_CurrentFreq_St_UB 1;
BA_ "U_U611_U625_MY20_Hev_Rx" SG_ 1075 ACU_CurrentFreq_St_UB 1;
BA_ "U_U611_U625_MY20_Gas_Rx" SG_ 1075 ACU_CurrentFreq_St_UB 1;
BA_ "U_CX727_MY2021_Rx" SG_ 1075 CtaBrk_D_Stat_UB 1;
BA_ "U_U611_U625_MY20_Phev_Rx" SG_ 1075 CtaBrk_D_Stat_UB 1;
BA_ "U_CX482_CX483_MY20_Rx" SG_ 1075 CtaBrk_D_Stat_UB 1;
BA_ "U_U611_U625_MY20_Hev_Rx" SG_ 1075 CtaBrk_D_Stat_UB 1;
BA_ "U_U611_U625_MY20_Gas_Rx" SG_ 1075 CtaBrk_D_Stat_UB 1;
BA_ "U_C519_MY18_5_Gas_Rx" SG_ 1075 CtaBrk_D_Stat_UB 1;
BA_ "U_C519_MY18_5_Diesel_Rx" SG_ 1075 CtaBrk_D_Stat_UB 1;
BA_ "U_CX727_MY2021_Rx" SG_ 1075 CtaBrk_D_Stat 1;
BA_ "U_U611_U625_MY20_Phev_Rx" SG_ 1075 CtaBrk_D_Stat 1;
BA_ "U_CX482_CX483_MY20_Rx" SG_ 1075 CtaBrk_D_Stat 1;
BA_ "U_U611_U625_MY20_Hev_Rx" SG_ 1075 CtaBrk_D_Stat 1;
BA_ "U_U611_U625_MY20_Gas_Rx" SG_ 1075 CtaBrk_D_Stat 1;
BA_ "U_C519_MY18_5_Gas_Rx" SG_ 1075 CtaBrk_D_Stat 1;
BA_ "U_C519_MY18_5_Diesel_Rx" SG_ 1075 CtaBrk_D_Stat 1;
BA_ "GenSigSendType" SG_ 1075 CtaBrk_D_Stat 3;
BA_ "GenSigSendType" SG_ 1075 SelDrvMdePt_D_Rq_UB 3;
BA_ "U_CX727_MY2021_Rx" SG_ 1075 SelDrvMdePt_D_Rq_UB 1;
BA_ "U_CX430_MY2021_Rx" SG_ 1075 SelDrvMdePt_D_Rq_UB 1;
BA_ "U_U611_U625_MY20_Phev_Rx" SG_ 1075 SelDrvMdePt_D_Rq_UB 1;
BA_ "U_CX482_CX483_MY20_Rx" SG_ 1075 SelDrvMdePt_D_Rq_UB 1;
BA_ "U_U611_U625_MY20_Hev_Rx" SG_ 1075 SelDrvMdePt_D_Rq_UB 1;
BA_ "U_U611_U625_MY20_Gas_Rx" SG_ 1075 SelDrvMdePt_D_Rq_UB 1;
BA_ "U_B500_MY18_Diesel_Rx" SG_ 1075 SelDrvMdePt_D_Rq_UB 1;
BA_ "U_B500_MY18_Gas_Rx" SG_ 1075 SelDrvMdePt_D_Rq_UB 1;
BA_ "U_C519_MY18_5_Gas_Rx" SG_ 1075 SelDrvMdePt_D_Rq_UB 1;
BA_ "U_C519_MY18_5_Diesel_Rx" SG_ 1075 SelDrvMdePt_D_Rq_UB 1;
BA_ "U_B515_MCA_MY17_Gas_Rx" SG_ 1075 SelDrvMdePt_D_Rq_UB 1;
BA_ "U_B515_MCA_MY17_Diesel_Rx" SG_ 1075 SelDrvMdePt_D_Rq_UB 1;
BA_ "U_B479_MY17_Diesel_Rx" SG_ 1075 SelDrvMdePt_D_Rq_UB 1;
BA_ "U_B479_MY17_Gas_Rx" SG_ 1075 SelDrvMdePt_D_Rq_UB 1;
BA_ "U_CX727_MY2021_Rx" SG_ 1075 SelDrvMdePt_D_Rq 1;
BA_ "U_CX430_MY2021_Rx" SG_ 1075 SelDrvMdePt_D_Rq 1;
BA_ "U_U611_U625_MY20_Phev_Rx" SG_ 1075 SelDrvMdePt_D_Rq 1;
BA_ "U_CX482_CX483_MY20_Rx" SG_ 1075 SelDrvMdePt_D_Rq 1;
BA_ "U_U611_U625_MY20_Hev_Rx" SG_ 1075 SelDrvMdePt_D_Rq 1;
BA_ "U_U611_U625_MY20_Gas_Rx" SG_ 1075 SelDrvMdePt_D_Rq 1;
BA_ "U_B500_MY18_Diesel_Rx" SG_ 1075 SelDrvMdePt_D_Rq 1;
BA_ "U_B500_MY18_Gas_Rx" SG_ 1075 SelDrvMdePt_D_Rq 1;
BA_ "U_C519_MY18_5_Gas_Rx" SG_ 1075 SelDrvMdePt_D_Rq 1;
BA_ "U_C519_MY18_5_Diesel_Rx" SG_ 1075 SelDrvMdePt_D_Rq 1;
BA_ "U_B515_MCA_MY17_Gas_Rx" SG_ 1075 SelDrvMdePt_D_Rq 1;
BA_ "U_B515_MCA_MY17_Diesel_Rx" SG_ 1075 SelDrvMdePt_D_Rq 1;
BA_ "U_B479_MY17_Diesel_Rx" SG_ 1075 SelDrvMdePt_D_Rq 1;
BA_ "U_B479_MY17_Gas_Rx" SG_ 1075 SelDrvMdePt_D_Rq 1;
BA_ "GenSigSendType" SG_ 1075 SelDrvMdePt_D_Rq 3;
BA_ "GenSigSendType" SG_ 1075 PrkAidSnsRrCrnr_D_Stat 3;
BA_ "CrossOver_InfoCAN" SG_ 1075 PrkAidSnsRrCrnr_D_Stat 1;
BA_ "GenSigSendType" SG_ 1075 PrkAidSnsRrCntr_D_Stat 3;
BA_ "CrossOver_InfoCAN" SG_ 1075 PrkAidSnsRrCntr_D_Stat 1;
BA_ "GenSigSendType" SG_ 1075 PrkAidSnsRlCrnr_D_Stat 3;
BA_ "CrossOver_InfoCAN" SG_ 1075 PrkAidSnsRlCrnr_D_Stat 1;
BA_ "GenSigSendType" SG_ 1075 PrkAidSnsRlCntr_D_Stat 3;
BA_ "CrossOver_InfoCAN" SG_ 1075 PrkAidSnsRlCntr_D_Stat 1;
BA_ "GenSigSendType" SG_ 1075 BttOn_B_Rq 3;
BA_ "GenSigStartValue" SG_ 1075 Btt_L_Actl 126;
BA_ "GenSigStartValueInteger" SG_ 1075 Btt_L_Actl 126;
BA_ "GenSigSendType" SG_ 1075 ArmrestStwdRear_B_Stat 3;
BA_ "GenSigStartValue" SG_ 1075 ArmrestStwdRear_B_Stat 1;
BA_ "GenSigStartValueInteger" SG_ 1075 ArmrestStwdRear_B_Stat 1;
BA_ "CrossOver_InfoCAN" SG_ 1075 ArmrestStwdRear_B_Stat 1;
BA_ "U_U611_U625_MY20_Phev_Tx" SG_ 1963 TesterPhysicalResSCMB_PSM 1;
BA_ "U_CX482_CX483_MY20_Tx" SG_ 1963 TesterPhysicalResSCMB_PSM 1;
BA_ "U_U611_U625_MY20_Hev_Tx" SG_ 1963 TesterPhysicalResSCMB_PSM 1;
BA_ "U_U611_U625_MY20_Gas_Tx" SG_ 1963 TesterPhysicalResSCMB_PSM 1;
BA_ "GenSigSendType" SG_ 1963 TesterPhysicalResSCMB_PSM 3;
BA_ "U_U611_U625_MY20_Phev_Rx" SG_ 1955 TesterPhysicalReqSCMB_PSM 1;
BA_ "U_CX482_CX483_MY20_Rx" SG_ 1955 TesterPhysicalReqSCMB_PSM 1;
BA_ "U_U611_U625_MY20_Hev_Rx" SG_ 1955 TesterPhysicalReqSCMB_PSM 1;
BA_ "U_U611_U625_MY20_Gas_Rx" SG_ 1955 TesterPhysicalReqSCMB_PSM 1;
BA_ "GenSigSendType" SG_ 1955 TesterPhysicalReqSCMB_PSM 3;
BA_ "U_P702_MY2021_Tx" SG_ 1285 PDM_Network_Mgmt 1;
BA_ "U_CX482_CX483_MY20_Tx" SG_ 1285 PDM_Network_Mgmt 1;
BA_ "U_C490_MY18_Tx" SG_ 1285 PDM_Network_Mgmt 1;
BA_ "U_B479_MY17_Diesel_Tx" SG_ 1285 PDM_Network_Mgmt 1;
BA_ "U_B479_MY17_Gas_Tx" SG_ 1285 PDM_Network_Mgmt 1;
BA_ "U_P702_MY2021_Rx" SG_ 1285 PDM_Network_Mgmt 1;
BA_ "U_CX482_CX483_MY20_Rx" SG_ 1285 PDM_Network_Mgmt 1;
BA_ "U_C490_MY18_Rx" SG_ 1285 PDM_Network_Mgmt 1;
BA_ "GenSigSendType" SG_ 1285 PDM_Network_Mgmt 3;
BA_ "GenSigSendType" SG_ 977 CnvtTopMsgTxt_D_Rq 3;
BA_ "WakeupSignal" SG_ 977 CnvtTopMsgTxt_D_Rq 1;
BA_ "U_P702_MY2021_Rx" SG_ 1045 VehVActlBrk_No_Cs 1;
BA_ "U_CX430_MY2021_Rx" SG_ 1045 VehVActlBrk_No_Cs 1;
BA_ "U_U611_U625_MY20_Phev_Rx" SG_ 1045 VehVActlBrk_No_Cs 1;
BA_ "U_CX482_CX483_MY20_Rx" SG_ 1045 VehVActlBrk_No_Cs 1;
BA_ "U_U611_U625_MY20_Gas_Rx" SG_ 1045 VehVActlBrk_No_Cs 1;
BA_ "U_C519_MY18_5_Gas_Rx" SG_ 1045 VehVActlBrk_No_Cs 1;
BA_ "U_C519_MY18_5_Diesel_Rx" SG_ 1045 VehVActlBrk_No_Cs 1;
BA_ "U_B515_MCA_MY17_Gas_Rx" SG_ 1045 VehVActlBrk_No_Cs 1;
BA_ "U_B515_MCA_MY17_Diesel_Rx" SG_ 1045 VehVActlBrk_No_Cs 1;
BA_ "U_B479_MY17_Diesel_Rx" SG_ 1045 VehVActlBrk_No_Cs 1;
BA_ "U_B479_MY17_Gas_Rx" SG_ 1045 VehVActlBrk_No_Cs 1;
BA_ "MetaData" SG_ 1045 VehVActlBrk_No_Cs 1;
BA_ "CrossOver_InfoCAN" SG_ 1045 VehVActlBrk_No_Cs 1;
BA_ "U_P702_MY2021_Rx" SG_ 1045 Veh_V_ActlBrk 1;
BA_ "U_CX430_MY2021_Rx" SG_ 1045 Veh_V_ActlBrk 1;
BA_ "U_U611_U625_MY20_Phev_Rx" SG_ 1045 Veh_V_ActlBrk 1;
BA_ "U_CX482_CX483_MY20_Rx" SG_ 1045 Veh_V_ActlBrk 1;
BA_ "U_U611_U625_MY20_Gas_Rx" SG_ 1045 Veh_V_ActlBrk 1;
BA_ "U_C519_MY18_5_Gas_Rx" SG_ 1045 Veh_V_ActlBrk 1;
BA_ "U_C519_MY18_5_Diesel_Rx" SG_ 1045 Veh_V_ActlBrk 1;
BA_ "U_B515_MCA_MY17_Gas_Rx" SG_ 1045 Veh_V_ActlBrk 1;
BA_ "U_B515_MCA_MY17_Diesel_Rx" SG_ 1045 Veh_V_ActlBrk 1;
BA_ "U_B479_MY17_Diesel_Rx" SG_ 1045 Veh_V_ActlBrk 1;
BA_ "U_B479_MY17_Gas_Rx" SG_ 1045 Veh_V_ActlBrk 1;
BA_ "CrossOver_InfoCAN" SG_ 1045 Veh_V_ActlBrk 1;
BA_ "U_P702_MY2021_Rx" SG_ 1045 VehVActlBrk_No_Cnt 1;
BA_ "U_CX430_MY2021_Rx" SG_ 1045 VehVActlBrk_No_Cnt 1;
BA_ "U_U611_U625_MY20_Phev_Rx" SG_ 1045 VehVActlBrk_No_Cnt 1;
BA_ "U_CX482_CX483_MY20_Rx" SG_ 1045 VehVActlBrk_No_Cnt 1;
BA_ "U_U611_U625_MY20_Gas_Rx" SG_ 1045 VehVActlBrk_No_Cnt 1;
BA_ "U_C519_MY18_5_Gas_Rx" SG_ 1045 VehVActlBrk_No_Cnt 1;
BA_ "U_C519_MY18_5_Diesel_Rx" SG_ 1045 VehVActlBrk_No_Cnt 1;
BA_ "U_B515_MCA_MY17_Gas_Rx" SG_ 1045 VehVActlBrk_No_Cnt 1;
BA_ "U_B515_MCA_MY17_Diesel_Rx" SG_ 1045 VehVActlBrk_No_Cnt 1;
BA_ "U_B479_MY17_Diesel_Rx" SG_ 1045 VehVActlBrk_No_Cnt 1;
BA_ "U_B479_MY17_Gas_Rx" SG_ 1045 VehVActlBrk_No_Cnt 1;
BA_ "MetaData" SG_ 1045 VehVActlBrk_No_Cnt 1;
BA_ "CrossOver_InfoCAN" SG_ 1045 VehVActlBrk_No_Cnt 1;
BA_ "U_P702_MY2021_Rx" SG_ 1045 VehVActlBrk_D_Qf 1;
BA_ "U_CX430_MY2021_Rx" SG_ 1045 VehVActlBrk_D_Qf 1;
BA_ "U_U611_U625_MY20_Phev_Rx" SG_ 1045 VehVActlBrk_D_Qf 1;
BA_ "U_CX482_CX483_MY20_Rx" SG_ 1045 VehVActlBrk_D_Qf 1;
BA_ "U_U611_U625_MY20_Gas_Rx" SG_ 1045 VehVActlBrk_D_Qf 1;
BA_ "U_C519_MY18_5_Gas_Rx" SG_ 1045 VehVActlBrk_D_Qf 1;
BA_ "U_C519_MY18_5_Diesel_Rx" SG_ 1045 VehVActlBrk_D_Qf 1;
BA_ "U_B515_MCA_MY17_Gas_Rx" SG_ 1045 VehVActlBrk_D_Qf 1;
BA_ "U_B515_MCA_MY17_Diesel_Rx" SG_ 1045 VehVActlBrk_D_Qf 1;
BA_ "U_B479_MY17_Diesel_Rx" SG_ 1045 VehVActlBrk_D_Qf 1;
BA_ "U_B479_MY17_Gas_Rx" SG_ 1045 VehVActlBrk_D_Qf 1;
BA_ "MetaData" SG_ 1045 VehVActlBrk_D_Qf 1;
BA_ "CrossOver_InfoCAN" SG_ 1045 VehVActlBrk_D_Qf 1;
BA_ "U_P702_MY2021_Tx" SG_ 1413 PDM_GWOnBoardTester 1;
BA_ "U_CX430_MY2021_Tx" SG_ 1413 PDM_GWOnBoardTester 1;
BA_ "U_U611_U625_MY20_Phev_Tx" SG_ 1413 PDM_GWOnBoardTester 1;
BA_ "U_CX482_CX483_MY20_Tx" SG_ 1413 PDM_GWOnBoardTester 1;
BA_ "U_U611_U625_MY20_Hev_Tx" SG_ 1413 PDM_GWOnBoardTester 1;
BA_ "U_U611_U625_MY20_Gas_Tx" SG_ 1413 PDM_GWOnBoardTester 1;
BA_ "U_C519_MY18_5_Gas_Tx" SG_ 1413 PDM_GWOnBoardTester 1;
BA_ "U_C519_MY18_5_Diesel_Tx" SG_ 1413 PDM_GWOnBoardTester 1;
BA_ "GenSigStartValue" SG_ 1413 PDM_GWOnBoardTester 255;
BA_ "ContentDependant" SG_ 1413 PDM_GWOnBoardTester 1;
BA_ "GenSigStartValueInteger" SG_ 1413 PDM_GWOnBoardTester 255;
BA_ "U_P702_MY2021_Tx" SG_ 1413 PDM_GWNMProxy 1;
BA_ "U_CX430_MY2021_Tx" SG_ 1413 PDM_GWNMProxy 1;
BA_ "U_U611_U625_MY20_Phev_Tx" SG_ 1413 PDM_GWNMProxy 1;
BA_ "U_CX482_CX483_MY20_Tx" SG_ 1413 PDM_GWNMProxy 1;
BA_ "U_U611_U625_MY20_Hev_Tx" SG_ 1413 PDM_GWNMProxy 1;
BA_ "U_U611_U625_MY20_Gas_Tx" SG_ 1413 PDM_GWNMProxy 1;
BA_ "U_C519_MY18_5_Gas_Tx" SG_ 1413 PDM_GWNMProxy 1;
BA_ "U_C519_MY18_5_Diesel_Tx" SG_ 1413 PDM_GWNMProxy 1;
BA_ "GenSigStartValue" SG_ 1413 PDM_GWNMProxy 255;
BA_ "ContentDependant" SG_ 1413 PDM_GWNMProxy 1;
BA_ "GenSigStartValueInteger" SG_ 1413 PDM_GWNMProxy 255;
BA_ "U_P702_MY2021_Tx" SG_ 1413 PDM_AutoSarNMReserved4 1;
BA_ "U_CX430_MY2021_Tx" SG_ 1413 PDM_AutoSarNMReserved4 1;
BA_ "U_U611_U625_MY20_Phev_Tx" SG_ 1413 PDM_AutoSarNMReserved4 1;
BA_ "U_CX482_CX483_MY20_Tx" SG_ 1413 PDM_AutoSarNMReserved4 1;
BA_ "U_U611_U625_MY20_Hev_Tx" SG_ 1413 PDM_AutoSarNMReserved4 1;
BA_ "U_U611_U625_MY20_Gas_Tx" SG_ 1413 PDM_AutoSarNMReserved4 1;
BA_ "U_C519_MY18_5_Gas_Tx" SG_ 1413 PDM_AutoSarNMReserved4 1;
BA_ "U_C519_MY18_5_Diesel_Tx" SG_ 1413 PDM_AutoSarNMReserved4 1;
BA_ "GenSigStartValue" SG_ 1413 PDM_AutoSarNMReserved4 255;
BA_ "ContentDependant" SG_ 1413 PDM_AutoSarNMReserved4 1;
BA_ "GenSigStartValueInteger" SG_ 1413 PDM_AutoSarNMReserved4 255;
BA_ "U_P702_MY2021_Tx" SG_ 1413 PDM_AutoSarNMReserved3 1;
BA_ "U_CX430_MY2021_Tx" SG_ 1413 PDM_AutoSarNMReserved3 1;
BA_ "U_U611_U625_MY20_Phev_Tx" SG_ 1413 PDM_AutoSarNMReserved3 1;
BA_ "U_CX482_CX483_MY20_Tx" SG_ 1413 PDM_AutoSarNMReserved3 1;
BA_ "U_U611_U625_MY20_Hev_Tx" SG_ 1413 PDM_AutoSarNMReserved3 1;
BA_ "U_U611_U625_MY20_Gas_Tx" SG_ 1413 PDM_AutoSarNMReserved3 1;
BA_ "U_C519_MY18_5_Gas_Tx" SG_ 1413 PDM_AutoSarNMReserved3 1;
BA_ "U_C519_MY18_5_Diesel_Tx" SG_ 1413 PDM_AutoSarNMReserved3 1;
BA_ "GenSigStartValue" SG_ 1413 PDM_AutoSarNMReserved3 255;
BA_ "ContentDependant" SG_ 1413 PDM_AutoSarNMReserved3 1;
BA_ "GenSigStartValueInteger" SG_ 1413 PDM_AutoSarNMReserved3 255;
BA_ "U_P702_MY2021_Tx" SG_ 1413 PDM_AutoSarNMReserved2 1;
BA_ "U_CX430_MY2021_Tx" SG_ 1413 PDM_AutoSarNMReserved2 1;
BA_ "U_U611_U625_MY20_Phev_Tx" SG_ 1413 PDM_AutoSarNMReserved2 1;
BA_ "U_CX482_CX483_MY20_Tx" SG_ 1413 PDM_AutoSarNMReserved2 1;
BA_ "U_U611_U625_MY20_Hev_Tx" SG_ 1413 PDM_AutoSarNMReserved2 1;
BA_ "U_U611_U625_MY20_Gas_Tx" SG_ 1413 PDM_AutoSarNMReserved2 1;
BA_ "U_C519_MY18_5_Gas_Tx" SG_ 1413 PDM_AutoSarNMReserved2 1;
BA_ "U_C519_MY18_5_Diesel_Tx" SG_ 1413 PDM_AutoSarNMReserved2 1;
BA_ "GenSigStartValue" SG_ 1413 PDM_AutoSarNMReserved2 255;
BA_ "ContentDependant" SG_ 1413 PDM_AutoSarNMReserved2 1;
BA_ "GenSigStartValueInteger" SG_ 1413 PDM_AutoSarNMReserved2 255;
BA_ "U_P702_MY2021_Tx" SG_ 1413 PDM_AutoSarNMReserved1 1;
BA_ "U_CX430_MY2021_Tx" SG_ 1413 PDM_AutoSarNMReserved1 1;
BA_ "U_U611_U625_MY20_Phev_Tx" SG_ 1413 PDM_AutoSarNMReserved1 1;
BA_ "U_CX482_CX483_MY20_Tx" SG_ 1413 PDM_AutoSarNMReserved1 1;
BA_ "U_U611_U625_MY20_Hev_Tx" SG_ 1413 PDM_AutoSarNMReserved1 1;
BA_ "U_U611_U625_MY20_Gas_Tx" SG_ 1413 PDM_AutoSarNMReserved1 1;
BA_ "U_C519_MY18_5_Gas_Tx" SG_ 1413 PDM_AutoSarNMReserved1 1;
BA_ "U_C519_MY18_5_Diesel_Tx" SG_ 1413 PDM_AutoSarNMReserved1 1;
BA_ "GenSigStartValue" SG_ 1413 PDM_AutoSarNMReserved1 255;
BA_ "ContentDependant" SG_ 1413 PDM_AutoSarNMReserved1 1;
BA_ "GenSigStartValueInteger" SG_ 1413 PDM_AutoSarNMReserved1 255;
BA_ "U_P702_MY2021_Tx" SG_ 1413 PDM_AutoSarNMNodeId 1;
BA_ "U_CX430_MY2021_Tx" SG_ 1413 PDM_AutoSarNMNodeId 1;
BA_ "U_U611_U625_MY20_Phev_Tx" SG_ 1413 PDM_AutoSarNMNodeId 1;
BA_ "U_CX482_CX483_MY20_Tx" SG_ 1413 PDM_AutoSarNMNodeId 1;
BA_ "U_U611_U625_MY20_Hev_Tx" SG_ 1413 PDM_AutoSarNMNodeId 1;
BA_ "U_U611_U625_MY20_Gas_Tx" SG_ 1413 PDM_AutoSarNMNodeId 1;
BA_ "U_C519_MY18_5_Gas_Tx" SG_ 1413 PDM_AutoSarNMNodeId 1;
BA_ "U_C519_MY18_5_Diesel_Tx" SG_ 1413 PDM_AutoSarNMNodeId 1;
BA_ "GenSigStartValue" SG_ 1413 PDM_AutoSarNMNodeId 133;
BA_ "ContentDependant" SG_ 1413 PDM_AutoSarNMNodeId 1;
BA_ "GenSigStartValueInteger" SG_ 1413 PDM_AutoSarNMNodeId 133;
BA_ "U_P702_MY2021_Tx" SG_ 1413 PDM_AutoSarNMControl 1;
BA_ "U_CX430_MY2021_Tx" SG_ 1413 PDM_AutoSarNMControl 1;
BA_ "U_U611_U625_MY20_Phev_Tx" SG_ 1413 PDM_AutoSarNMControl 1;
BA_ "U_CX482_CX483_MY20_Tx" SG_ 1413 PDM_AutoSarNMControl 1;
BA_ "U_U611_U625_MY20_Hev_Tx" SG_ 1413 PDM_AutoSarNMControl 1;
BA_ "U_U611_U625_MY20_Gas_Tx" SG_ 1413 PDM_AutoSarNMControl 1;
BA_ "U_C519_MY18_5_Gas_Tx" SG_ 1413 PDM_AutoSarNMControl 1;
BA_ "U_C519_MY18_5_Diesel_Tx" SG_ 1413 PDM_AutoSarNMControl 1;
BA_ "ContentDependant" SG_ 1413 PDM_AutoSarNMControl 1;
BA_ "U_P702_MY2021_Tx" SG_ 1412 DDM_GWOnBoardTester 1;
BA_ "U_CX727_MY2021_Tx" SG_ 1412 DDM_GWOnBoardTester 1;
BA_ "U_CX430_MY2021_Tx" SG_ 1412 DDM_GWOnBoardTester 1;
BA_ "U_U611_U625_MY20_Phev_Tx" SG_ 1412 DDM_GWOnBoardTester 1;
BA_ "U_CX482_CX483_MY20_Tx" SG_ 1412 DDM_GWOnBoardTester 1;
BA_ "U_U611_U625_MY20_Hev_Tx" SG_ 1412 DDM_GWOnBoardTester 1;
BA_ "U_U611_U625_MY20_Gas_Tx" SG_ 1412 DDM_GWOnBoardTester 1;
BA_ "U_C519_MY18_5_Gas_Tx" SG_ 1412 DDM_GWOnBoardTester 1;
BA_ "U_C519_MY18_5_Diesel_Tx" SG_ 1412 DDM_GWOnBoardTester 1;
BA_ "GenSigStartValue" SG_ 1412 DDM_GWOnBoardTester 255;
BA_ "ContentDependant" SG_ 1412 DDM_GWOnBoardTester 1;
BA_ "GenSigStartValueInteger" SG_ 1412 DDM_GWOnBoardTester 255;
BA_ "U_P702_MY2021_Tx" SG_ 1412 DDM_GWNMProxy 1;
BA_ "U_CX727_MY2021_Tx" SG_ 1412 DDM_GWNMProxy 1;
BA_ "U_CX430_MY2021_Tx" SG_ 1412 DDM_GWNMProxy 1;
BA_ "U_U611_U625_MY20_Phev_Tx" SG_ 1412 DDM_GWNMProxy 1;
BA_ "U_CX482_CX483_MY20_Tx" SG_ 1412 DDM_GWNMProxy 1;
BA_ "U_U611_U625_MY20_Hev_Tx" SG_ 1412 DDM_GWNMProxy 1;
BA_ "U_U611_U625_MY20_Gas_Tx" SG_ 1412 DDM_GWNMProxy 1;
BA_ "U_C519_MY18_5_Gas_Tx" SG_ 1412 DDM_GWNMProxy 1;
BA_ "U_C519_MY18_5_Diesel_Tx" SG_ 1412 DDM_GWNMProxy 1;
BA_ "GenSigStartValue" SG_ 1412 DDM_GWNMProxy 255;
BA_ "ContentDependant" SG_ 1412 DDM_GWNMProxy 1;
BA_ "GenSigStartValueInteger" SG_ 1412 DDM_GWNMProxy 255;
BA_ "U_P702_MY2021_Tx" SG_ 1412 DDM_AutoSarNMReserved4 1;
BA_ "U_CX727_MY2021_Tx" SG_ 1412 DDM_AutoSarNMReserved4 1;
BA_ "U_CX430_MY2021_Tx" SG_ 1412 DDM_AutoSarNMReserved4 1;
BA_ "U_U611_U625_MY20_Phev_Tx" SG_ 1412 DDM_AutoSarNMReserved4 1;
BA_ "U_CX482_CX483_MY20_Tx" SG_ 1412 DDM_AutoSarNMReserved4 1;
BA_ "U_U611_U625_MY20_Hev_Tx" SG_ 1412 DDM_AutoSarNMReserved4 1;
BA_ "U_U611_U625_MY20_Gas_Tx" SG_ 1412 DDM_AutoSarNMReserved4 1;
BA_ "U_C519_MY18_5_Gas_Tx" SG_ 1412 DDM_AutoSarNMReserved4 1;
BA_ "U_C519_MY18_5_Diesel_Tx" SG_ 1412 DDM_AutoSarNMReserved4 1;
BA_ "GenSigStartValue" SG_ 1412 DDM_AutoSarNMReserved4 255;
BA_ "ContentDependant" SG_ 1412 DDM_AutoSarNMReserved4 1;
BA_ "GenSigStartValueInteger" SG_ 1412 DDM_AutoSarNMReserved4 255;
BA_ "U_P702_MY2021_Tx" SG_ 1412 DDM_AutoSarNMReserved3 1;
BA_ "U_CX727_MY2021_Tx" SG_ 1412 DDM_AutoSarNMReserved3 1;
BA_ "U_CX430_MY2021_Tx" SG_ 1412 DDM_AutoSarNMReserved3 1;
BA_ "U_U611_U625_MY20_Phev_Tx" SG_ 1412 DDM_AutoSarNMReserved3 1;
BA_ "U_CX482_CX483_MY20_Tx" SG_ 1412 DDM_AutoSarNMReserved3 1;
BA_ "U_U611_U625_MY20_Hev_Tx" SG_ 1412 DDM_AutoSarNMReserved3 1;
BA_ "U_U611_U625_MY20_Gas_Tx" SG_ 1412 DDM_AutoSarNMReserved3 1;
BA_ "U_C519_MY18_5_Gas_Tx" SG_ 1412 DDM_AutoSarNMReserved3 1;
BA_ "U_C519_MY18_5_Diesel_Tx" SG_ 1412 DDM_AutoSarNMReserved3 1;
BA_ "GenSigStartValue" SG_ 1412 DDM_AutoSarNMReserved3 255;
BA_ "ContentDependant" SG_ 1412 DDM_AutoSarNMReserved3 1;
BA_ "GenSigStartValueInteger" SG_ 1412 DDM_AutoSarNMReserved3 255;
BA_ "U_P702_MY2021_Tx" SG_ 1412 DDM_AutoSarNMReserved2 1;
BA_ "U_CX727_MY2021_Tx" SG_ 1412 DDM_AutoSarNMReserved2 1;
BA_ "U_CX430_MY2021_Tx" SG_ 1412 DDM_AutoSarNMReserved2 1;
BA_ "U_U611_U625_MY20_Phev_Tx" SG_ 1412 DDM_AutoSarNMReserved2 1;
BA_ "U_CX482_CX483_MY20_Tx" SG_ 1412 DDM_AutoSarNMReserved2 1;
BA_ "U_U611_U625_MY20_Hev_Tx" SG_ 1412 DDM_AutoSarNMReserved2 1;
BA_ "U_U611_U625_MY20_Gas_Tx" SG_ 1412 DDM_AutoSarNMReserved2 1;
BA_ "U_C519_MY18_5_Gas_Tx" SG_ 1412 DDM_AutoSarNMReserved2 1;
BA_ "U_C519_MY18_5_Diesel_Tx" SG_ 1412 DDM_AutoSarNMReserved2 1;
BA_ "GenSigStartValue" SG_ 1412 DDM_AutoSarNMReserved2 255;
BA_ "ContentDependant" SG_ 1412 DDM_AutoSarNMReserved2 1;
BA_ "GenSigStartValueInteger" SG_ 1412 DDM_AutoSarNMReserved2 255;
BA_ "U_P702_MY2021_Tx" SG_ 1412 DDM_AutoSarNMReserved1 1;
BA_ "U_CX727_MY2021_Tx" SG_ 1412 DDM_AutoSarNMReserved1 1;
BA_ "U_CX430_MY2021_Tx" SG_ 1412 DDM_AutoSarNMReserved1 1;
BA_ "U_U611_U625_MY20_Phev_Tx" SG_ 1412 DDM_AutoSarNMReserved1 1;
BA_ "U_CX482_CX483_MY20_Tx" SG_ 1412 DDM_AutoSarNMReserved1 1;
BA_ "U_U611_U625_MY20_Hev_Tx" SG_ 1412 DDM_AutoSarNMReserved1 1;
BA_ "U_U611_U625_MY20_Gas_Tx" SG_ 1412 DDM_AutoSarNMReserved1 1;
BA_ "U_C519_MY18_5_Gas_Tx" SG_ 1412 DDM_AutoSarNMReserved1 1;
BA_ "U_C519_MY18_5_Diesel_Tx" SG_ 1412 DDM_AutoSarNMReserved1 1;
BA_ "GenSigStartValue" SG_ 1412 DDM_AutoSarNMReserved1 255;
BA_ "ContentDependant" SG_ 1412 DDM_AutoSarNMReserved1 1;
BA_ "GenSigStartValueInteger" SG_ 1412 DDM_AutoSarNMReserved1 255;
BA_ "U_P702_MY2021_Tx" SG_ 1412 DDM_AutoSarNMNodeId 1;
BA_ "U_CX727_MY2021_Tx" SG_ 1412 DDM_AutoSarNMNodeId 1;
BA_ "U_CX430_MY2021_Tx" SG_ 1412 DDM_AutoSarNMNodeId 1;
BA_ "U_U611_U625_MY20_Phev_Tx" SG_ 1412 DDM_AutoSarNMNodeId 1;
BA_ "U_CX482_CX483_MY20_Tx" SG_ 1412 DDM_AutoSarNMNodeId 1;
BA_ "U_U611_U625_MY20_Hev_Tx" SG_ 1412 DDM_AutoSarNMNodeId 1;
BA_ "U_U611_U625_MY20_Gas_Tx" SG_ 1412 DDM_AutoSarNMNodeId 1;
BA_ "U_C519_MY18_5_Gas_Tx" SG_ 1412 DDM_AutoSarNMNodeId 1;
BA_ "U_C519_MY18_5_Diesel_Tx" SG_ 1412 DDM_AutoSarNMNodeId 1;
BA_ "GenSigStartValue" SG_ 1412 DDM_AutoSarNMNodeId 132;
BA_ "ContentDependant" SG_ 1412 DDM_AutoSarNMNodeId 1;
BA_ "GenSigStartValueInteger" SG_ 1412 DDM_AutoSarNMNodeId 132;
BA_ "U_P702_MY2021_Tx" SG_ 1412 DDM_AutoSarNMControl 1;
BA_ "U_CX727_MY2021_Tx" SG_ 1412 DDM_AutoSarNMControl 1;
BA_ "U_CX430_MY2021_Tx" SG_ 1412 DDM_AutoSarNMControl 1;
BA_ "U_U611_U625_MY20_Phev_Tx" SG_ 1412 DDM_AutoSarNMControl 1;
BA_ "U_CX482_CX483_MY20_Tx" SG_ 1412 DDM_AutoSarNMControl 1;
BA_ "U_U611_U625_MY20_Hev_Tx" SG_ 1412 DDM_AutoSarNMControl 1;
BA_ "U_U611_U625_MY20_Gas_Tx" SG_ 1412 DDM_AutoSarNMControl 1;
BA_ "U_C519_MY18_5_Gas_Tx" SG_ 1412 DDM_AutoSarNMControl 1;
BA_ "U_C519_MY18_5_Diesel_Tx" SG_ 1412 DDM_AutoSarNMControl 1;
BA_ "ContentDependant" SG_ 1412 DDM_AutoSarNMControl 1;
BA_ "GenSigSendType" SG_ 1079 ApaMde_D_Stat 3;
BA_ "CrossOver_InfoCAN" SG_ 1079 ApaMde_D_Stat 1;
BA_ "GenSigSendType" SG_ 1079 GenericSwtch3_No_Actl 3;
BA_ "GenSigSendType" SG_ 1079 GenericSwtch2_No_Actl 3;
BA_ "ContentDependant" SG_ 1079 GenericSwtch2_No_Actl 1;
BA_ "GenSigSendType" SG_ 1079 GenericSwtch1_No_Actl 3;
BA_ "GenSigSendType" SG_ 1079 RbaSys_D_Stat 3;
BA_ "GenSigStartValue" SG_ 1079 RbaSys_D_Stat 2;
BA_ "GenSigStartValueInteger" SG_ 1079 RbaSys_D_Stat 2;
BA_ "GenSigSendType" SG_ 1079 HybMdeStat_D_Dsply_UB 3;
BA_ "GenSigSendType" SG_ 1079 Rba_D_Stat 3;
BA_ "GenSigStartValue" SG_ 1079 Rba_D_Stat 1;
BA_ "GenSigStartValueInteger" SG_ 1079 Rba_D_Stat 1;
BA_ "GenSigSendType" SG_ 1079 BalrSwtch_D_Stat 3;
BA_ "GenSigStartValue" SG_ 1079 BalrSwtch_D_Stat 1;
BA_ "GenSigStartValueInteger" SG_ 1079 BalrSwtch_D_Stat 1;
BA_ "GenSigSendType" SG_ 1079 BalrMde_D_Rq 3;
BA_ "U_CX727_MY2021_Rx" SG_ 1079 ChrgGoTTouchEnbl_B_Rq 1;
BA_ "U_U611_U625_MY20_Phev_Rx" SG_ 1079 ChrgGoTTouchEnbl_B_Rq 1;
BA_ "U_CX482_CX483_MY20_Rx" SG_ 1079 ChrgGoTTouchEnbl_B_Rq 1;
BA_ "U_U611_U625_MY20_Hev_Rx" SG_ 1079 ChrgGoTTouchEnbl_B_Rq 1;
BA_ "U_U611_U625_MY20_Gas_Rx" SG_ 1079 ChrgGoTTouchEnbl_B_Rq 1;
BA_ "GenSigSendType" SG_ 1079 ChrgGoTTouchEnbl_B_Rq 3;
BA_ "U_CX727_MY2021_Rx" SG_ 1079 ChrgGoTExtHtrEnbl_B_Rq 1;
BA_ "U_U611_U625_MY20_Phev_Rx" SG_ 1079 ChrgGoTExtHtrEnbl_B_Rq 1;
BA_ "U_CX482_CX483_MY20_Rx" SG_ 1079 ChrgGoTExtHtrEnbl_B_Rq 1;
BA_ "U_U611_U625_MY20_Hev_Rx" SG_ 1079 ChrgGoTExtHtrEnbl_B_Rq 1;
BA_ "U_U611_U625_MY20_Gas_Rx" SG_ 1079 ChrgGoTExtHtrEnbl_B_Rq 1;
BA_ "GenSigSendType" SG_ 1079 ChrgGoTExtHtrEnbl_B_Rq 3;
BA_ "GenSigSendType" SG_ 1079 ChrgGoTTouchEnbl_B_Rq_UB 3;
BA_ "U_CX727_MY2021_Rx" SG_ 1079 ChrgGoTTouchEnbl_B_Rq_UB 1;
BA_ "U_U611_U625_MY20_Phev_Rx" SG_ 1079 ChrgGoTTouchEnbl_B_Rq_UB 1;
BA_ "U_CX482_CX483_MY20_Rx" SG_ 1079 ChrgGoTTouchEnbl_B_Rq_UB 1;
BA_ "U_U611_U625_MY20_Hev_Rx" SG_ 1079 ChrgGoTTouchEnbl_B_Rq_UB 1;
BA_ "U_U611_U625_MY20_Gas_Rx" SG_ 1079 ChrgGoTTouchEnbl_B_Rq_UB 1;
BA_ "GenSigSendType" SG_ 1079 ChrgGoTExtHtrEnbl_B_Rq_UB 3;
BA_ "U_CX727_MY2021_Rx" SG_ 1079 ChrgGoTExtHtrEnbl_B_Rq_UB 1;
BA_ "U_U611_U625_MY20_Phev_Rx" SG_ 1079 ChrgGoTExtHtrEnbl_B_Rq_UB 1;
BA_ "U_CX482_CX483_MY20_Rx" SG_ 1079 ChrgGoTExtHtrEnbl_B_Rq_UB 1;
BA_ "U_U611_U625_MY20_Hev_Rx" SG_ 1079 ChrgGoTExtHtrEnbl_B_Rq_UB 1;
BA_ "U_U611_U625_MY20_Gas_Rx" SG_ 1079 ChrgGoTExtHtrEnbl_B_Rq_UB 1;
BA_ "GenSigSendType" SG_ 1079 LcwaAlrtRight_B_Rq 3;
BA_ "GenSigSendType" SG_ 1079 LcwaAlrtLeft_B_Rq 3;
BA_ "U_CX727_MY2021_Rx" SG_ 1079 ApaSteScanMde_D_Stat 1;
BA_ "U_U611_U625_MY20_Phev_Rx" SG_ 1079 ApaSteScanMde_D_Stat 1;
BA_ "U_CX482_CX483_MY20_Rx" SG_ 1079 ApaSteScanMde_D_Stat 1;
BA_ "U_U611_U625_MY20_Hev_Rx" SG_ 1079 ApaSteScanMde_D_Stat 1;
BA_ "U_U611_U625_MY20_Gas_Rx" SG_ 1079 ApaSteScanMde_D_Stat 1;
BA_ "U_C519_MY18_5_Gas_Rx" SG_ 1079 ApaSteScanMde_D_Stat 1;
BA_ "U_C519_MY18_5_Diesel_Rx" SG_ 1079 ApaSteScanMde_D_Stat 1;
BA_ "GenSigSendType" SG_ 1079 ApaSteScanMde_D_Stat 3;
BA_ "U_CX727_MY2021_Rx" SG_ 1079 ApaSteScanMde_D_Stat_UB 1;
BA_ "U_U611_U625_MY20_Phev_Rx" SG_ 1079 ApaSteScanMde_D_Stat_UB 1;
BA_ "U_CX482_CX483_MY20_Rx" SG_ 1079 ApaSteScanMde_D_Stat_UB 1;
BA_ "U_U611_U625_MY20_Hev_Rx" SG_ 1079 ApaSteScanMde_D_Stat_UB 1;
BA_ "U_U611_U625_MY20_Gas_Rx" SG_ 1079 ApaSteScanMde_D_Stat_UB 1;
BA_ "U_C519_MY18_5_Gas_Rx" SG_ 1079 ApaSteScanMde_D_Stat_UB 1;
BA_ "U_C519_MY18_5_Diesel_Rx" SG_ 1079 ApaSteScanMde_D_Stat_UB 1;
BA_ "GenSigSendType" SG_ 1079 TrlrAidMsgTxt_D2_Rq 3;
BA_ "GenSigSendType" SG_ 1079 HybMdeStat_D_Dsply 3;
BA_ "U_CX727_MY2021_Tx" SG_ 941 CtaTrgtRightY_V_Actl 1;
BA_ "U_CX430_MY2021_Tx" SG_ 941 CtaTrgtRightY_V_Actl 1;
BA_ "U_U611_U625_MY20_Phev_Tx" SG_ 941 CtaTrgtRightY_V_Actl 1;
BA_ "U_CX482_CX483_MY20_Tx" SG_ 941 CtaTrgtRightY_V_Actl 1;
BA_ "U_U611_U625_MY20_Hev_Tx" SG_ 941 CtaTrgtRightY_V_Actl 1;
BA_ "U_U611_U625_MY20_Gas_Tx" SG_ 941 CtaTrgtRightY_V_Actl 1;
BA_ "U_C519_MY18_5_Gas_Tx" SG_ 941 CtaTrgtRightY_V_Actl 1;
BA_ "U_C519_MY18_5_Diesel_Tx" SG_ 941 CtaTrgtRightY_V_Actl 1;
BA_ "U_B515_MCA_MY17_Gas_Tx" SG_ 941 CtaTrgtRightY_V_Actl 1;
BA_ "U_B515_MCA_MY17_Diesel_Tx" SG_ 941 CtaTrgtRightY_V_Actl 1;
BA_ "U_B479_MY17_Diesel_Tx" SG_ 941 CtaTrgtRightY_V_Actl 1;
BA_ "U_B479_MY17_Gas_Tx" SG_ 941 CtaTrgtRightY_V_Actl 1;
BA_ "U_CX727_MY2021_Rx" SG_ 941 CtaTrgtRightY_V_Actl 1;
BA_ "U_CX430_MY2021_Rx" SG_ 941 CtaTrgtRightY_V_Actl 1;
BA_ "U_U611_U625_MY20_Phev_Rx" SG_ 941 CtaTrgtRightY_V_Actl 1;
BA_ "U_CX482_CX483_MY20_Rx" SG_ 941 CtaTrgtRightY_V_Actl 1;
BA_ "U_U611_U625_MY20_Hev_Rx" SG_ 941 CtaTrgtRightY_V_Actl 1;
BA_ "U_U611_U625_MY20_Gas_Rx" SG_ 941 CtaTrgtRightY_V_Actl 1;
BA_ "U_C519_MY18_5_Gas_Rx" SG_ 941 CtaTrgtRightY_V_Actl 1;
BA_ "U_C519_MY18_5_Diesel_Rx" SG_ 941 CtaTrgtRightY_V_Actl 1;
BA_ "U_B515_MCA_MY17_Gas_Rx" SG_ 941 CtaTrgtRightY_V_Actl 1;
BA_ "U_B515_MCA_MY17_Diesel_Rx" SG_ 941 CtaTrgtRightY_V_Actl 1;
BA_ "U_B479_MY17_Diesel_Rx" SG_ 941 CtaTrgtRightY_V_Actl 1;
BA_ "U_B479_MY17_Gas_Rx" SG_ 941 CtaTrgtRightY_V_Actl 1;
BA_ "GenSigStartValueInteger" SG_ 941 CtaTrgtRightY_V_Actl 32767;
BA_ "U_CX727_MY2021_Tx" SG_ 941 CtaTrgtRightY_L_Actl 1;
BA_ "U_CX430_MY2021_Tx" SG_ 941 CtaTrgtRightY_L_Actl 1;
BA_ "U_U611_U625_MY20_Phev_Tx" SG_ 941 CtaTrgtRightY_L_Actl 1;
BA_ "U_CX482_CX483_MY20_Tx" SG_ 941 CtaTrgtRightY_L_Actl 1;
BA_ "U_U611_U625_MY20_Hev_Tx" SG_ 941 CtaTrgtRightY_L_Actl 1;
BA_ "U_U611_U625_MY20_Gas_Tx" SG_ 941 CtaTrgtRightY_L_Actl 1;
BA_ "U_C519_MY18_5_Gas_Tx" SG_ 941 CtaTrgtRightY_L_Actl 1;
BA_ "U_C519_MY18_5_Diesel_Tx" SG_ 941 CtaTrgtRightY_L_Actl 1;
BA_ "U_B515_MCA_MY17_Gas_Tx" SG_ 941 CtaTrgtRightY_L_Actl 1;
BA_ "U_B515_MCA_MY17_Diesel_Tx" SG_ 941 CtaTrgtRightY_L_Actl 1;
BA_ "U_B479_MY17_Diesel_Tx" SG_ 941 CtaTrgtRightY_L_Actl 1;
BA_ "U_B479_MY17_Gas_Tx" SG_ 941 CtaTrgtRightY_L_Actl 1;
BA_ "U_CX727_MY2021_Rx" SG_ 941 CtaTrgtRightY_L_Actl 1;
BA_ "U_CX430_MY2021_Rx" SG_ 941 CtaTrgtRightY_L_Actl 1;
BA_ "U_U611_U625_MY20_Phev_Rx" SG_ 941 CtaTrgtRightY_L_Actl 1;
BA_ "U_CX482_CX483_MY20_Rx" SG_ 941 CtaTrgtRightY_L_Actl 1;
BA_ "U_U611_U625_MY20_Hev_Rx" SG_ 941 CtaTrgtRightY_L_Actl 1;
BA_ "U_U611_U625_MY20_Gas_Rx" SG_ 941 CtaTrgtRightY_L_Actl 1;
BA_ "U_C519_MY18_5_Gas_Rx" SG_ 941 CtaTrgtRightY_L_Actl 1;
BA_ "U_C519_MY18_5_Diesel_Rx" SG_ 941 CtaTrgtRightY_L_Actl 1;
BA_ "U_B515_MCA_MY17_Gas_Rx" SG_ 941 CtaTrgtRightY_L_Actl 1;
BA_ "U_B515_MCA_MY17_Diesel_Rx" SG_ 941 CtaTrgtRightY_L_Actl 1;
BA_ "U_B479_MY17_Diesel_Rx" SG_ 941 CtaTrgtRightY_L_Actl 1;
BA_ "U_B479_MY17_Gas_Rx" SG_ 941 CtaTrgtRightY_L_Actl 1;
BA_ "GenSigStartValueInteger" SG_ 941 CtaTrgtRightY_L_Actl 32767;
BA_ "U_CX727_MY2021_Tx" SG_ 941 CtaTrgtRightX_V_Actl 1;
BA_ "U_CX430_MY2021_Tx" SG_ 941 CtaTrgtRightX_V_Actl 1;
BA_ "U_U611_U625_MY20_Phev_Tx" SG_ 941 CtaTrgtRightX_V_Actl 1;
BA_ "U_CX482_CX483_MY20_Tx" SG_ 941 CtaTrgtRightX_V_Actl 1;
BA_ "U_U611_U625_MY20_Hev_Tx" SG_ 941 CtaTrgtRightX_V_Actl 1;
BA_ "U_U611_U625_MY20_Gas_Tx" SG_ 941 CtaTrgtRightX_V_Actl 1;
BA_ "U_C519_MY18_5_Gas_Tx" SG_ 941 CtaTrgtRightX_V_Actl 1;
BA_ "U_C519_MY18_5_Diesel_Tx" SG_ 941 CtaTrgtRightX_V_Actl 1;
BA_ "U_B515_MCA_MY17_Gas_Tx" SG_ 941 CtaTrgtRightX_V_Actl 1;
BA_ "U_B515_MCA_MY17_Diesel_Tx" SG_ 941 CtaTrgtRightX_V_Actl 1;
BA_ "U_B479_MY17_Diesel_Tx" SG_ 941 CtaTrgtRightX_V_Actl 1;
BA_ "U_B479_MY17_Gas_Tx" SG_ 941 CtaTrgtRightX_V_Actl 1;
BA_ "U_CX727_MY2021_Rx" SG_ 941 CtaTrgtRightX_V_Actl 1;
BA_ "U_CX430_MY2021_Rx" SG_ 941 CtaTrgtRightX_V_Actl 1;
BA_ "U_U611_U625_MY20_Phev_Rx" SG_ 941 CtaTrgtRightX_V_Actl 1;
BA_ "U_CX482_CX483_MY20_Rx" SG_ 941 CtaTrgtRightX_V_Actl 1;
BA_ "U_U611_U625_MY20_Hev_Rx" SG_ 941 CtaTrgtRightX_V_Actl 1;
BA_ "U_U611_U625_MY20_Gas_Rx" SG_ 941 CtaTrgtRightX_V_Actl 1;
BA_ "U_C519_MY18_5_Gas_Rx" SG_ 941 CtaTrgtRightX_V_Actl 1;
BA_ "U_C519_MY18_5_Diesel_Rx" SG_ 941 CtaTrgtRightX_V_Actl 1;
BA_ "U_B515_MCA_MY17_Gas_Rx" SG_ 941 CtaTrgtRightX_V_Actl 1;
BA_ "U_B515_MCA_MY17_Diesel_Rx" SG_ 941 CtaTrgtRightX_V_Actl 1;
BA_ "U_B479_MY17_Diesel_Rx" SG_ 941 CtaTrgtRightX_V_Actl 1;
BA_ "U_B479_MY17_Gas_Rx" SG_ 941 CtaTrgtRightX_V_Actl 1;
BA_ "GenSigStartValueInteger" SG_ 941 CtaTrgtRightX_V_Actl 32767;
BA_ "U_CX727_MY2021_Tx" SG_ 941 CtaTrgtRightX_L_Actl 1;
BA_ "U_CX430_MY2021_Tx" SG_ 941 CtaTrgtRightX_L_Actl 1;
BA_ "U_U611_U625_MY20_Phev_Tx" SG_ 941 CtaTrgtRightX_L_Actl 1;
BA_ "U_CX482_CX483_MY20_Tx" SG_ 941 CtaTrgtRightX_L_Actl 1;
BA_ "U_U611_U625_MY20_Hev_Tx" SG_ 941 CtaTrgtRightX_L_Actl 1;
BA_ "U_U611_U625_MY20_Gas_Tx" SG_ 941 CtaTrgtRightX_L_Actl 1;
BA_ "U_C519_MY18_5_Gas_Tx" SG_ 941 CtaTrgtRightX_L_Actl 1;
BA_ "U_C519_MY18_5_Diesel_Tx" SG_ 941 CtaTrgtRightX_L_Actl 1;
BA_ "U_B515_MCA_MY17_Gas_Tx" SG_ 941 CtaTrgtRightX_L_Actl 1;
BA_ "U_B515_MCA_MY17_Diesel_Tx" SG_ 941 CtaTrgtRightX_L_Actl 1;
BA_ "U_B479_MY17_Diesel_Tx" SG_ 941 CtaTrgtRightX_L_Actl 1;
BA_ "U_B479_MY17_Gas_Tx" SG_ 941 CtaTrgtRightX_L_Actl 1;
BA_ "U_CX727_MY2021_Rx" SG_ 941 CtaTrgtRightX_L_Actl 1;
BA_ "U_CX430_MY2021_Rx" SG_ 941 CtaTrgtRightX_L_Actl 1;
BA_ "U_U611_U625_MY20_Phev_Rx" SG_ 941 CtaTrgtRightX_L_Actl 1;
BA_ "U_CX482_CX483_MY20_Rx" SG_ 941 CtaTrgtRightX_L_Actl 1;
BA_ "U_U611_U625_MY20_Hev_Rx" SG_ 941 CtaTrgtRightX_L_Actl 1;
BA_ "U_U611_U625_MY20_Gas_Rx" SG_ 941 CtaTrgtRightX_L_Actl 1;
BA_ "U_C519_MY18_5_Gas_Rx" SG_ 941 CtaTrgtRightX_L_Actl 1;
BA_ "U_C519_MY18_5_Diesel_Rx" SG_ 941 CtaTrgtRightX_L_Actl 1;
BA_ "U_B515_MCA_MY17_Gas_Rx" SG_ 941 CtaTrgtRightX_L_Actl 1;
BA_ "U_B515_MCA_MY17_Diesel_Rx" SG_ 941 CtaTrgtRightX_L_Actl 1;
BA_ "U_B479_MY17_Diesel_Rx" SG_ 941 CtaTrgtRightX_L_Actl 1;
BA_ "U_B479_MY17_Gas_Rx" SG_ 941 CtaTrgtRightX_L_Actl 1;
BA_ "GenSigStartValueInteger" SG_ 941 CtaTrgtRightX_L_Actl 56174;
BA_ "U_CX727_MY2021_Tx" SG_ 940 CtaTrgtLeftY_V_Actl 1;
BA_ "U_CX430_MY2021_Tx" SG_ 940 CtaTrgtLeftY_V_Actl 1;
BA_ "U_U611_U625_MY20_Phev_Tx" SG_ 940 CtaTrgtLeftY_V_Actl 1;
BA_ "U_CX482_CX483_MY20_Tx" SG_ 940 CtaTrgtLeftY_V_Actl 1;
BA_ "U_U611_U625_MY20_Hev_Tx" SG_ 940 CtaTrgtLeftY_V_Actl 1;
BA_ "U_U611_U625_MY20_Gas_Tx" SG_ 940 CtaTrgtLeftY_V_Actl 1;
BA_ "U_C519_MY18_5_Gas_Tx" SG_ 940 CtaTrgtLeftY_V_Actl 1;
BA_ "U_C519_MY18_5_Diesel_Tx" SG_ 940 CtaTrgtLeftY_V_Actl 1;
BA_ "U_B515_MCA_MY17_Gas_Tx" SG_ 940 CtaTrgtLeftY_V_Actl 1;
BA_ "U_B515_MCA_MY17_Diesel_Tx" SG_ 940 CtaTrgtLeftY_V_Actl 1;
BA_ "U_B479_MY17_Diesel_Tx" SG_ 940 CtaTrgtLeftY_V_Actl 1;
BA_ "U_B479_MY17_Gas_Tx" SG_ 940 CtaTrgtLeftY_V_Actl 1;
BA_ "U_CX727_MY2021_Rx" SG_ 940 CtaTrgtLeftY_V_Actl 1;
BA_ "U_CX430_MY2021_Rx" SG_ 940 CtaTrgtLeftY_V_Actl 1;
BA_ "U_U611_U625_MY20_Phev_Rx" SG_ 940 CtaTrgtLeftY_V_Actl 1;
BA_ "U_CX482_CX483_MY20_Rx" SG_ 940 CtaTrgtLeftY_V_Actl 1;
BA_ "U_U611_U625_MY20_Hev_Rx" SG_ 940 CtaTrgtLeftY_V_Actl 1;
BA_ "U_U611_U625_MY20_Gas_Rx" SG_ 940 CtaTrgtLeftY_V_Actl 1;
BA_ "U_C519_MY18_5_Gas_Rx" SG_ 940 CtaTrgtLeftY_V_Actl 1;
BA_ "U_C519_MY18_5_Diesel_Rx" SG_ 940 CtaTrgtLeftY_V_Actl 1;
BA_ "U_B515_MCA_MY17_Gas_Rx" SG_ 940 CtaTrgtLeftY_V_Actl 1;
BA_ "U_B515_MCA_MY17_Diesel_Rx" SG_ 940 CtaTrgtLeftY_V_Actl 1;
BA_ "U_B479_MY17_Diesel_Rx" SG_ 940 CtaTrgtLeftY_V_Actl 1;
BA_ "U_B479_MY17_Gas_Rx" SG_ 940 CtaTrgtLeftY_V_Actl 1;
BA_ "GenSigStartValueInteger" SG_ 940 CtaTrgtLeftY_V_Actl 32767;
BA_ "U_CX727_MY2021_Tx" SG_ 940 CtaTrgtLeftY_L_Actl 1;
BA_ "U_CX430_MY2021_Tx" SG_ 940 CtaTrgtLeftY_L_Actl 1;
BA_ "U_U611_U625_MY20_Phev_Tx" SG_ 940 CtaTrgtLeftY_L_Actl 1;
BA_ "U_CX482_CX483_MY20_Tx" SG_ 940 CtaTrgtLeftY_L_Actl 1;
BA_ "U_U611_U625_MY20_Hev_Tx" SG_ 940 CtaTrgtLeftY_L_Actl 1;
BA_ "U_U611_U625_MY20_Gas_Tx" SG_ 940 CtaTrgtLeftY_L_Actl 1;
BA_ "U_C519_MY18_5_Gas_Tx" SG_ 940 CtaTrgtLeftY_L_Actl 1;
BA_ "U_C519_MY18_5_Diesel_Tx" SG_ 940 CtaTrgtLeftY_L_Actl 1;
BA_ "U_B515_MCA_MY17_Gas_Tx" SG_ 940 CtaTrgtLeftY_L_Actl 1;
BA_ "U_B515_MCA_MY17_Diesel_Tx" SG_ 940 CtaTrgtLeftY_L_Actl 1;
BA_ "U_B479_MY17_Diesel_Tx" SG_ 940 CtaTrgtLeftY_L_Actl 1;
BA_ "U_B479_MY17_Gas_Tx" SG_ 940 CtaTrgtLeftY_L_Actl 1;
BA_ "U_CX727_MY2021_Rx" SG_ 940 CtaTrgtLeftY_L_Actl 1;
BA_ "U_CX430_MY2021_Rx" SG_ 940 CtaTrgtLeftY_L_Actl 1;
BA_ "U_U611_U625_MY20_Phev_Rx" SG_ 940 CtaTrgtLeftY_L_Actl 1;
BA_ "U_CX482_CX483_MY20_Rx" SG_ 940 CtaTrgtLeftY_L_Actl 1;
BA_ "U_U611_U625_MY20_Hev_Rx" SG_ 940 CtaTrgtLeftY_L_Actl 1;
BA_ "U_U611_U625_MY20_Gas_Rx" SG_ 940 CtaTrgtLeftY_L_Actl 1;
BA_ "U_C519_MY18_5_Gas_Rx" SG_ 940 CtaTrgtLeftY_L_Actl 1;
BA_ "U_C519_MY18_5_Diesel_Rx" SG_ 940 CtaTrgtLeftY_L_Actl 1;
BA_ "U_B515_MCA_MY17_Gas_Rx" SG_ 940 CtaTrgtLeftY_L_Actl 1;
BA_ "U_B515_MCA_MY17_Diesel_Rx" SG_ 940 CtaTrgtLeftY_L_Actl 1;
BA_ "U_B479_MY17_Diesel_Rx" SG_ 940 CtaTrgtLeftY_L_Actl 1;
BA_ "U_B479_MY17_Gas_Rx" SG_ 940 CtaTrgtLeftY_L_Actl 1;
BA_ "GenSigStartValueInteger" SG_ 940 CtaTrgtLeftY_L_Actl 32767;
BA_ "U_CX727_MY2021_Tx" SG_ 940 CtaTrgtLeftX_V_Actl 1;
BA_ "U_CX430_MY2021_Tx" SG_ 940 CtaTrgtLeftX_V_Actl 1;
BA_ "U_U611_U625_MY20_Phev_Tx" SG_ 940 CtaTrgtLeftX_V_Actl 1;
BA_ "U_CX482_CX483_MY20_Tx" SG_ 940 CtaTrgtLeftX_V_Actl 1;
BA_ "U_U611_U625_MY20_Hev_Tx" SG_ 940 CtaTrgtLeftX_V_Actl 1;
BA_ "U_U611_U625_MY20_Gas_Tx" SG_ 940 CtaTrgtLeftX_V_Actl 1;
BA_ "U_C519_MY18_5_Gas_Tx" SG_ 940 CtaTrgtLeftX_V_Actl 1;
BA_ "U_C519_MY18_5_Diesel_Tx" SG_ 940 CtaTrgtLeftX_V_Actl 1;
BA_ "U_B515_MCA_MY17_Gas_Tx" SG_ 940 CtaTrgtLeftX_V_Actl 1;
BA_ "U_B515_MCA_MY17_Diesel_Tx" SG_ 940 CtaTrgtLeftX_V_Actl 1;
BA_ "U_B479_MY17_Diesel_Tx" SG_ 940 CtaTrgtLeftX_V_Actl 1;
BA_ "U_B479_MY17_Gas_Tx" SG_ 940 CtaTrgtLeftX_V_Actl 1;
BA_ "U_CX727_MY2021_Rx" SG_ 940 CtaTrgtLeftX_V_Actl 1;
BA_ "U_CX430_MY2021_Rx" SG_ 940 CtaTrgtLeftX_V_Actl 1;
BA_ "U_U611_U625_MY20_Phev_Rx" SG_ 940 CtaTrgtLeftX_V_Actl 1;
BA_ "U_CX482_CX483_MY20_Rx" SG_ 940 CtaTrgtLeftX_V_Actl 1;
BA_ "U_U611_U625_MY20_Hev_Rx" SG_ 940 CtaTrgtLeftX_V_Actl 1;
BA_ "U_U611_U625_MY20_Gas_Rx" SG_ 940 CtaTrgtLeftX_V_Actl 1;
BA_ "U_C519_MY18_5_Gas_Rx" SG_ 940 CtaTrgtLeftX_V_Actl 1;
BA_ "U_C519_MY18_5_Diesel_Rx" SG_ 940 CtaTrgtLeftX_V_Actl 1;
BA_ "U_B515_MCA_MY17_Gas_Rx" SG_ 940 CtaTrgtLeftX_V_Actl 1;
BA_ "U_B515_MCA_MY17_Diesel_Rx" SG_ 940 CtaTrgtLeftX_V_Actl 1;
BA_ "U_B479_MY17_Diesel_Rx" SG_ 940 CtaTrgtLeftX_V_Actl 1;
BA_ "U_B479_MY17_Gas_Rx" SG_ 940 CtaTrgtLeftX_V_Actl 1;
BA_ "GenSigStartValueInteger" SG_ 940 CtaTrgtLeftX_V_Actl 32767;
BA_ "U_CX727_MY2021_Tx" SG_ 940 CtaTrgtLeftX_L_Actl 1;
BA_ "U_CX430_MY2021_Tx" SG_ 940 CtaTrgtLeftX_L_Actl 1;
BA_ "U_U611_U625_MY20_Phev_Tx" SG_ 940 CtaTrgtLeftX_L_Actl 1;
BA_ "U_CX482_CX483_MY20_Tx" SG_ 940 CtaTrgtLeftX_L_Actl 1;
BA_ "U_U611_U625_MY20_Hev_Tx" SG_ 940 CtaTrgtLeftX_L_Actl 1;
BA_ "U_U611_U625_MY20_Gas_Tx" SG_ 940 CtaTrgtLeftX_L_Actl 1;
BA_ "U_C519_MY18_5_Gas_Tx" SG_ 940 CtaTrgtLeftX_L_Actl 1;
BA_ "U_C519_MY18_5_Diesel_Tx" SG_ 940 CtaTrgtLeftX_L_Actl 1;
BA_ "U_B515_MCA_MY17_Gas_Tx" SG_ 940 CtaTrgtLeftX_L_Actl 1;
BA_ "U_B515_MCA_MY17_Diesel_Tx" SG_ 940 CtaTrgtLeftX_L_Actl 1;
BA_ "U_B479_MY17_Diesel_Tx" SG_ 940 CtaTrgtLeftX_L_Actl 1;
BA_ "U_B479_MY17_Gas_Tx" SG_ 940 CtaTrgtLeftX_L_Actl 1;
BA_ "U_CX727_MY2021_Rx" SG_ 940 CtaTrgtLeftX_L_Actl 1;
BA_ "U_CX430_MY2021_Rx" SG_ 940 CtaTrgtLeftX_L_Actl 1;
BA_ "U_U611_U625_MY20_Phev_Rx" SG_ 940 CtaTrgtLeftX_L_Actl 1;
BA_ "U_CX482_CX483_MY20_Rx" SG_ 940 CtaTrgtLeftX_L_Actl 1;
BA_ "U_U611_U625_MY20_Hev_Rx" SG_ 940 CtaTrgtLeftX_L_Actl 1;
BA_ "U_U611_U625_MY20_Gas_Rx" SG_ 940 CtaTrgtLeftX_L_Actl 1;
BA_ "U_C519_MY18_5_Gas_Rx" SG_ 940 CtaTrgtLeftX_L_Actl 1;
BA_ "U_C519_MY18_5_Diesel_Rx" SG_ 940 CtaTrgtLeftX_L_Actl 1;
BA_ "U_B515_MCA_MY17_Gas_Rx" SG_ 940 CtaTrgtLeftX_L_Actl 1;
BA_ "U_B515_MCA_MY17_Diesel_Rx" SG_ 940 CtaTrgtLeftX_L_Actl 1;
BA_ "U_B479_MY17_Diesel_Rx" SG_ 940 CtaTrgtLeftX_L_Actl 1;
BA_ "U_B479_MY17_Gas_Rx" SG_ 940 CtaTrgtLeftX_L_Actl 1;
BA_ "GenSigStartValueInteger" SG_ 940 CtaTrgtLeftX_L_Actl 56174;
VAL_ 877 AAR_Btn_Stt 3 "Unused" 2 "Disabled" 1 "Active" 0 "Enabled_Inactive" ;
VAL_ 917 PrkAsstSlotId_D_Stat 7 "Faulty" 6 "Slot6" 5 "Slot5" 4 "Slot4" 3 "Slot3" 2 "Slot2" 1 "Slot1" 0 "NoSlotFound" ;
VAL_ 1067 ElCmpr_N_Actl_UB 1 "Fresh_data" 0 "Unchanged_data" ;
VAL_ 1067 ElCmpr_D_Stat_UB 1 "Fresh_data" 0 "Unchanged_data" ;
VAL_ 1067 ElCmpr_N_Actl 255 "Invalid" ;
VAL_ 1067 ElCmpr_D_Stat 7 "Signal_Invalid" 6 "Comp_Off_ActlSpd_Abnormal" 5 "Comp_Off_TrgtSpd_OutRange" 4 "Comp_Shutdown" 3 "Comp_Stopped_Self_Protect" 2 "Comp_Degraded" 1 "Comp_On" 0 "Comp_Off" ;
VAL_ 838 FohStrtDay_T_Rq 7 "Sunday" 6 "Saturday" 5 "Friday" 4 "Thursday" 3 "Wednesday" 2 "Tuesday" 1 "Monday" 0 "NotUsed" ;
VAL_ 838 FohStop_B_Rq 3 "Unknown" 2 "NotUsed" 1 "Enable" 0 "Disable" ;
VAL_ 838 FohTAllEnable_B_Rq 3 "Unknown" 2 "NotUsed" 1 "Enable" 0 "Disable" ;
VAL_ 838 FohT2Enable_B_Rq 1 "Enable" 0 "Disable" ;
VAL_ 838 FohT1Enable_B_Rq 1 "Enable" 0 "Disable" ;
VAL_ 838 FohStrtEnable_B_Rq 1 "Enable" 0 "Disable" ;
VAL_ 838 FohContOn_B_Rq 3 "Unknown" 2 "NotUsed" 1 "Enable" 0 "Disable" ;
VAL_ 773 SeatScrnPsngrOn_B_Rq 1 "On" 0 "Off" ;
VAL_ 796 BattULoState_D_Qlty 3 "OK" 2 "Not_Within_Specifications" 1 "Eval_In_Progress" 0 "Fault" ;
VAL_ 796 BSFault 1 "Fault" 0 "No_Fault" ;
VAL_ 796 BattULo2_Te_Actl 127 "Fault" ;
VAL_ 883 PmCabn10Mnte_Conc_Actl 511 "Faulty" 510 "NoDataExists" ;
VAL_ 883 PmCabn08Mnte_Conc_Actl 511 "Faulty" 510 "NoDataExists" ;
VAL_ 883 PmCabn06Mnte_Conc_Actl 511 "Faulty" 510 "NoDataExists" ;
VAL_ 883 PmCabn04Mnte_Conc_Actl 511 "Faulty" 510 "NoDataExists" ;
VAL_ 883 PmCabn02Mnte_Conc_Actl 511 "Faulty" 510 "NoDataExists" ;
VAL_ 884 UltraFreshCabn_D_Stat 7 "NotUsed_2" 6 "NotUsed_1" 5 "NotSupported" 4 "Interrupted" 3 "Complete" 2 "Active" 1 "Inactive" 0 "Null" ;
VAL_ 884 PmSnsCabn_D_Stat 7 "NotUsed_1" 6 "IntermittentInhibit" 5 "NoIssue" 4 "BlankField" 3 "ReplaceSensor" 2 "CleanSensor" 1 "Unsupported" 0 "Initializing" ;
VAL_ 884 PmCabn_Conc_Actl 511 "Faulty" 510 "NoDataExists" ;
VAL_ 884 PmCabn20Mnte_Conc_Actl 511 "Faulty" 510 "NoDataExists" ;
VAL_ 884 PmCabn18Mnte_Conc_Actl 511 "Faulty" 510 "NoDataExists" ;
VAL_ 884 PmCabn16Mnte_Conc_Actl 511 "Faulty" 510 "NoDataExists" ;
VAL_ 884 PmCabn14Mnte_Conc_Actl 511 "Faulty" 510 "NoDataExists" ;
VAL_ 884 PmCabn12Mnte_Conc_Actl 511 "Faulty" 510 "NoDataExists" ;
VAL_ 841 FohAddHeater_D_Stat 3 "NotUsed" 2 "On" 1 "Off" 0 "NoModeSelected" ;
VAL_ 1075 ACU_RadioSeekMode2_St 16 "ContAutoDown" 15 "ContAutoUp" 14 "PISeek" 13 "TpSeek" 12 "Autostore" 11 "PtySeekDown" 10 "PtySeekUp" 9 "ScanDown" 8 "ScanUp" 7 "ContManualDown" 6 "ContManualUp" 5 "ManSingleStepDown" 4 "ManSingleStepUp" 3 "AutoDown" 2 "AutoUp" 1 "SeekOff" 0 "Invalid" ;
VAL_ 1075 ACU_CurrTUBand_St 10 "SAT2" 9 "SAT1" 8 "DAB2" 7 "DAB1" 6 "Fm3" 5 "AmAst" 4 "Am" 3 "FmAst" 2 "Fm2" 1 "Fm1" 0 "Invalid" 13 "reserved1" 15 "reserved_last" 12 "DAB3" 11 "SAT3" ;
VAL_ 1075 ACU_RadioSeekMode2_St_UB 1 "Fresh_data" 0 "Unchanged_data" ;
VAL_ 1075 ACU_CurrTUBand_St_UB 1 "Fresh_data" 0 "Unchanged_data" ;
VAL_ 1075 ACU_CurrentFreq_St_UB 1 "Fresh_data" 0 "Unchanged_data" ;
VAL_ 1075 CtaBrk_D_Stat_UB 1 "Fresh_data" 0 "Unchanged_data" ;
VAL_ 1075 CtaBrk_D_Stat 3 "Denied" 2 "Active" 1 "Open" 0 "Closed" ;
VAL_ 1075 SelDrvMdePt_D_Rq_UB 1 "Fresh_data" 0 "Unchanged_data" ;
VAL_ 1075 SelDrvMdePt_D_Rq 31 "Faulty" 30 "NotUsed15" 29 "NotUsed14" 28 "NotUsed13" 27 "NotUsed12" 26 "NotUsed11" 25 "NotUsed10" 24 "NotUsed9" 23 "NotUsed8" 22 "NotUsed7" 21 "NotUsed6" 20 "NotUsed5" 19 "NotUsed4" 18 "EvLaterChargerMode" 17 "EvNowMode" 16 "DragMode" 15 "HighSpeedDesertMode_Baja" 14 "SportAdaptiveMode" 13 "NotAvailable_13" 12 "NotAvailable_12" 11 "NotAvailable_11" 10 "NotAvailable_10" 9 "RockCrawlMode" 8 "MudRutsMode" 7 "SandMode" 6 "EconomyMode" 5 "GrassGravelSnow" 4 "NotAvailable_04" 3 "TowHaulMode" 2 "NotAvailable_02" 1 "SportMode" 0 "NormalMode" ;
VAL_ 1075 PrkAidSnsRrCrnr_D_Stat 15 "Zone_15" 14 "Zone_14" 13 "Zone_13" 12 "Zone_12" 11 "Zone_11" 10 "Zone_10" 9 "Zone_9" 8 "Zone_8" 7 "Zone_7" 6 "Zone_6" 5 "Zone_5" 4 "Zone_4" 3 "Zone_3" 2 "Zone_2" 1 "Zone_1" 0 "Off" ;
VAL_ 1075 PrkAidSnsRrCntr_D_Stat 15 "Zone_15" 14 "Zone_14" 13 "Zone_13" 12 "Zone_12" 11 "Zone_11" 10 "Zone_10" 9 "Zone_9" 8 "Zone_8" 7 "Zone_7" 6 "Zone_6" 5 "Zone_5" 4 "Zone_4" 3 "Zone_3" 2 "Zone_2" 1 "Zone_1" 0 "Off" ;
VAL_ 1075 PrkAidSnsRlCrnr_D_Stat 15 "Zone_15" 14 "Zone_14" 13 "Zone_13" 12 "Zone_12" 11 "Zone_11" 10 "Zone_10" 9 "Zone_9" 8 "Zone_8" 7 "Zone_7" 6 "Zone_6" 5 "Zone_5" 4 "Zone_4" 3 "Zone_3" 2 "Zone_2" 1 "Zone_1" 0 "Off" ;
VAL_ 1075 PrkAidSnsRlCntr_D_Stat 15 "Zone_15" 14 "Zone_14" 13 "Zone_13" 12 "Zone_12" 11 "Zone_11" 10 "Zone_10" 9 "Zone_9" 8 "Zone_8" 7 "Zone_7" 6 "Zone_6" 5 "Zone_5" 4 "Zone_4" 3 "Zone_3" 2 "Zone_2" 1 "Zone_1" 0 "Off" ;
VAL_ 1075 PrkAidSnsRrCrnr_D_Stat_UB 1 "Fresh_data" 0 "Unchanged_data" ;
VAL_ 1075 PrkAidSnsRrCntr_D_Stat_UB 1 "Fresh_data" 0 "Unchanged_data" ;
VAL_ 1075 PrkAidSnsRlCntr_D_Stat_UB 1 "Fresh_data" 0 "Unchanged_data" ;
VAL_ 1075 PrkAidSnsRlCrnr_D_Stat_UB 1 "Fresh_data" 0 "Unchanged_data" ;
VAL_ 1075 BttOn_B_Rq_UB 1 "Fresh_data" 0 "Unchanged_data" ;
VAL_ 1075 Btt_L_Actl_UB 1 "Fresh_data" 0 "Unchanged_data" ;
VAL_ 1075 BttOn_B_Rq 1 "On" 0 "Off" ;
VAL_ 1075 Btt_L_Actl 127 "Faulty" 126 "NoDataExists" ;
VAL_ 1075 ArmrestStwdRear_B_Stat_UB 1 "Fresh_data" 0 "Unchanged_data" ;
VAL_ 1075 ArmrestStwdRear_B_Stat 1 "Yes" 0 "No" ;
VAL_ 977 CnvtTopMsgTxt_D_Rq 3 "NotSecure" 2 "NotAvailable" 1 "RemoveCaps" 0 "NoWarning" ;
VAL_ 1045 BrkFluidLvl_D_Stat 3 "Invalid" 2 "Unknown" 1 "Low" 0 "OK" ;
VAL_ 1045 VehVActlBrk_D_Qf 3 "OK" 2 "Not_Within_Specifications" 1 "No_Data_Exists" 0 "Faulty" ;
VAL_ 1079 ApaMde_D_Stat_UB 1 "Fresh_data" 0 "Unchanged_data" ;
VAL_ 1079 ApaMde_D_Stat 7 "NotUsed3" 6 "NotUsed2" 5 "NotUsed1" 4 "POA" 3 "PPA" 2 "SAPP" 1 "Off" 0 "Null" ;
VAL_ 1079 TrlrAidEnbl_D2_Stat_UB 1 "Fresh_data" 0 "Unchanged_data" ;
VAL_ 1079 TrlrAidEnbl_D2_Stat 7 "NotUsed_1" 6 "TbaActiveExpertActive" 5 "TbaActiveExpertAvail" 4 "TbaOffTrgActive" 3 "TbaOffTrgSetup" 2 "TbaSetup" 1 "TbaActive" 0 "Inactive" ;
VAL_ 1079 GenericSwtch3_No_Actl_UB 1 "Fresh_data" 0 "Unchanged_data" ;
VAL_ 1079 GenericSwtch2_No_Actl_UB 1 "Fresh_data" 0 "Unchanged_data" ;
VAL_ 1079 GenericSwtch1_No_Actl_UB 1 "Fresh_data" 0 "Unchanged_data" ;
VAL_ 1079 RbaSys_D_Stat_UB 1 "Fresh_data" 0 "Unchanged_data" ;
VAL_ 1079 RbaSys_D_Stat 3 "Faulty" 2 "Available" 1 "Suspended" 0 "Disabled" ;
VAL_ 1079 HybMdeStat_D_Dsply_UB 1 "Fresh_data" 0 "Unchanged_data" ;
VAL_ 1079 Rba_D_Stat 3 "NotUsed" 2 "Disabled" 1 "On" 0 "Off" ;
VAL_ 1079 Rba_D_Stat_UB 1 "Fresh_data" 0 "Unchanged_data" ;
VAL_ 1079 BalrSwtch_D_Stat 3 "NotUsed" 2 "Pressed" 1 "NotPressed" 0 "Null" ;
VAL_ 1079 BalrMde_D_Rq_UB 1 "Fresh_data" 0 "Unchanged_data" ;
VAL_ 1079 BalrSwtch_D_Stat_UB 1 "Fresh_data" 0 "Unchanged_data" ;
VAL_ 1079 BalrMde_D_Rq 3 "High" 2 "Medium" 1 "Low" 0 "Null" ;
VAL_ 1079 ChrgGoTTouchEnbl_B_Rq 1 "Request" 0 "NoRequest" ;
VAL_ 1079 ChrgGoTExtHtrEnbl_B_Rq 1 "Request" 0 "NoRequest" ;
VAL_ 1079 ChrgGoTTouchEnbl_B_Rq_UB 1 "Fresh_data" 0 "Unchanged_data" ;
VAL_ 1079 ChrgGoTExtHtrEnbl_B_Rq_UB 1 "Fresh_data" 0 "Unchanged_data" ;
VAL_ 1079 LcwaAlrtRight_B_Rq_UB 1 "Fresh_data" 0 "Unchanged_data" ;
VAL_ 1079 LcwaAlrtLeft_B_Rq_UB 1 "Fresh_data" 0 "Unchanged_data" ;
VAL_ 1079 LcwaAlrtRight_B_Rq 1 "Yes" 0 "No" ;
VAL_ 1079 LcwaAlrtLeft_B_Rq 1 "Yes" 0 "No" ;
VAL_ 1079 ApaSteScanMde_D_Stat 3 "Steering" 2 "Scanning" 1 "NotScanning" 0 "Null" ;
VAL_ 1079 ApaSteScanMde_D_Stat_UB 1 "Fresh_data" 0 "Unchanged_data" ;
VAL_ 1079 TrlrAidMsgTxt_D2_Rq_UB 1 "Fresh_data" 0 "Unchanged_data" ;
VAL_ 1079 TrlrAidMsgTxt_D2_Rq 63 "Message63" 62 "Message62" 61 "Message61" 60 "Message60" 55 "Message55" 50 "Message50" 45 "Message45" 40 "Message40" 35 "Message35" 31 "Message31" 30 "Message30" 29 "Message29" 28 "Message28" 27 "Message27" 26 "Message26" 25 "Message25" 24 "Message24" 23 "Message23" 22 "Message22" 21 "Message21" 20 "Message20" 19 "Message19" 18 "Message18" 17 "Message17" 16 "Message16" 15 "Message15" 14 "Message14" 13 "Message13" 12 "Message12" 11 "Message11" 10 "Message10" 9 "Message9" 8 "Message8" 7 "Message7" 6 "Message6" 5 "Message5" 4 "Message4" 3 "Message3" 2 "Message2" 1 "Message1" 0 "NoMessage" ;
VAL_ 1079 HybMdeStat_D_Dsply 7 "NotUsed2" 6 "EV_Charge" 5 "EV_Override" 4 "Forced_EV_Mode" 3 "Forced_Charge_Sustain_Mode" 2 "Auto_Charge_Sustain_Mode" 1 "Auto_Charge_Deplete_Mode" 0 "Null_State" ;
